VERSION ""

NS_ :

BS_:

BU_: Turbocharger OnBoardDataLogger OffBoardDiagnosticTool2 OffBoardDiagnosticTool1 FileServer ParkingBrakeController SeatControl2 FanDriveController SteeringColumnUnit CommunicationUnitRadio CommunicationUnitSatellite CommunicationUnitCellular PropulsionBatteryCharger ChassisController2 ChassisController1 EngineValveControl AuxiliaryHeater2 AuxiliaryHeater1 ClutchUnit RampControl InformationSystem1 SuspensionSystemController2 OilSensor VehicleDynamicStability ExhaustEmissionController TransmissionDisplay2 TransmissionDisplay1 ClimateControl2 WaterPumpController RearAxleSteeringController LightingOperatorControl SeatController1 IgnitionController2 IgnitionController1 TirePressureController CabController2 CabController1 PneumaticSystemController SuspensionSystemController1 HydraulicPumpController EnduranceBrakingSystem RetarderExhaustEngine2 OnBoardDiagnosticUnit HeadwayController RetarderExhaustEngine1 CabDisplay1 ManagementComputer VirtualTerminal OffVehicleGateway PowerTakeOffFront HitchControl AuxiliaryValveControl BodyController TractorTrailerBridge1 StarterSystem ElectricalSystem VehicleSecurity VehicleNavigation AerodynamicControl ElectricalChargingSystem ClimateControl1 TripRecorder InstrumentCluster SuspensionDriveAxle2 SuspensionDriveAxle1 SuspensionSteerAxle SteeringController FuelSystem CruiseControl RetarderDriveline RetarderEngine BrakesDriveAxle2 BrakesDriveAxle1 BrakesSystemController BrakesSteerAxle AxleDrive2 AxleDrive1 AxleSteering PowerTakeOff ShiftConsoleSecondary ShiftConsolePrimary Transmission2 Transmission1 Engine2 Engine1

BO_ 2566845694 TIRE: 8 Vector__XXX
 SG_ TirePressThresholdDetection_13 m19 : 61|3@1+ (1,0) [0|7] "" Vector__XXX
 SG_ TirePressThresholdDetection_12 m18 : 61|3@1+ (1,0) [0|7] "" Vector__XXX
 SG_ TirePressThresholdDetection_11 m17 : 61|3@1+ (1,0) [0|7] "" Vector__XXX
 SG_ TirePressThresholdDetection_10 m16 : 61|3@1+ (1,0) [0|7] "" Vector__XXX
 SG_ TirePressThresholdDetection_01 m1 : 61|3@1+ (1,0) [0|7] "" Vector__XXX
 SG_ TirePress_33 m51 : 8|8@1+ (4,0) [0|1000] "kPa" Vector__XXX
 SG_ TirePress_32 m50 : 8|8@1+ (4,0) [0|1000] "kPa" Vector__XXX
 SG_ TirePress_31 m49 : 8|8@1+ (4,0) [0|1000] "kPa" Vector__XXX
 SG_ TirePress_30 m48 : 8|8@1+ (4,0) [0|1000] "kPa" Vector__XXX
 SG_ TirePress_23 m35 : 8|8@1+ (4,0) [0|1000] "kPa" Vector__XXX
 SG_ TirePress_22 m34 : 8|8@1+ (4,0) [0|1000] "kPa" Vector__XXX
 SG_ TirePress_21 m33 : 8|8@1+ (4,0) [0|1000] "kPa" Vector__XXX
 SG_ TirePress_20 m32 : 8|8@1+ (4,0) [0|1000] "kPa" Vector__XXX
 SG_ TirePress_13 m19 : 8|8@1+ (4,0) [0|1000] "kPa" Vector__XXX
 SG_ TirePress_12 m18 : 8|8@1+ (4,0) [0|1000] "kPa" Vector__XXX
 SG_ TirePress_11 m17 : 8|8@1+ (4,0) [0|1000] "kPa" Vector__XXX
 SG_ TirePress_10 m16 : 8|8@1+ (4,0) [0|1000] "kPa" Vector__XXX
 SG_ TireAirLeakageRate_33 m51 : 40|16@1+ (0.1,0) [0|6425.5] "Pa/s" Vector__XXX
 SG_ TireAirLeakageRate_32 m50 : 40|16@1+ (0.1,0) [0|6425.5] "Pa/s" Vector__XXX
 SG_ TireAirLeakageRate_31 m49 : 40|16@1+ (0.1,0) [0|6425.5] "Pa/s" Vector__XXX
 SG_ TireAirLeakageRate_30 m48 : 40|16@1+ (0.1,0) [0|6425.5] "Pa/s" Vector__XXX
 SG_ TireAirLeakageRate_23 m35 : 40|16@1+ (0.1,0) [0|6425.5] "Pa/s" Vector__XXX
 SG_ TireAirLeakageRate_22 m34 : 40|16@1+ (0.1,0) [0|6425.5] "Pa/s" Vector__XXX
 SG_ TireAirLeakageRate_21 m33 : 40|16@1+ (0.1,0) [0|6425.5] "Pa/s" Vector__XXX
 SG_ TireAirLeakageRate_20 m32 : 40|16@1+ (0.1,0) [0|6425.5] "Pa/s" Vector__XXX
 SG_ TireAirLeakageRate_13 m19 : 40|16@1+ (0.1,0) [0|6425.5] "Pa/s" Vector__XXX
 SG_ TireAirLeakageRate_12 m18 : 40|16@1+ (0.1,0) [0|6425.5] "Pa/s" Vector__XXX
 SG_ TireAirLeakageRate_11 m17 : 40|16@1+ (0.1,0) [0|6425.5] "Pa/s" Vector__XXX
 SG_ TireAirLeakageRate_10 m16 : 40|16@1+ (0.1,0) [0|6425.5] "Pa/s" Vector__XXX
 SG_ TireAirLeakageRate_01 m1 : 40|16@1+ (0.1,0) [0|6425.5] "Pa/s" Vector__XXX
 SG_ TireAirLeakageRate_00 m0 : 40|16@1+ (0.1,0) [0|6425.5] "Pa/s" Vector__XXX
 SG_ CTIWheelSensorStatus_33 m51 : 32|2@1+ (1,0) [0|3] "" Vector__XXX
 SG_ CTIWheelSensorStatus_32 m50 : 32|2@1+ (1,0) [0|3] "" Vector__XXX
 SG_ CTIWheelSensorStatus_31 m49 : 32|2@1+ (1,0) [0|3] "" Vector__XXX
 SG_ CTIWheelSensorStatus_30 m48 : 32|2@1+ (1,0) [0|3] "" Vector__XXX
 SG_ CTIWheelSensorStatus_23 m35 : 32|2@1+ (1,0) [0|3] "" Vector__XXX
 SG_ CTIWheelSensorStatus_22 m34 : 32|2@1+ (1,0) [0|3] "" Vector__XXX
 SG_ CTIWheelSensorStatus_21 m33 : 32|2@1+ (1,0) [0|3] "" Vector__XXX
 SG_ CTIWheelSensorStatus_20 m32 : 32|2@1+ (1,0) [0|3] "" Vector__XXX
 SG_ CTIWheelSensorStatus_13 m19 : 32|2@1+ (1,0) [0|3] "" Vector__XXX
 SG_ CTIWheelSensorStatus_12 m18 : 32|2@1+ (1,0) [0|3] "" Vector__XXX
 SG_ CTIWheelSensorStatus_11 m17 : 32|2@1+ (1,0) [0|3] "" Vector__XXX
 SG_ CTIWheelSensorStatus_10 m16 : 32|2@1+ (1,0) [0|3] "" Vector__XXX
 SG_ CTIWheelSensorStatus_01 m1 : 32|2@1+ (1,0) [0|3] "" Vector__XXX
 SG_ CTIWheelEndElectricalFault_33 m51 : 36|2@1+ (1,0) [0|3] "" Vector__XXX
 SG_ CTIWheelEndElectricalFault_32 m50 : 36|2@1+ (1,0) [0|3] "" Vector__XXX
 SG_ CTIWheelEndElectricalFault_31 m49 : 36|2@1+ (1,0) [0|3] "" Vector__XXX
 SG_ CTIWheelEndElectricalFault_30 m48 : 36|2@1+ (1,0) [0|3] "" Vector__XXX
 SG_ CTIWheelEndElectricalFault_23 m35 : 36|2@1+ (1,0) [0|3] "" Vector__XXX
 SG_ CTIWheelEndElectricalFault_22 m34 : 36|2@1+ (1,0) [0|3] "" Vector__XXX
 SG_ CTIWheelEndElectricalFault_21 m33 : 36|2@1+ (1,0) [0|3] "" Vector__XXX
 SG_ CTIWheelEndElectricalFault_20 m32 : 36|2@1+ (1,0) [0|3] "" Vector__XXX
 SG_ CTIWheelEndElectricalFault_13 m19 : 36|2@1+ (1,0) [0|3] "" Vector__XXX
 SG_ CTIWheelEndElectricalFault_12 m18 : 36|2@1+ (1,0) [0|3] "" Vector__XXX
 SG_ CTIWheelEndElectricalFault_11 m17 : 36|2@1+ (1,0) [0|3] "" Vector__XXX
 SG_ CTIWheelEndElectricalFault_10 m16 : 36|2@1+ (1,0) [0|3] "" Vector__XXX
 SG_ CTIWheelEndElectricalFault_01 m1 : 36|2@1+ (1,0) [0|3] "" Vector__XXX
 SG_ CTITireStatus_33 m51 : 34|2@1+ (1,0) [0|3] "" Vector__XXX
 SG_ CTITireStatus_32 m50 : 34|2@1+ (1,0) [0|3] "" Vector__XXX
 SG_ CTITireStatus_31 m49 : 34|2@1+ (1,0) [0|3] "" Vector__XXX
 SG_ CTITireStatus_30 m48 : 34|2@1+ (1,0) [0|3] "" Vector__XXX
 SG_ CTITireStatus_23 m35 : 34|2@1+ (1,0) [0|3] "" Vector__XXX
 SG_ CTITireStatus_22 m34 : 34|2@1+ (1,0) [0|3] "" Vector__XXX
 SG_ CTITireStatus_21 m33 : 34|2@1+ (1,0) [0|3] "" Vector__XXX
 SG_ CTITireStatus_20 m32 : 34|2@1+ (1,0) [0|3] "" Vector__XXX
 SG_ CTITireStatus_13 m19 : 34|2@1+ (1,0) [0|3] "" Vector__XXX
 SG_ CTITireStatus_12 m18 : 34|2@1+ (1,0) [0|3] "" Vector__XXX
 SG_ CTITireStatus_11 m17 : 34|2@1+ (1,0) [0|3] "" Vector__XXX
 SG_ CTITireStatus_10 m16 : 34|2@1+ (1,0) [0|3] "" Vector__XXX
 SG_ CTITireStatus_01 m1 : 34|2@1+ (1,0) [0|3] "" Vector__XXX
 SG_ TireTemp_11 m17 : 16|16@1+ (0.03125,-273) [-273|1735] "°C" Vector__XXX
 SG_ TireTemp_33 m51 : 16|16@1+ (0.03125,-273) [-273|1735] "°C" Vector__XXX
 SG_ TireTemp_32 m50 : 16|16@1+ (0.03125,-273) [-273|1735] "°C" Vector__XXX
 SG_ TireTemp_31 m49 : 16|16@1+ (0.03125,-273) [-273|1735] "°C" Vector__XXX
 SG_ TireTemp_30 m48 : 16|16@1+ (0.03125,-273) [-273|1735] "°C" Vector__XXX
 SG_ TireTemp_23 m35 : 16|16@1+ (0.03125,-273) [-273|1735] "°C" Vector__XXX
 SG_ TireTemp_22 m34 : 16|16@1+ (0.03125,-273) [-273|1735] "°C" Vector__XXX
 SG_ TireTemp_21 m33 : 16|16@1+ (0.03125,-273) [-273|1735] "°C" Vector__XXX
 SG_ TireTemp_20 m32 : 16|16@1+ (0.03125,-273) [-273|1735] "°C" Vector__XXX
 SG_ TireTemp_13 m19 : 16|16@1+ (0.03125,-273) [-273|1735] "°C" Vector__XXX
 SG_ TireTemp_12 m18 : 16|16@1+ (0.03125,-273) [-273|1735] "°C" Vector__XXX
 SG_ TireTemp_10 m16 : 16|16@1+ (0.03125,-273) [-273|1735] "°C" Vector__XXX
 SG_ TireTemp_01 m1 : 16|16@1+ (0.03125,-273) [-273|1735] "°C" Vector__XXX
 SG_ TireTemp_00 m0 : 16|16@1+ (0.03125,-273) [-273|1735] "°C" Vector__XXX
 SG_ TirePressThresholdDetection_33 m51 : 61|3@1+ (1,0) [0|7] "" Vector__XXX
 SG_ TirePressThresholdDetection_32 m50 : 61|3@1+ (1,0) [0|7] "" Vector__XXX
 SG_ TirePressThresholdDetection_31 m49 : 61|3@1+ (1,0) [0|7] "" Vector__XXX
 SG_ TirePressThresholdDetection_30 m48 : 61|3@1+ (1,0) [0|7] "" Vector__XXX
 SG_ TirePressThresholdDetection_23 m35 : 61|3@1+ (1,0) [0|7] "" Vector__XXX
 SG_ TirePressThresholdDetection_22 m34 : 61|3@1+ (1,0) [0|7] "" Vector__XXX
 SG_ TirePressThresholdDetection_21 m33 : 61|3@1+ (1,0) [0|7] "" Vector__XXX
 SG_ TirePressThresholdDetection_20 m32 : 61|3@1+ (1,0) [0|7] "" Vector__XXX
 SG_ TirePressThresholdDetection_00 m0 : 61|3@1+ (1,0) [0|7] "" Vector__XXX
 SG_ TirePress_01 m1 : 8|8@1+ (4,0) [0|1000] "kPa" Vector__XXX
 SG_ TirePress_00 m0 : 8|8@1+ (4,0) [0|1000] "kPa" Vector__XXX
 SG_ CTIWheelSensorStatus_00 m0 : 32|2@1+ (1,0) [0|3] "" Vector__XXX
 SG_ CTIWheelEndElectricalFault_00 m0 : 36|2@1+ (1,0) [0|3] "" Vector__XXX
 SG_ CTITireStatus_00 m0 : 34|2@1+ (1,0) [0|3] "" Vector__XXX
 SG_ TireLocation M : 0|8@1+ (1,0) [0|255] "" Vector__XXX

BO_ 2633939966 TFI: 16 Vector__XXX
 SG_ TripFanOnTimeDueToAManualSwitch : 64|32@1+ (0.05,0) [0|210554060.75] "hr" Vector__XXX
 SG_ TripFanOnTime : 0|32@1+ (0.05,0) [0|210554060.75] "hr" Vector__XXX
 SG_ TripFanOnTimeDueToA_CSystem : 96|32@1+ (0.05,0) [0|210554060.75] "hr" Vector__XXX
 SG_ TripFanOnTimeDueToEngSystem : 32|32@1+ (0.05,0) [0|210554060.75] "hr" Vector__XXX

BO_ 2633939710 TDI: 12 Vector__XXX
 SG_ TripDistanceInTopGear : 64|32@1+ (0.125,0) [0|526385151.9] "km" Vector__XXX
 SG_ TripGearDownDistance : 32|32@1+ (0.125,0) [0|526385151.9] "km" Vector__XXX
 SG_ TripDistanceOnVSL : 0|32@1+ (0.125,0) [0|526385151.9] "km" Vector__XXX

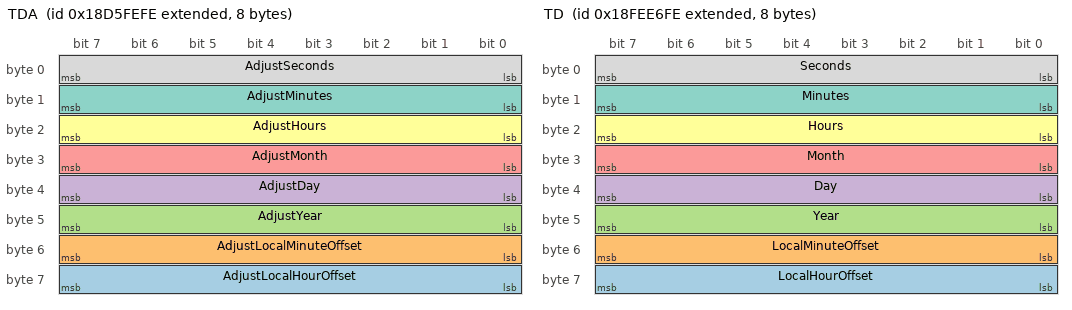
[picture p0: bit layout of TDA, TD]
BO_ 2564161278 TDA: 8 Vector__XXX
 SG_ AdjustLocalHourOffset : 56|8@1+ (1,-125) [-125|125] "hr" Vector__XXX
 SG_ AdjustLocalMinuteOffset : 48|8@1+ (1,-125) [-125|125] "mins" Vector__XXX
 SG_ AdjustYear : 40|8@1+ (1,1985) [1985|2235] "years" Vector__XXX
 SG_ AdjustDay : 32|8@1+ (0.25,0) [0|62.5] "days" Vector__XXX
 SG_ AdjustMonth : 24|8@1+ (1,0) [0|250] "months" Vector__XXX
 SG_ AdjustHours : 16|8@1+ (1,0) [0|250] "hr" Vector__XXX
 SG_ AdjustMinutes : 8|8@1+ (1,0) [0|250] "mins" Vector__XXX
 SG_ AdjustSeconds : 0|8@1+ (0.25,0) [0|62.5] "s" Vector__XXX

BO_ 2566842110 TD: 8 Vector__XXX
 SG_ LocalHourOffset : 56|8@1+ (1,-125) [-125|125] "hr" Vector__XXX
 SG_ LocalMinuteOffset : 48|8@1+ (1,-125) [-125|125] "mins" Vector__XXX
 SG_ Year : 40|8@1+ (1,1985) [1985|2235] "years" Vector__XXX
 SG_ Day : 32|8@1+ (0.25,0) [0|62.5] "days" Vector__XXX
 SG_ Month : 24|8@1+ (1,0) [0|250] "months" Vector__XXX
 SG_ Hours : 16|8@1+ (1,0) [0|250] "hr" Vector__XXX
 SG_ Minutes : 8|8@1+ (1,0) [0|250] "mins" Vector__XXX
 SG_ Seconds : 0|8@1+ (0.25,0) [0|62.5] "s" Vector__XXX

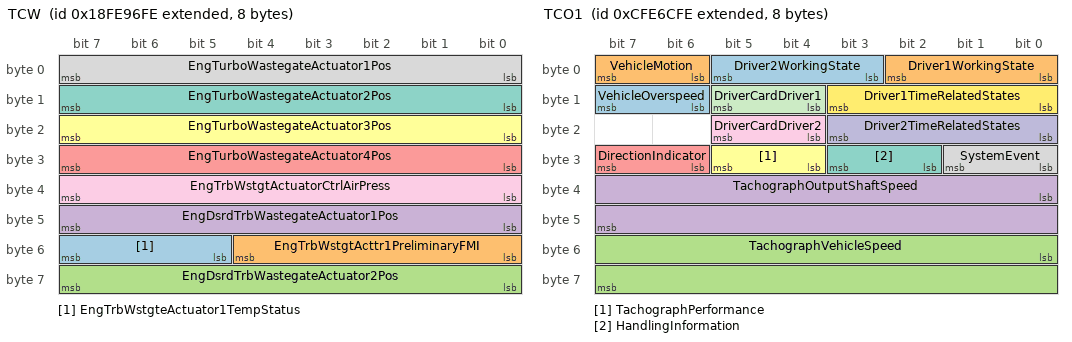
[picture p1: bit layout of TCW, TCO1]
BO_ 2566821630 TCW: 8 Vector__XXX
 SG_ EngTrbWstgteActuator1TempStatus : 53|3@1+ (1,0) [0|7] "" Vector__XXX
 SG_ EngTrbWstgtActtr1PreliminaryFMI : 48|5@1+ (1,0) [0|31] "" Vector__XXX
 SG_ EngDsrdTrbWastegateActuator2Pos : 56|8@1+ (0.4,0) [0|100] "%" Vector__XXX
 SG_ EngDsrdTrbWastegateActuator1Pos : 40|8@1+ (0.4,0) [0|100] "%" Vector__XXX
 SG_ EngTurboWastegateActuator4Pos : 24|8@1+ (0.4,0) [0|100] "%" Vector__XXX
 SG_ EngTurboWastegateActuator3Pos : 16|8@1+ (0.4,0) [0|100] "%" Vector__XXX
 SG_ EngTurboWastegateActuator2Pos : 8|8@1+ (0.4,0) [0|100] "%" Vector__XXX
 SG_ EngTurboWastegateActuator1Pos : 0|8@1+ (0.4,0) [0|100] "%" Vector__XXX
 SG_ EngTrbWstgtActuatorCtrlAirPress : 32|8@1+ (4,0) [0|1000] "kPa" Vector__XXX

BO_ 2365484286 TCO1: 8 Vector__XXX
 SG_ VehicleOverspeed : 14|2@1+ (1,0) [0|3] "" Vector__XXX
 SG_ VehicleMotion : 6|2@1+ (1,0) [0|3] "" Vector__XXX
 SG_ TachographVehicleSpeed : 48|16@1+ (0.00390625,0) [0|250.996] "km/h" Vector__XXX
 SG_ TachographOutputShaftSpeed : 32|16@1+ (0.125,0) [0|8031.875] "rpm" Vector__XXX
 SG_ DirectionIndicator : 30|2@1+ (1,0) [0|3] "" Vector__XXX
 SG_ TachographPerformance : 28|2@1+ (1,0) [0|3] "" Vector__XXX
 SG_ HandlingInformation : 26|2@1+ (1,0) [0|3] "" Vector__XXX
 SG_ SystemEvent : 24|2@1+ (1,0) [0|3] "" Vector__XXX
 SG_ DriverCardDriver2 : 20|2@1+ (1,0) [0|3] "" Vector__XXX
 SG_ Driver2TimeRelatedStates : 16|4@1+ (1,0) [0|15] "" Vector__XXX
 SG_ DriverCardDriver1 : 12|2@1+ (1,0) [0|3] "" Vector__XXX
 SG_ Driver1TimeRelatedStates : 8|4@1+ (1,0) [0|15] "" Vector__XXX
 SG_ Driver2WorkingState : 3|3@1+ (1,0) [0|7] "" Vector__XXX
 SG_ Driver1WorkingState : 0|3@1+ (1,0) [0|7] "" Vector__XXX

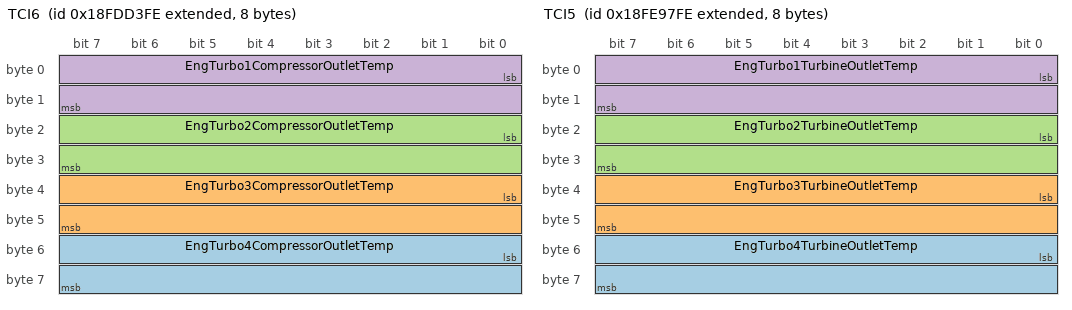
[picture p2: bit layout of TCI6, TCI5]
BO_ 2566771710 TCI6: 8 Vector__XXX
 SG_ EngTurbo4CompressorOutletTemp : 48|16@1+ (0.03125,-273) [-273|1734.96875] "deg C" Vector__XXX
 SG_ EngTurbo3CompressorOutletTemp : 32|16@1+ (0.03125,-273) [-273|1734.96875] "deg C" Vector__XXX
 SG_ EngTurbo2CompressorOutletTemp : 16|16@1+ (0.03125,-273) [-273|1734.96875] "deg C" Vector__XXX
 SG_ EngTurbo1CompressorOutletTemp : 0|16@1+ (0.03125,-273) [-273|1734.96875] "deg C" Vector__XXX

BO_ 2566821886 TCI5: 8 Vector__XXX
 SG_ EngTurbo4TurbineOutletTemp : 48|16@1+ (0.03125,-273) [-273|1734.96875] "deg C" Vector__XXX
 SG_ EngTurbo3TurbineOutletTemp : 32|16@1+ (0.03125,-273) [-273|1734.96875] "deg C" Vector__XXX
 SG_ EngTurbo2TurbineOutletTemp : 16|16@1+ (0.03125,-273) [-273|1734.96875] "deg C" Vector__XXX
 SG_ EngTurbo1TurbineOutletTemp : 0|16@1+ (0.03125,-273) [-273|1734.96875] "deg C" Vector__XXX

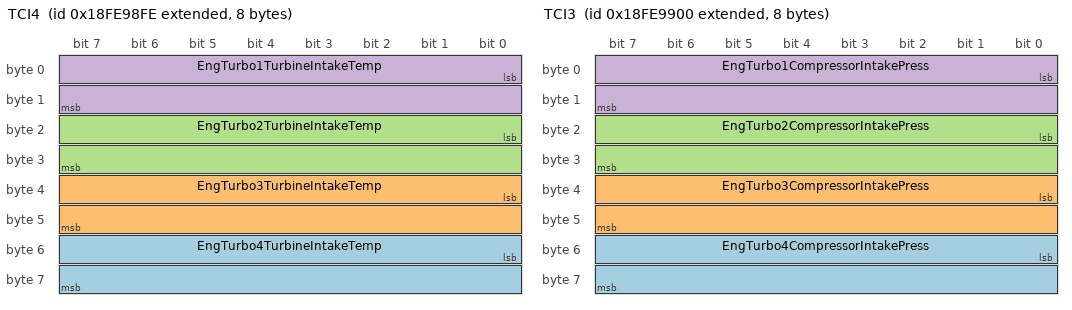
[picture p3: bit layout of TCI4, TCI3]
BO_ 2566822142 TCI4: 8 Vector__XXX
 SG_ EngTurbo4TurbineIntakeTemp : 48|16@1+ (0.03125,-273) [-273|1734.96875] "deg C" Vector__XXX
 SG_ EngTurbo3TurbineIntakeTemp : 32|16@1+ (0.03125,-273) [-273|1734.96875] "deg C" Vector__XXX
 SG_ EngTurbo2TurbineIntakeTemp : 16|16@1+ (0.03125,-273) [-273|1734.96875] "deg C" Vector__XXX
 SG_ EngTurbo1TurbineIntakeTemp : 0|16@1+ (0.03125,-273) [-273|1734.96875] "deg C" Vector__XXX

BO_ 2566822144 TCI3: 8 Vector__XXX
 SG_ EngTurbo4CompressorIntakePress : 48|16@1+ (0.0078125,-250) [-250|251.99] "kPa" Vector__XXX
 SG_ EngTurbo3CompressorIntakePress : 32|16@1+ (0.0078125,-250) [-250|251.99] "kPa" Vector__XXX
 SG_ EngTurbo2CompressorIntakePress : 16|16@1+ (0.0078125,-250) [-250|251.99] "kPa" Vector__XXX
 SG_ EngTurbo1CompressorIntakePress : 0|16@1+ (0.0078125,-250) [-250|251.99] "kPa" Vector__XXX

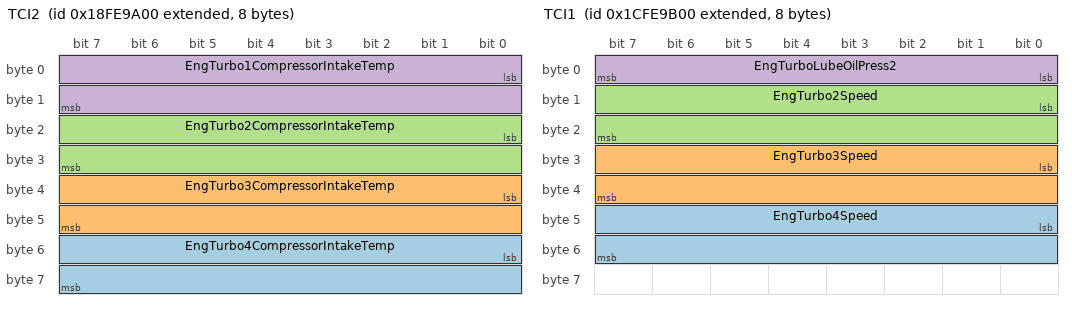
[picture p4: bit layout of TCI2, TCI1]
BO_ 2566822400 TCI2: 8 Vector__XXX
 SG_ EngTurbo4CompressorIntakeTemp : 48|16@1+ (0.03125,-273) [-273|1734.96875] "deg C" Vector__XXX
 SG_ EngTurbo3CompressorIntakeTemp : 32|16@1+ (0.03125,-273) [-273|1734.96875] "deg C" Vector__XXX
 SG_ EngTurbo2CompressorIntakeTemp : 16|16@1+ (0.03125,-273) [-273|1734.96875] "deg C" Vector__XXX
 SG_ EngTurbo1CompressorIntakeTemp : 0|16@1+ (0.03125,-273) [-273|1734.96875] "deg C" Vector__XXX

BO_ 2633931520 TCI1: 8 Vector__XXX
 SG_ EngTurbo4Speed : 40|16@1+ (4,0) [0|257020] "rpm" Vector__XXX
 SG_ EngTurbo3Speed : 24|16@1+ (4,0) [0|257020] "rpm" Vector__XXX
 SG_ EngTurbo2Speed : 8|16@1+ (4,0) [0|257020] "rpm" Vector__XXX
 SG_ EngTurboLubeOilPress2 : 0|8@1+ (4,0) [0|1000] "kPa" Vector__XXX

BO_ 2566802430 TCFG2: 8 Vector__XXX
 SG_ TransTorqueLimit : 0|16@1+ (1,0) [0|64255] "Nm" Vector__XXX

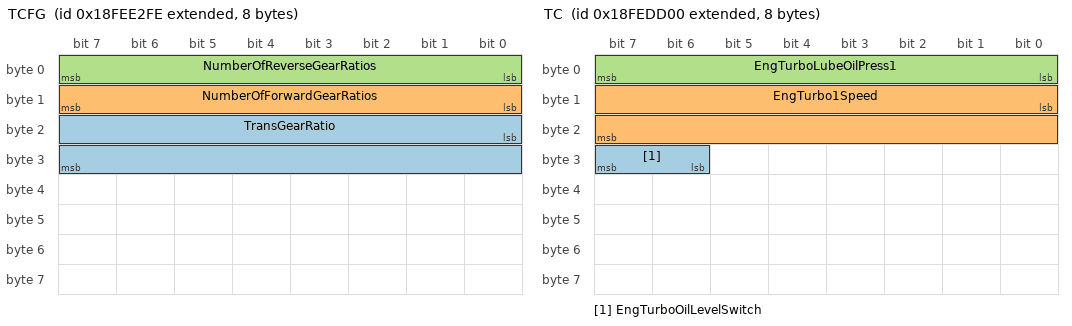
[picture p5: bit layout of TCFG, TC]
BO_ 2566841086 TCFG: 8 Vector__XXX
 SG_ TransGearRatio : 16|16@1+ (0.001,0) [0|64.255] "" Vector__XXX
 SG_ NumberOfForwardGearRatios : 8|8@1+ (1,0) [0|250] "" Vector__XXX
 SG_ NumberOfReverseGearRatios : 0|8@1+ (1,0) [0|250] "" Vector__XXX

BO_ 2348876549 TC1_PRNDL: 8 Vector__XXX
 SG_ TrnsShftSlctorDisplayModeSwitch : 54|2@1+ (1,0) [0|3] "" Vector__XXX
 SG_ TransMode4 : 46|2@1+ (1,0) [0|3] "" Vector__XXX
 SG_ TransMode3 : 44|2@1+ (1,0) [0|3] "" Vector__XXX
 SG_ TransMode2 : 42|2@1+ (1,0) [0|3] "" Vector__XXX
 SG_ TransMode1 : 40|2@1+ (1,0) [0|3] "" Vector__XXX
 SG_ DisengageDiffLockRqCentralRear : 36|2@1+ (1,0) [0|3] "" Vector__XXX
 SG_ DisengageDiffLockRqCentralFront : 34|2@1+ (1,0) [0|3] "" Vector__XXX
 SG_ DisengageDiffLockRqCentral : 32|2@1+ (1,0) [0|3] "" Vector__XXX
 SG_ DisengageDiffLockRqRearAxle2 : 30|2@1+ (1,0) [0|3] "" Vector__XXX
 SG_ DisengageDiffLockRqRearAxle1 : 28|2@1+ (1,0) [0|3] "" Vector__XXX
 SG_ DisengageDiffLockRqFrontAxle2 : 26|2@1+ (1,0) [0|3] "" Vector__XXX
 SG_ DisengageDiffLockRqFrontAxle1 : 24|2@1+ (1,0) [0|3] "" Vector__XXX
 SG_ TransRqedGear : 16|8@1+ (1,-125) [-125|125] "" Vector__XXX
 SG_ RqedPercentClutchSlip : 8|8@1+ (0.4,0) [0|100] "%" Vector__XXX
 SG_ DisengageDrivelineRq : 4|2@1+ (1,0) [0|3] "" Vector__XXX
 SG_ TransGearShiftInhibitRq : 0|2@1+ (1,0) [0|3] "" Vector__XXX
 SG_ TrnsTrqConverterLockupDisableRq : 2|2@1+ (1,0) [0|3] "" Vector__XXX
 SG_ TransRqedLaunchGear : 50|4@1+ (1,0) [0|15] "" Vector__XXX
 SG_ TransReverseGearShiftInhibitRq : 6|2@1+ (1,0) [0|3] "" Vector__XXX
 SG_ TransMode8 : 62|2@1+ (1,0) [0|3] "" Vector__XXX
 SG_ TransMode7 : 60|2@1+ (1,0) [0|3] "" Vector__XXX
 SG_ TransMode6 : 58|2@1+ (1,0) [0|3] "" Vector__XXX
 SG_ TransMode5 : 56|2@1+ (1,0) [0|3] "" Vector__XXX

BO_ 2566839552 TC: 8 Vector__XXX
 SG_ EngTurboOilLevelSwitch : 30|2@1+ (1,0) [0|3] "" Vector__XXX
 SG_ EngTurbo1Speed : 8|16@1+ (4,0) [0|257020] "rpm" Vector__XXX
 SG_ EngTurboLubeOilPress1 : 0|8@1+ (4,0) [0|1000] "kPa" Vector__XXX

BO_ 2633911806 TAVG: 8 Vector__XXX
 SG_ EngTotalAverageFuelEconomy : 16|16@1+ (0.001953125,0) [0|125.5] "km/L" Vector__XXX
 SG_ EngTotalAverageFuelRate : 0|16@1+ (0.05,0) [0|3212.75] "L/h" Vector__XXX

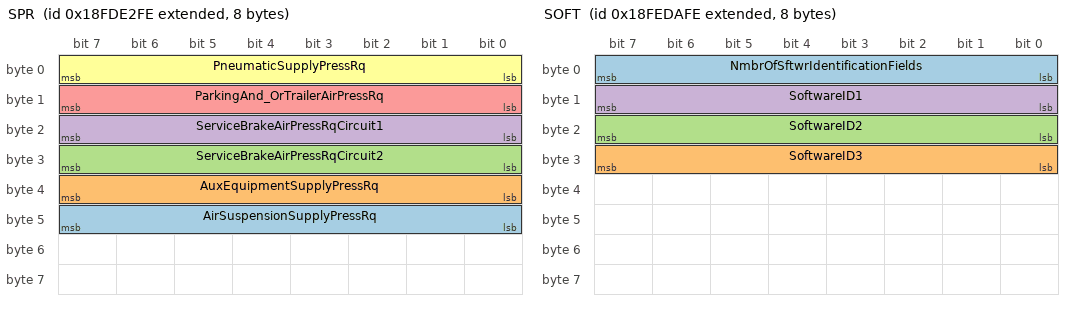
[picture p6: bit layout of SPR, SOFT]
BO_ 2566775550 SPR: 8 Vector__XXX
 SG_ AirSuspensionSupplyPressRq : 40|8@1+ (8,0) [0|2000] "kPa" Vector__XXX
 SG_ AuxEquipmentSupplyPressRq : 32|8@1+ (8,0) [0|2000] "kPa" Vector__XXX
 SG_ ServiceBrakeAirPressRqCircuit2 : 24|8@1+ (8,0) [0|2000] "kPa" Vector__XXX
 SG_ ServiceBrakeAirPressRqCircuit1 : 16|8@1+ (8,0) [0|2000] "kPa" Vector__XXX
 SG_ ParkingAnd_OrTrailerAirPressRq : 8|8@1+ (8,0) [0|2000] "kPa" Vector__XXX
 SG_ PneumaticSupplyPressRq : 0|8@1+ (8,0) [0|2000] "kPa" Vector__XXX

BO_ 2566819838 SP2: 8 Vector__XXX
 SG_ EngExtlShutdownAirSupplyPress : 0|16@1+ (0.5,0) [0|32127.5] "kPa" Vector__XXX

BO_ 2566839038 SOFT: 8 Vector__XXX
 SG_ NmbrOfSftwrIdentificationFields : 0|8@1+ (1,0) [0|250] "steps" Vector__XXX
 SG_ SoftwareID3 : 24|8@1+ (1,0) [0|255] "" Vector__XXX
 SG_ SoftwareID2 : 16|8@1+ (1,0) [0|255] "" Vector__XXX
 SG_ SoftwareID1 : 8|8@1+ (1,0) [0|255] "" Vector__XXX

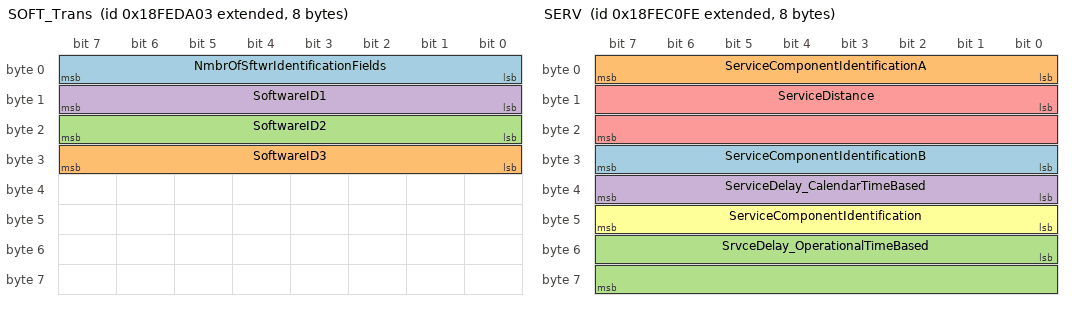
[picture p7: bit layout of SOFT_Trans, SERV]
BO_ 2566838787 SOFT_Trans: 8 Vector__XXX
 SG_ NmbrOfSftwrIdentificationFields : 0|8@1+ (1,0) [0|250] "steps" Vector__XXX
 SG_ SoftwareID3 : 24|8@1+ (1,0) [0|255] "" Vector__XXX
 SG_ SoftwareID2 : 16|8@1+ (1,0) [0|255] "" Vector__XXX
 SG_ SoftwareID1 : 8|8@1+ (1,0) [0|255] "" Vector__XXX

BO_ 2566841344 SHUTDN: 8 Vector__XXX
 SG_ EngOverspeedTest : 54|2@1+ (1,0) [0|3] "" Vector__XXX
 SG_ EngAirShutoffCmdStatus : 52|2@1+ (1,0) [0|3] "" Vector__XXX
 SG_ EngAlarmOutputCmdStatus : 50|2@1+ (1,0) [0|3] "" Vector__XXX
 SG_ EngAlarmAcknowledge : 48|2@1+ (1,0) [0|3] "" Vector__XXX
 SG_ EngProtectionSystemConfig : 46|2@1+ (1,0) [0|3] "" Vector__XXX
 SG_ EngProtectionSystemTimerState : 38|2@1+ (1,0) [0|3] "" Vector__XXX
 SG_ EngPrtectionSystemTimerOverride : 36|2@1+ (1,0) [0|3] "" Vector__XXX
 SG_ EngPrtctnSystmApprchingShutdown : 34|2@1+ (1,0) [0|3] "" Vector__XXX
 SG_ EngWaitToStartLamp : 24|2@1+ (1,0) [0|3] "" Vector__XXX
 SG_ RefrigerantHighPressSwitch : 20|2@1+ (1,0) [0|3] "" Vector__XXX
 SG_ RefrigerantLowPressSwitch : 18|2@1+ (1,0) [0|3] "" Vector__XXX
 SG_ A_CHighPressFanSwitch : 16|2@1+ (1,0) [0|3] "" Vector__XXX
 SG_ EngIdleShutdownTimerFunction : 14|2@1+ (1,0) [0|3] "" Vector__XXX
 SG_ EngIdleShutdownTimerState : 6|2@1+ (1,0) [0|3] "" Vector__XXX
 SG_ EngIdleShutdownTimerOverride : 4|2@1+ (1,0) [0|3] "" Vector__XXX
 SG_ EngIdleShutdownDriverAlertMode : 2|2@1+ (1,0) [0|3] "" Vector__XXX
 SG_ PTOShutdownHasShutdownEng : 58|2@1+ (1,0) [0|3] "" Vector__XXX
 SG_ EngPrtctnSystmHasShutdownEngine : 32|2@1+ (1,0) [0|3] "" Vector__XXX
 SG_ EngIdlShutdownHasShutdownEngine : 0|2@1+ (1,0) [0|3] "" Vector__XXX
 SG_ EngAirShutoffStatus : 56|2@1+ (1,0) [0|3] "" Vector__XXX

BO_ 2566832382 SERV: 8 Vector__XXX
 SG_ ServiceComponentIdentificationB : 24|8@1+ (1,0) [0|250] "ID" Vector__XXX
 SG_ ServiceComponentIdentificationA : 0|8@1+ (1,0) [0|250] "ID" Vector__XXX
 SG_ SrvceDelay_OperationalTimeBased : 48|16@1+ (1,-32127) [-32127|32128] "hr" Vector__XXX
 SG_ ServiceDelay_CalendarTimeBased : 32|8@1+ (1,-125) [-125|125] "weeks" Vector__XXX
 SG_ ServiceDistance : 8|16@1+ (5,-160635) [-160635|160640] "km" Vector__XXX
 SG_ ServiceComponentIdentification : 40|8@1+ (1,0) [0|250] "ID" Vector__XXX

BO_ 2633928446 S2: 8 Vector__XXX
 SG_ TimeSinceLastService : 8|16@1+ (1,-32127) [-32127|32128] "hr" Vector__XXX
 SG_ ServiceComponentIdentification : 0|8@1+ (1,0) [0|250] "ID" Vector__XXX

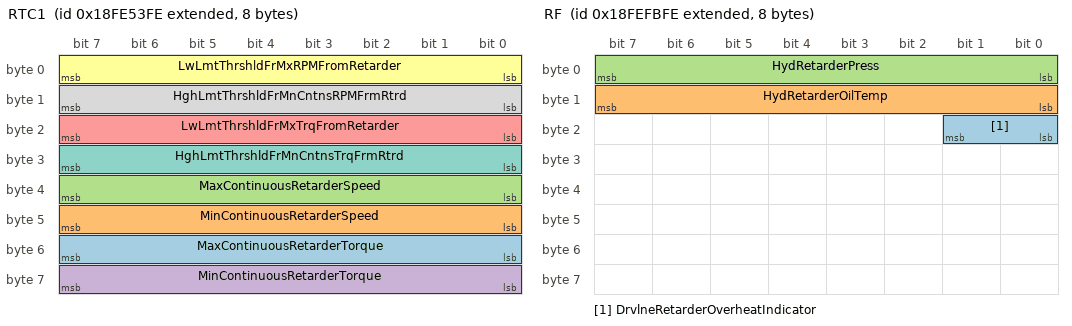
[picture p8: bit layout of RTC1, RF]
BO_ 2566804478 RTC1: 8 Vector__XXX
 SG_ MaxContinuousRetarderTorque : 48|8@1+ (1,-125) [-125|125] "%" Vector__XXX
 SG_ MinContinuousRetarderSpeed : 40|8@1+ (32,0) [0|8000] "rpm" Vector__XXX
 SG_ MaxContinuousRetarderSpeed : 32|8@1+ (32,0) [0|8000] "rpm" Vector__XXX
 SG_ MinContinuousRetarderTorque : 56|8@1+ (1,-125) [-125|125] "%" Vector__XXX
 SG_ LwLmtThrshldFrMxTrqFromRetarder : 16|8@1+ (1,-125) [-125|125] "%" Vector__XXX
 SG_ LwLmtThrshldFrMxRPMFromRetarder : 0|8@1+ (32,0) [0|8000] "rpm" Vector__XXX
 SG_ HghLmtThrshldFrMnCntnsTrqFrmRtrd : 24|8@1+ (1,-125) [-125|125] "%" Vector__XXX
 SG_ HghLmtThrshldFrMnCntnsRPMFrmRtrd : 8|8@1+ (32,0) [0|8000] "rpm" Vector__XXX

BO_ 2566847486 RF: 8 Vector__XXX
 SG_ DrvlneRetarderOverheatIndicator : 16|2@1+ (1,0) [0|3] "" Vector__XXX
 SG_ HydRetarderOilTemp : 8|8@1+ (1,-40) [-40|210] "deg C" Vector__XXX
 SG_ HydRetarderPress : 0|8@1+ (16,0) [0|4000] "kPa" Vector__XXX

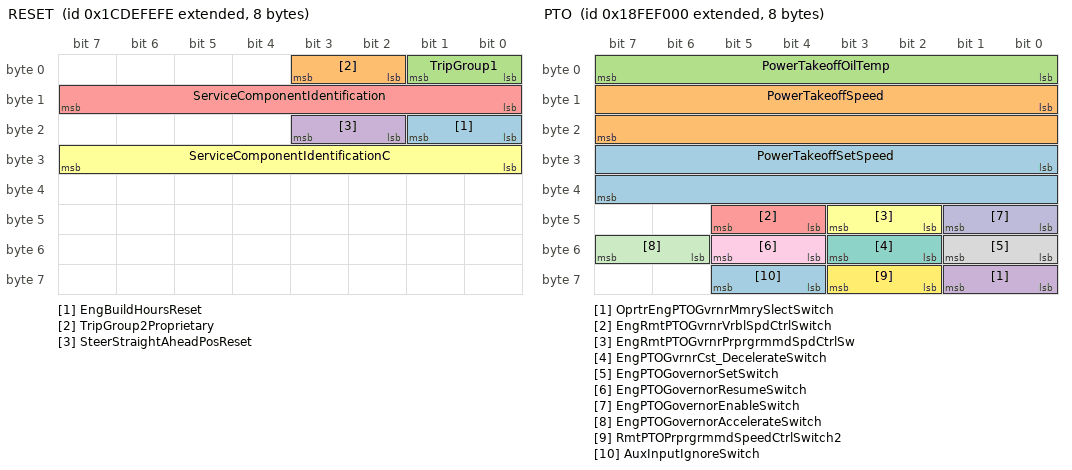
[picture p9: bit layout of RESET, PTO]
BO_ 2631859966 RESET: 8 Vector__XXX
 SG_ EngBuildHoursReset : 16|2@1+ (1,0) [0|3] "" Vector__XXX
 SG_ TripGroup2Proprietary : 2|2@1+ (1,0) [0|3] "" Vector__XXX
 SG_ TripGroup1 : 0|2@1+ (1,0) [0|3] "" Vector__XXX
 SG_ SteerStraightAheadPosReset : 18|2@1+ (1,0) [0|3] "" Vector__XXX
 SG_ ServiceComponentIdentification : 8|8@1+ (1,0) [0|250] "ID" Vector__XXX
 SG_ ServiceComponentIdentificationC : 24|8@1+ (1,0) [0|250] "ID" Vector__XXX

BO_ 2566840591 RC: 19 Vector__XXX
 SG_ PercentTorqueAtPeakTorquePoint5 : 144|8@1+ (1,-125) [-125|125] "%" Vector__XXX
 SG_ ReferenceRetarderTorque : 128|16@1+ (1,0) [0|64255] "Nm" Vector__XXX
 SG_ RetarderSpeedAtPeakTorquePoint5 : 112|16@1+ (0.125,0) [0|8031.875] "rpm" Vector__XXX
 SG_ PercentTorqueAtPoint4 : 104|8@1+ (1,-125) [-125|125] "%" Vector__XXX
 SG_ RetarderSpeedAtPoint4 : 88|16@1+ (0.125,0) [0|8031.875] "rpm" Vector__XXX
 SG_ PercentTorqueAtPoint3 : 80|8@1+ (1,-125) [-125|125] "%" Vector__XXX
 SG_ RetarderSpeedAtPoint3 : 64|16@1+ (0.125,0) [0|8031.875] "rpm" Vector__XXX
 SG_ PercentTorqueAtMaxSpeedPoint2 : 56|8@1+ (1,-125) [-125|125] "%" Vector__XXX
 SG_ MaxRetarderSpeedPoint2 : 40|16@1+ (0.125,0) [0|8031.875] "rpm" Vector__XXX
 SG_ PercentTorqueAtIdlePoint1 : 32|8@1+ (1,-125) [-125|125] "%" Vector__XXX
 SG_ RetarderSpeedAtIdlePoint1 : 16|16@1+ (0.125,0) [0|8031.875] "rpm" Vector__XXX
 SG_ RetarderCtrlMethod : 8|8@1+ (1,0) [0|250] "steps" Vector__XXX
 SG_ RetarderLocation : 4|4@1+ (1,0) [0|15] "" Vector__XXX
 SG_ RetarderType : 0|4@1+ (1,0) [0|15] "" Vector__XXX

BO_ 2633930238 RBI: 8 Vector__XXX
 SG_ EngOperationTimeSinceRebuild : 0|32@1+ (1,0) [0|4211081215] "s" Vector__XXX

BO_ 2566844416 PTO: 8 Vector__XXX
 SG_ PowerTakeoffSetSpeed : 24|16@1+ (0.125,0) [0|8031.875] "rpm" Vector__XXX
 SG_ PowerTakeoffSpeed : 8|16@1+ (0.125,0) [0|8031.875] "rpm" Vector__XXX
 SG_ PowerTakeoffOilTemp : 0|8@1+ (1,-40) [-40|210] "deg C" Vector__XXX
 SG_ OprtrEngPTOGvrnrMmrySlectSwitch : 56|2@1+ (1,0) [0|3] "" Vector__XXX
 SG_ EngRmtPTOGvrnrVrblSpdCtrlSwitch : 44|2@1+ (1,0) [0|3] "" Vector__XXX
 SG_ EngRmtPTOGvrnrPrprgrmmdSpdCtrlSw : 42|2@1+ (1,0) [0|3] "" Vector__XXX
 SG_ EngPTOGvrnrCst_DecelerateSwitch : 50|2@1+ (1,0) [0|3] "" Vector__XXX
 SG_ EngPTOGovernorSetSwitch : 48|2@1+ (1,0) [0|3] "" Vector__XXX
 SG_ EngPTOGovernorResumeSwitch : 52|2@1+ (1,0) [0|3] "" Vector__XXX
 SG_ EngPTOGovernorEnableSwitch : 40|2@1+ (1,0) [0|3] "" Vector__XXX
 SG_ EngPTOGovernorAccelerateSwitch : 54|2@1+ (1,0) [0|3] "" Vector__XXX
 SG_ RmtPTOPrprgrmmdSpeedCtrlSwitch2 : 58|2@1+ (1,0) [0|3] "" Vector__XXX
 SG_ AuxInputIgnoreSwitch : 60|2@1+ (1,0) [0|3] "" Vector__XXX

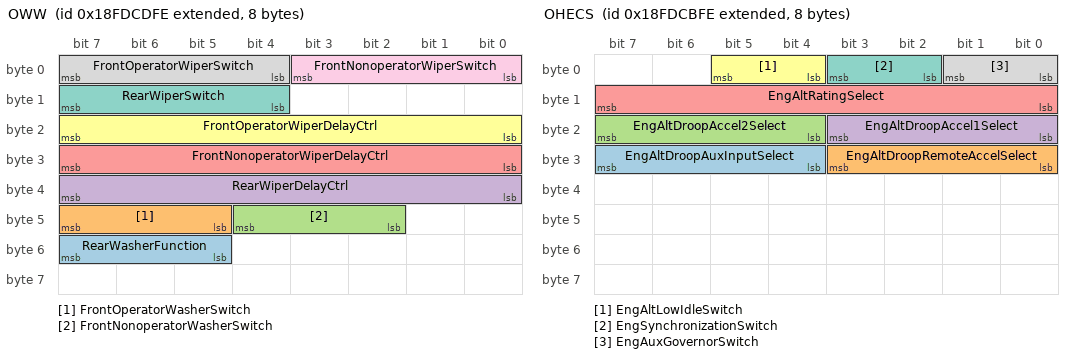
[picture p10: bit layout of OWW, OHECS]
BO_ 2566770174 OWW: 8 Vector__XXX
 SG_ RearWasherFunction : 53|3@1+ (1,0) [0|7] "" Vector__XXX
 SG_ FrontOperatorWasherSwitch : 45|3@1+ (1,0) [0|7] "" Vector__XXX
 SG_ FrontNonoperatorWasherSwitch : 42|3@1+ (1,0) [0|7] "" Vector__XXX
 SG_ RearWiperDelayCtrl : 32|8@1+ (0.4,0) [0|100] "%" Vector__XXX
 SG_ FrontNonoperatorWiperDelayCtrl : 24|8@1+ (0.4,0) [0|100] "%" Vector__XXX
 SG_ FrontOperatorWiperDelayCtrl : 16|8@1+ (0.4,0) [0|100] "%" Vector__XXX
 SG_ RearWiperSwitch : 12|4@1+ (1,0) [0|15] "" Vector__XXX
 SG_ FrontOperatorWiperSwitch : 4|4@1+ (1,0) [0|15] "" Vector__XXX
 SG_ FrontNonoperatorWiperSwitch : 0|4@1+ (1,0) [0|15] "" Vector__XXX

BO_ 2566769662 OHECS: 8 Vector__XXX
 SG_ EngAltDroopAuxInputSelect : 28|4@1+ (1,0) [0|15] "" Vector__XXX
 SG_ EngAltDroopRemoteAccelSelect : 24|4@1+ (1,0) [0|15] "" Vector__XXX
 SG_ EngAltDroopAccel2Select : 20|4@1+ (1,0) [0|15] "" Vector__XXX
 SG_ EngAltDroopAccel1Select : 16|4@1+ (1,0) [0|15] "" Vector__XXX
 SG_ EngAltRatingSelect : 8|8@1+ (1,0) [0|255] "" Vector__XXX
 SG_ EngAltLowIdleSwitch : 4|2@1+ (1,0) [0|3] "" Vector__XXX
 SG_ EngSynchronizationSwitch : 2|2@1+ (1,0) [0|3] "" Vector__XXX
 SG_ EngAuxGovernorSwitch : 0|2@1+ (1,0) [0|3] "" Vector__XXX

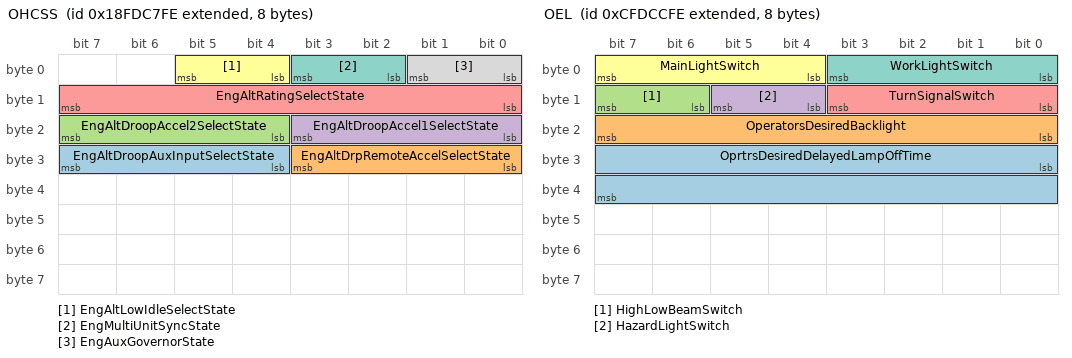
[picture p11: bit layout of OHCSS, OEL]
BO_ 2566768638 OHCSS: 8 Vector__XXX
 SG_ EngAltDroopAuxInputSelectState : 28|4@1+ (1,0) [0|15] "" Vector__XXX
 SG_ EngAltDrpRemoteAccelSelectState : 24|4@1+ (1,0) [0|15] "" Vector__XXX
 SG_ EngAltDroopAccel2SelectState : 20|4@1+ (1,0) [0|15] "" Vector__XXX
 SG_ EngAltDroopAccel1SelectState : 16|4@1+ (1,0) [0|15] "" Vector__XXX
 SG_ EngAltRatingSelectState : 8|8@1+ (1,0) [0|255] "" Vector__XXX
 SG_ EngAltLowIdleSelectState : 4|2@1+ (1,0) [0|3] "" Vector__XXX
 SG_ EngMultiUnitSyncState : 2|2@1+ (1,0) [0|3] "" Vector__XXX
 SG_ EngAuxGovernorState : 0|2@1+ (1,0) [0|3] "" Vector__XXX

BO_ 2365443326 OEL: 8 Vector__XXX
 SG_ OprtrsDesiredDelayedLampOffTime : 24|16@1+ (1,0) [0|64255] "s" Vector__XXX
 SG_ OperatorsDesiredBacklight : 16|8@1+ (0.4,0) [0|100] "%" Vector__XXX
 SG_ HighLowBeamSwitch : 14|2@1+ (1,0) [0|3] "" Vector__XXX
 SG_ HazardLightSwitch : 12|2@1+ (1,0) [0|3] "" Vector__XXX
 SG_ TurnSignalSwitch : 8|4@1+ (1,0) [0|15] "" Vector__XXX
 SG_ MainLightSwitch : 4|4@1+ (1,0) [0|15] "" Vector__XXX
 SG_ WorkLightSwitch : 0|4@1+ (1,0) [0|15] "" Vector__XXX

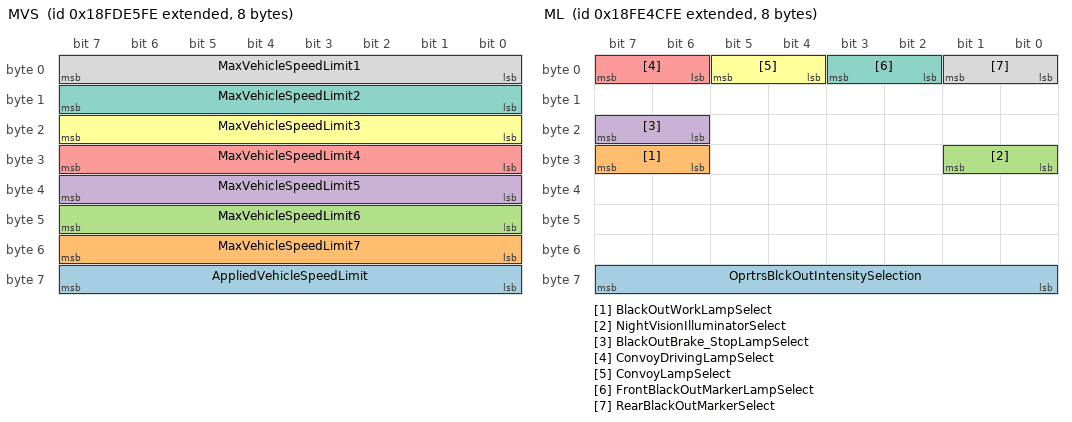
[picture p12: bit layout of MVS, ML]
BO_ 2566776318 MVS: 8 Vector__XXX
 SG_ AppliedVehicleSpeedLimit : 56|8@1+ (1,0) [0|250] "km/h" Vector__XXX
 SG_ MaxVehicleSpeedLimit7 : 48|8@1+ (1,0) [0|250] "km/h" Vector__XXX
 SG_ MaxVehicleSpeedLimit6 : 40|8@1+ (1,0) [0|250] "km/h" Vector__XXX
 SG_ MaxVehicleSpeedLimit5 : 32|8@1+ (1,0) [0|250] "km/h" Vector__XXX
 SG_ MaxVehicleSpeedLimit4 : 24|8@1+ (1,0) [0|250] "km/h" Vector__XXX
 SG_ MaxVehicleSpeedLimit3 : 16|8@1+ (1,0) [0|250] "km/h" Vector__XXX
 SG_ MaxVehicleSpeedLimit2 : 8|8@1+ (1,0) [0|250] "km/h" Vector__XXX
 SG_ MaxVehicleSpeedLimit1 : 0|8@1+ (1,0) [0|250] "km/h" Vector__XXX

BO_ 2566802686 ML: 8 Vector__XXX
 SG_ OprtrsBlckOutIntensitySelection : 56|8@1+ (0.4,0) [0|100] "%" Vector__XXX
 SG_ BlackOutWorkLampSelect : 30|2@1+ (1,0) [0|3] "" Vector__XXX
 SG_ NightVisionIlluminatorSelect : 24|2@1+ (1,0) [0|3] "" Vector__XXX
 SG_ BlackOutBrake_StopLampSelect : 22|2@1+ (1,0) [0|3] "" Vector__XXX
 SG_ ConvoyDrivingLampSelect : 6|2@1+ (1,0) [0|3] "" Vector__XXX
 SG_ ConvoyLampSelect : 4|2@1+ (1,0) [0|3] "" Vector__XXX
 SG_ FrontBlackOutMarkerLampSelect : 2|2@1+ (1,0) [0|3] "" Vector__XXX
 SG_ RearBlackOutMarkerSelect : 0|2@1+ (1,0) [0|3] "" Vector__XXX

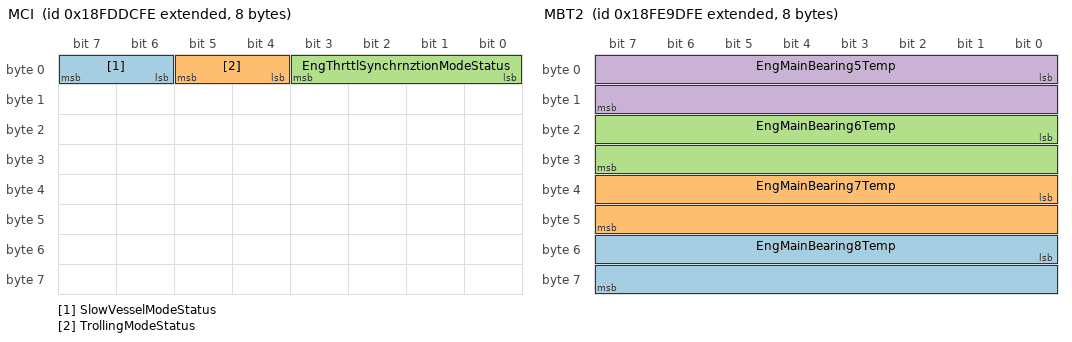
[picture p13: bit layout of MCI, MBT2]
BO_ 2566774014 MCI: 8 Vector__XXX
 SG_ SlowVesselModeStatus : 6|2@1+ (1,0) [0|3] "" Vector__XXX
 SG_ TrollingModeStatus : 4|2@1+ (1,0) [0|3] "" Vector__XXX
 SG_ EngThrttlSynchrnztionModeStatus : 0|4@1+ (1,0) [0|15] "" Vector__XXX

BO_ 2566823166 MBT3: 8 Vector__XXX
 SG_ EngMainBearing11Temp : 32|16@1+ (0.03125,-273) [-273|1734.96875] "deg C" Vector__XXX
 SG_ EngMainBearing10Temp : 16|16@1+ (0.03125,-273) [-273|1734.96875] "deg C" Vector__XXX
 SG_ EngMainBearing9Temp : 0|16@1+ (0.03125,-273) [-273|1734.96875] "deg C" Vector__XXX

BO_ 2566823422 MBT2: 8 Vector__XXX
 SG_ EngMainBearing8Temp : 48|16@1+ (0.03125,-273) [-273|1734.96875] "deg C" Vector__XXX
 SG_ EngMainBearing7Temp : 32|16@1+ (0.03125,-273) [-273|1734.96875] "deg C" Vector__XXX
 SG_ EngMainBearing6Temp : 16|16@1+ (0.03125,-273) [-273|1734.96875] "deg C" Vector__XXX
 SG_ EngMainBearing5Temp : 0|16@1+ (0.03125,-273) [-273|1734.96875] "deg C" Vector__XXX

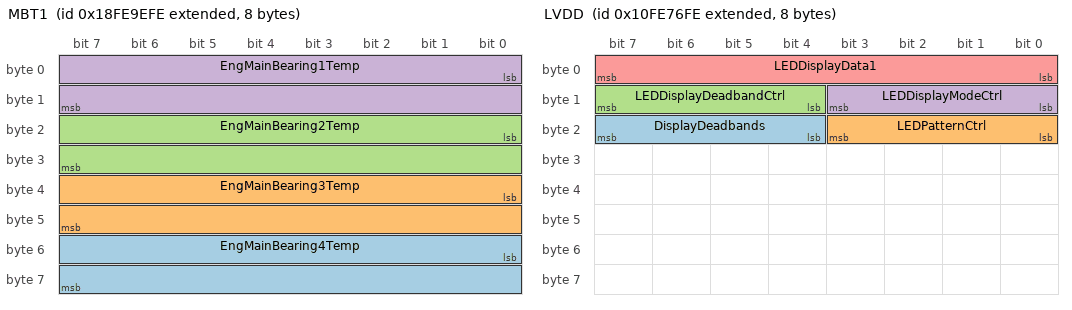
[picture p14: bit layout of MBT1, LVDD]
BO_ 2566823678 MBT1: 8 Vector__XXX
 SG_ EngMainBearing4Temp : 48|16@1+ (0.03125,-273) [-273|1734.96875] "deg C" Vector__XXX
 SG_ EngMainBearing3Temp : 32|16@1+ (0.03125,-273) [-273|1734.96875] "deg C" Vector__XXX
 SG_ EngMainBearing2Temp : 16|16@1+ (0.03125,-273) [-273|1734.96875] "deg C" Vector__XXX
 SG_ EngMainBearing1Temp : 0|16@1+ (0.03125,-273) [-273|1734.96875] "deg C" Vector__XXX

BO_ 2432595710 LVDD: 8 Vector__XXX
 SG_ DisplayDeadbands : 20|4@1+ (1,0) [0|15] "" Vector__XXX
 SG_ LEDPatternCtrl : 16|4@1+ (1,0) [0|15] "" Vector__XXX
 SG_ LEDDisplayDeadbandCtrl : 12|4@1+ (1,0) [0|15] "" Vector__XXX
 SG_ LEDDisplayModeCtrl : 8|4@1+ (1,0) [0|15] "" Vector__XXX
 SG_ LEDDisplayData1 : 0|8@1+ (1,0) [0|255] "" Vector__XXX

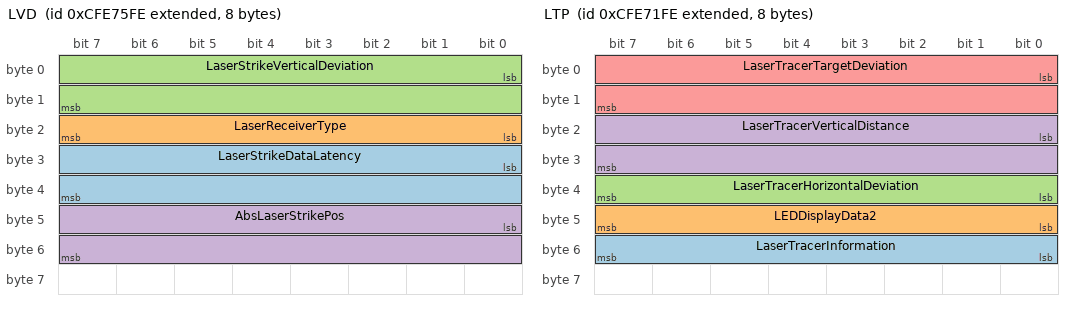
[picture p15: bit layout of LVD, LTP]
BO_ 2365486590 LVD: 8 Vector__XXX
 SG_ LaserStrikeDataLatency : 24|16@1+ (51.2,0) [0|3.289856] "s" Vector__XXX
 SG_ LaserReceiverType : 16|8@1+ (1,0) [0|250] "" Vector__XXX
 SG_ LaserStrikeVerticalDeviation : 0|16@1+ (0.1,-3200) [-3200|3225.5] "mm" Vector__XXX
 SG_ AbsLaserStrikePos : 40|16@1+ (0.1,0) [0|6425.5] "mm" Vector__XXX

BO_ 2365485566 LTP: 8 Vector__XXX
 SG_ LaserTracerInformation : 48|8@1+ (1,0) [0|255] "" Vector__XXX
 SG_ LEDDisplayData2 : 40|8@1+ (1,0) [0|255] "" Vector__XXX
 SG_ LaserTracerHorizontalDeviation : 32|8@1+ (1,0) [0|250] "%" Vector__XXX
 SG_ LaserTracerVerticalDistance : 16|16@1+ (0.1,0) [0|6425.5] "mm" Vector__XXX
 SG_ LaserTracerTargetDeviation : 0|16@1+ (0.1,-3200) [-3200|3225.5] "mm" Vector__XXX

BO_ 2633939454 LTFI: 22 Vector__XXX
 SG_ TripCruiseFuelUsed : 128|32@1+ (0.5,0) [0|2105540607.5] "L" Vector__XXX
 SG_ TripVehicleIdleFuelUsed : 96|32@1+ (0.5,0) [0|2105540607.5] "L" Vector__XXX
 SG_ TripDriveFuelUsed : 0|32@1+ (0.5,0) [0|2105540607.5] "L" Vector__XXX
 SG_ TrpPTOGovernorNonmovingFuelUsed : 64|32@1+ (0.5,0) [0|2105540607.5] "L" Vector__XXX
 SG_ TripPTOGovernorMovingFuelUsed : 32|32@1+ (0.5,0) [0|2105540607.5] "L" Vector__XXX
 SG_ TripDriveFuelEconomy : 160|16@1+ (0.001953125,0) [0|125.5] "km/L" Vector__XXX

BO_ 2365486334 LSP: 8 Vector__XXX
 SG_ BldHeightSetPointHighResolution : 16|32@1+ (100,-209.7152) [-209.7152|211.3929215] "m" Vector__XXX
 SG_ ModifyLevelingSystemSetPoint : 0|16@1+ (0.1,-3200) [-3200|3225.5] "mm" Vector__XXX

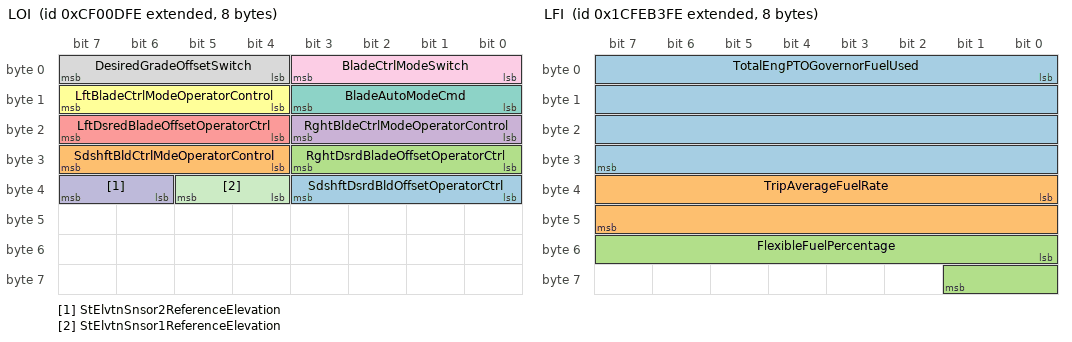
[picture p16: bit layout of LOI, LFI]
BO_ 2364542462 LOI: 8 Vector__XXX
 SG_ SdshftDsrdBldOffsetOperatorCtrl : 32|4@1+ (1,0) [0|15] "" Vector__XXX
 SG_ SdshftBldCtrlMdeOperatorControl : 28|4@1+ (1,0) [0|15] "" Vector__XXX
 SG_ RghtDsrdBladeOffsetOperatorCtrl : 24|4@1+ (1,0) [0|15] "" Vector__XXX
 SG_ RghtBldeCtrlModeOperatorControl : 16|4@1+ (1,0) [0|15] "" Vector__XXX
 SG_ LftDsredBladeOffsetOperatorCtrl : 20|4@1+ (1,0) [0|15] "" Vector__XXX
 SG_ LftBladeCtrlModeOperatorControl : 12|4@1+ (1,0) [0|15] "" Vector__XXX
 SG_ BladeAutoModeCmd : 8|4@1+ (1,0) [0|15] "" Vector__XXX
 SG_ DesiredGradeOffsetSwitch : 4|4@1+ (1,0) [0|15] "" Vector__XXX
 SG_ BladeCtrlModeSwitch : 0|4@1+ (1,0) [0|15] "" Vector__XXX
 SG_ StElvtnSnsor2ReferenceElevation : 38|2@1+ (1,0) [0|3] "" Vector__XXX
 SG_ StElvtnSnsor1ReferenceElevation : 36|2@1+ (1,0) [0|3] "" Vector__XXX

BO_ 2365486078 LMP: 8 Vector__XXX
 SG_ MastPos : 0|16@1+ (0.1,-3200) [-3200|3225.5] "mm" Vector__XXX

BO_ 2633937918 LFI: 8 Vector__XXX
 SG_ TotalEngPTOGovernorFuelUsed : 0|32@1+ (0.5,0) [0|2105540607.5] "L" Vector__XXX
 SG_ TripAverageFuelRate : 32|16@1+ (0.05,0) [0|3212.75] "L/h" Vector__XXX
 SG_ FlexibleFuelPercentage : 48|10@1+ (0.1,0) [0|102] "%" Vector__XXX

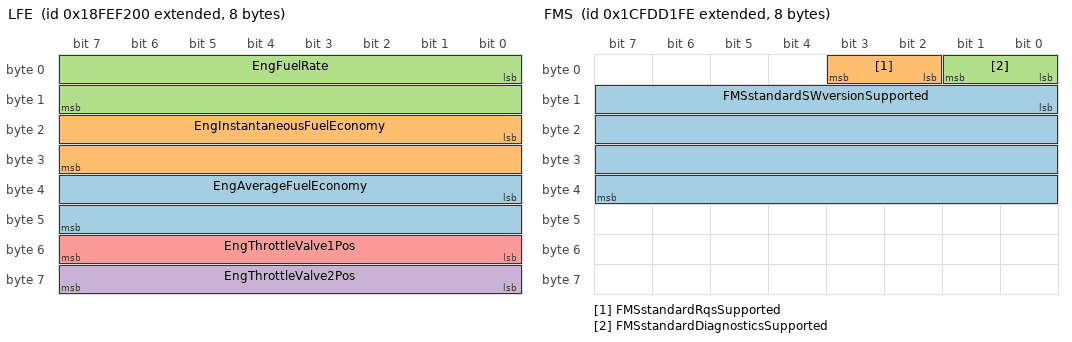
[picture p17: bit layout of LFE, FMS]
BO_ 2566844928 LFE: 8 Vector__XXX
 SG_ EngAverageFuelEconomy : 32|16@1+ (0.001953125,0) [0|125.5] "km/L" Vector__XXX
 SG_ EngInstantaneousFuelEconomy : 16|16@1+ (0.001953125,0) [0|125.5] "km/L" Vector__XXX
 SG_ EngFuelRate : 0|16@1+ (0.05,0) [0|3212.75] "L/h" Vector__XXX
 SG_ EngThrottleValve2Pos : 56|8@1+ (0.4,0) [0|100] "%" Vector__XXX
 SG_ EngThrottleValve1Pos : 48|8@1+ (0.4,0) [0|100] "%" Vector__XXX

BO_ 2566842878 LFC: 8 Vector__XXX
 SG_ EngTotalFuelUsed : 32|32@1+ (0.5,0) [0|2105540607.5] "L" Vector__XXX
 SG_ EngTripFuel : 0|32@1+ (0.5,0) [0|2105540607.5] "L" Vector__XXX

BO_ 2633883646 FWD: 8 Vector__XXX
 SG_ FrontWheelDriveActuatorStatus : 0|2@1+ (1,0) [0|3] "" Vector__XXX

BO_ 2633880062 FMS: 8 Vector__XXX
 SG_ FMSstandardSWversionSupported : 8|32@1+ (1,0) [0|255] "per" Vector__XXX
 SG_ FMSstandardRqsSupported : 2|2@1+ (1,0) [0|3] "" Vector__XXX
 SG_ FMSstandardDiagnosticsSupported : 0|2@1+ (1,0) [0|3] "" Vector__XXX

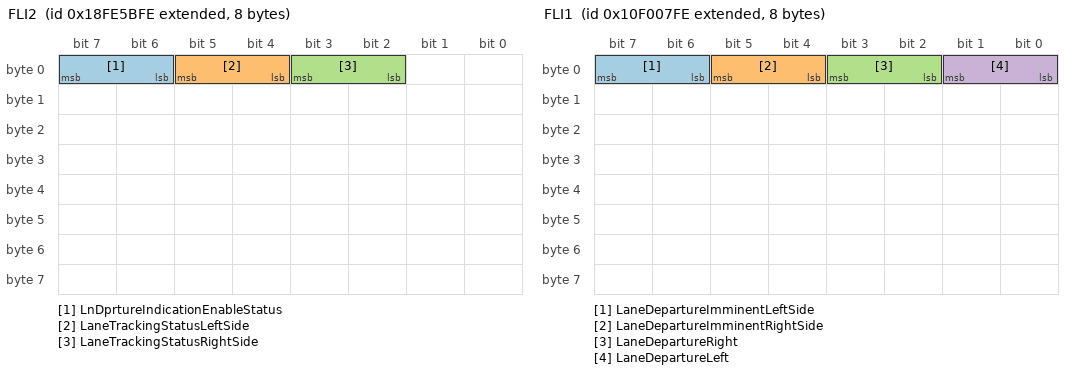
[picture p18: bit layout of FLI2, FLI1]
BO_ 2566806526 FLI2: 8 Vector__XXX
 SG_ LnDprtureIndicationEnableStatus : 6|2@1+ (1,0) [0|3] "" Vector__XXX
 SG_ LaneTrackingStatusLeftSide : 4|2@1+ (1,0) [0|3] "" Vector__XXX
 SG_ LaneTrackingStatusRightSide : 2|2@1+ (1,0) [0|3] "" Vector__XXX

BO_ 2431649790 FLI1: 8 Vector__XXX
 SG_ LaneDepartureImminentLeftSide : 6|2@1+ (1,0) [0|3] "" Vector__XXX
 SG_ LaneDepartureImminentRightSide : 4|2@1+ (1,0) [0|3] "" Vector__XXX
 SG_ LaneDepartureRight : 2|2@1+ (1,0) [0|3] "" Vector__XXX
 SG_ LaneDepartureLeft : 0|2@1+ (1,0) [0|3] "" Vector__XXX

BO_ 2633929214 FL: 8 Vector__XXX
 SG_ EngFuelLeakage2 : 2|2@1+ (1,0) [0|3] "" Vector__XXX
 SG_ EngFuelLeakage1 : 0|2@1+ (1,0) [0|3] "" Vector__XXX

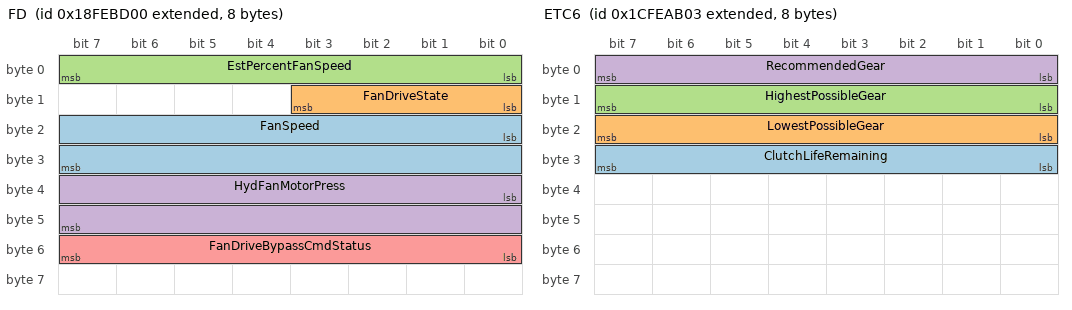
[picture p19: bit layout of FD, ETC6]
BO_ 2566831360 FD: 8 Vector__XXX
 SG_ FanSpeed : 16|16@1+ (0.125,0) [0|8031.875] "rpm" Vector__XXX
 SG_ FanDriveState : 8|4@1+ (1,0) [0|15] "" Vector__XXX
 SG_ EstPercentFanSpeed : 0|8@1+ (0.4,0) [0|100] "%" Vector__XXX
 SG_ HydFanMotorPress : 32|16@1+ (0.5,0) [0|32127.5] "kPa" Vector__XXX
 SG_ FanDriveBypassCmdStatus : 48|8@1+ (0.4,0) [0|100] "%" Vector__XXX

BO_ 2566820094 ETH: 33 Vector__XXX
 SG_ EngTorqueLimit6AxleInput : 248|16@1+ (2,0) [0|128510] "Nm" Vector__XXX
 SG_ EngTorqueLimit5Switch : 232|16@1+ (1,0) [0|64255] "Nm" Vector__XXX
 SG_ EngTorqueLimit4Trans : 216|16@1+ (1,0) [0|64255] "Nm" Vector__XXX
 SG_ EngTorqueLimit3Trans : 200|16@1+ (1,0) [0|64255] "Nm" Vector__XXX
 SG_ TransGearRatio3 : 184|16@1+ (0.01,0) [0|642.55] "" Vector__XXX
 SG_ EngTorqueLimit2Trans : 168|16@1+ (1,0) [0|64255] "Nm" Vector__XXX
 SG_ TransGearRatio2 : 152|16@1+ (0.01,0) [0|642.55] "" Vector__XXX
 SG_ EngTorqueLimit1Trans : 136|16@1+ (1,0) [0|64255] "Nm" Vector__XXX
 SG_ TransGearRatio1 : 120|16@1+ (0.01,0) [0|642.55] "" Vector__XXX
 SG_ EngTorqueLimitFeature : 114|3@1+ (1,0) [0|7] "" Vector__XXX
 SG_ TorqueLimitingFeatureStatus : 112|2@1+ (1,0) [0|3] "" Vector__XXX
 SG_ CalibRecordDurationTime : 80|32@1+ (0.05,0) [0|210554060.75] "hr" Vector__XXX
 SG_ CalibRecordStartYear : 72|8@1+ (1,1985) [1985|2235] "years" Vector__XXX
 SG_ CalibRecordStartDay : 64|8@1+ (0.25,0) [0|62.5] "days" Vector__XXX
 SG_ CalibRecordStartMonth : 56|8@1+ (1,0) [0|250] "months" Vector__XXX
 SG_ EngPeakTorque2 : 40|16@1+ (1,0) [0|64255] "Nm" Vector__XXX
 SG_ EngPeakTorque1 : 24|16@1+ (1,0) [0|64255] "Nm" Vector__XXX
 SG_ EngPower : 8|16@1+ (0.5,0) [0|32127.5] "kW" Vector__XXX
 SG_ NumberOfEngTorqueHistoryRecords : 0|8@1+ (1,0) [0|250] "records" Vector__XXX

BO_ 2364541955 ETC8: 8 Vector__XXX
 SG_ TransClutch_ConverterInputSpeed : 16|16@1+ (0.125,0) [0|8031.875] "rpm" Vector__XXX
 SG_ TransTorqueConverterRatio : 0|16@1+ (0.001,0) [0|64.255] "" Vector__XXX

BO_ 2566801923 ETC7: 8 Vector__XXX
 SG_ TrnsRvrseGearShiftInhibitStatus : 40|2@1+ (1,0) [0|3] "" Vector__XXX
 SG_ TrnsCrrntRangeDisplayBlankState : 0|2@1+ (1,0) [0|3] "" Vector__XXX
 SG_ TransWarningIndicator : 42|2@1+ (1,0) [0|3] "" Vector__XXX
 SG_ TransMode8Indicator : 38|2@1+ (1,0) [0|3] "" Vector__XXX
 SG_ TransMode7Indicator : 36|2@1+ (1,0) [0|3] "" Vector__XXX
 SG_ TransMode6Indicator : 34|2@1+ (1,0) [0|3] "" Vector__XXX
 SG_ TransMode5Indicator : 32|2@1+ (1,0) [0|3] "" Vector__XXX
 SG_ TransRqedGearFeedback : 24|8@1+ (1,-125) [-125|125] "" Vector__XXX
 SG_ TransMode1Indicator : 22|2@1+ (1,0) [0|3] "" Vector__XXX
 SG_ TransMode2Indicator : 20|2@1+ (1,0) [0|3] "" Vector__XXX
 SG_ TransMode3Indicator : 18|2@1+ (1,0) [0|3] "" Vector__XXX
 SG_ TransMode4Indicator : 16|2@1+ (1,0) [0|3] "" Vector__XXX
 SG_ TransShiftInhibitIndicator : 14|2@1+ (1,0) [0|3] "" Vector__XXX
 SG_ TransEngCrankEnable : 12|2@1+ (1,0) [0|3] "" Vector__XXX
 SG_ ActiveShiftConsoleIndicator : 10|2@1+ (1,0) [0|3] "" Vector__XXX
 SG_ TransReadyForBrakeRelease : 8|2@1+ (1,0) [0|3] "" Vector__XXX
 SG_ TransRqedRangeDisplayFlashState : 6|2@1+ (1,0) [0|3] "" Vector__XXX
 SG_ TransRqedRangeDisplayBlankState : 4|2@1+ (1,0) [0|3] "" Vector__XXX
 SG_ TransServiceIndicator : 2|2@1+ (1,0) [0|3] "" Vector__XXX

BO_ 2633935619 ETC6: 8 Vector__XXX
 SG_ ClutchLifeRemaining : 24|8@1+ (0.4,0) [0|100] "%" Vector__XXX
 SG_ LowestPossibleGear : 16|8@1+ (1,-125) [-125|125] "" Vector__XXX
 SG_ HighestPossibleGear : 8|8@1+ (1,-125) [-125|125] "" Vector__XXX
 SG_ RecommendedGear : 0|8@1+ (1,-125) [-125|125] "" Vector__XXX

CM_ BO_ 2566845694 "Tire Condition";
CM_ SG_ 2566845694 TirePressThresholdDetection_13 "Signal indicating the pressure level of the tire.";
CM_ SG_ 2566845694 TirePressThresholdDetection_12 "Signal indicating the pressure level of the tire.";
CM_ SG_ 2566845694 TirePressThresholdDetection_11 "Signal indicating the pressure level of the tire.";
CM_ SG_ 2566845694 TirePressThresholdDetection_10 "Signal indicating the pressure level of the tire.";
CM_ SG_ 2566845694 TirePressThresholdDetection_01 "Signal indicating the pressure level of the tire.";
CM_ SG_ 2566845694 TirePress_33 "Pressure at which air is contained in cavity formed by tire and rim.";
CM_ SG_ 2566845694 TirePress_32 "Pressure at which air is contained in cavity formed by tire and rim.";
CM_ SG_ 2566845694 TirePress_31 "Pressure at which air is contained in cavity formed by tire and rim.";
CM_ SG_ 2566845694 TirePress_30 "Pressure at which air is contained in cavity formed by tire and rim.";
CM_ SG_ 2566845694 TirePress_23 "Pressure at which air is contained in cavity formed by tire and rim.";
CM_ SG_ 2566845694 TirePress_22 "Pressure at which air is contained in cavity formed by tire and rim.";
CM_ SG_ 2566845694 TirePress_21 "Pressure at which air is contained in cavity formed by tire and rim.";
CM_ SG_ 2566845694 TirePress_20 "Pressure at which air is contained in cavity formed by tire and rim.";
CM_ SG_ 2566845694 TirePress_13 "Pressure at which air is contained in cavity formed by tire and rim.";
CM_ SG_ 2566845694 TirePress_12 "Pressure at which air is contained in cavity formed by tire and rim.";
CM_ SG_ 2566845694 TirePress_11 "Pressure at which air is contained in cavity formed by tire and rim.";
CM_ SG_ 2566845694 TirePress_10 "Pressure at which air is contained in cavity formed by tire and rim.";
CM_ SG_ 2566845694 TireAirLeakageRate_33 "The pressure loss rate of a tire.";
CM_ SG_ 2566845694 TireAirLeakageRate_32 "The pressure loss rate of a tire.";
CM_ SG_ 2566845694 TireAirLeakageRate_31 "The pressure loss rate of a tire.";
CM_ SG_ 2566845694 TireAirLeakageRate_30 "The pressure loss rate of a tire.";
CM_ SG_ 2566845694 TireAirLeakageRate_23 "The pressure loss rate of a tire.";
CM_ SG_ 2566845694 TireAirLeakageRate_22 "The pressure loss rate of a tire.";
CM_ SG_ 2566845694 TireAirLeakageRate_21 "The pressure loss rate of a tire.";
CM_ SG_ 2566845694 TireAirLeakageRate_20 "The pressure loss rate of a tire.";
CM_ SG_ 2566845694 TireAirLeakageRate_13 "The pressure loss rate of a tire.";
CM_ SG_ 2566845694 TireAirLeakageRate_12 "The pressure loss rate of a tire.";
CM_ SG_ 2566845694 TireAirLeakageRate_11 "The pressure loss rate of a tire.";
CM_ SG_ 2566845694 TireAirLeakageRate_10 "The pressure loss rate of a tire.";
CM_ SG_ 2566845694 TireAirLeakageRate_01 "The pressure loss rate of a tire.";
CM_ SG_ 2566845694 TireAirLeakageRate_00 "The pressure loss rate of a tire.";
CM_ SG_ 2566845694 CTIWheelSensorStatus_33 "Indicates whether the wheel is being monitored by the CTI controller.";
CM_ SG_ 2566845694 CTIWheelSensorStatus_32 "Indicates whether the wheel is being monitored by the CTI controller.";
CM_ SG_ 2566845694 CTIWheelSensorStatus_31 "Indicates whether the wheel is being monitored by the CTI controller.";
CM_ SG_ 2566845694 CTIWheelSensorStatus_30 "Indicates whether the wheel is being monitored by the CTI controller.";
CM_ SG_ 2566845694 CTIWheelSensorStatus_23 "Indicates whether the wheel is being monitored by the CTI controller.";
CM_ SG_ 2566845694 CTIWheelSensorStatus_22 "Indicates whether the wheel is being monitored by the CTI controller.";
CM_ SG_ 2566845694 CTIWheelSensorStatus_21 "Indicates whether the wheel is being monitored by the CTI controller.";
CM_ SG_ 2566845694 CTIWheelSensorStatus_20 "Indicates whether the wheel is being monitored by the CTI controller.";
CM_ SG_ 2566845694 CTIWheelSensorStatus_13 "Indicates whether the wheel is being monitored by the CTI controller.";
CM_ SG_ 2566845694 CTIWheelSensorStatus_12 "Indicates whether the wheel is being monitored by the CTI controller.";
CM_ SG_ 2566845694 CTIWheelSensorStatus_11 "Indicates whether the wheel is being monitored by the CTI controller.";
CM_ SG_ 2566845694 CTIWheelSensorStatus_10 "Indicates whether the wheel is being monitored by the CTI controller.";
CM_ SG_ 2566845694 CTIWheelSensorStatus_01 "Indicates whether the wheel is being monitored by the CTI controller.";
CM_ SG_ 2566845694 CTIWheelEndElectricalFault_33 "Indicates the status of electrical fault on CTI wheel interface.";
CM_ SG_ 2566845694 CTIWheelEndElectricalFault_32 "Indicates the status of electrical fault on CTI wheel interface.";
CM_ SG_ 2566845694 CTIWheelEndElectricalFault_31 "Indicates the status of electrical fault on CTI wheel interface.";
CM_ SG_ 2566845694 CTIWheelEndElectricalFault_30 "Indicates the status of electrical fault on CTI wheel interface.";
CM_ SG_ 2566845694 CTIWheelEndElectricalFault_23 "Indicates the status of electrical fault on CTI wheel interface.";
CM_ SG_ 2566845694 CTIWheelEndElectricalFault_22 "Indicates the status of electrical fault on CTI wheel interface.";
CM_ SG_ 2566845694 CTIWheelEndElectricalFault_21 "Indicates the status of electrical fault on CTI wheel interface.";
CM_ SG_ 2566845694 CTIWheelEndElectricalFault_20 "Indicates the status of electrical fault on CTI wheel interface.";
CM_ SG_ 2566845694 CTIWheelEndElectricalFault_13 "Indicates the status of electrical fault on CTI wheel interface.";
CM_ SG_ 2566845694 CTIWheelEndElectricalFault_12 "Indicates the status of electrical fault on CTI wheel interface.";
CM_ SG_ 2566845694 CTIWheelEndElectricalFault_11 "Indicates the status of electrical fault on CTI wheel interface.";
CM_ SG_ 2566845694 CTIWheelEndElectricalFault_10 "Indicates the status of electrical fault on CTI wheel interface.";
CM_ SG_ 2566845694 CTIWheelEndElectricalFault_01 "Indicates the status of electrical fault on CTI wheel interface.";
CM_ SG_ 2566845694 CTITireStatus_33 "Indicates the status of the tire.";
CM_ SG_ 2566845694 CTITireStatus_32 "Indicates the status of the tire.";
CM_ SG_ 2566845694 CTITireStatus_31 "Indicates the status of the tire.";
CM_ SG_ 2566845694 CTITireStatus_30 "Indicates the status of the tire.";
CM_ SG_ 2566845694 CTITireStatus_23 "Indicates the status of the tire.";
CM_ SG_ 2566845694 CTITireStatus_22 "Indicates the status of the tire.";
CM_ SG_ 2566845694 CTITireStatus_21 "Indicates the status of the tire.";
CM_ SG_ 2566845694 CTITireStatus_20 "Indicates the status of the tire.";
CM_ SG_ 2566845694 CTITireStatus_13 "Indicates the status of the tire.";
CM_ SG_ 2566845694 CTITireStatus_12 "Indicates the status of the tire.";
CM_ SG_ 2566845694 CTITireStatus_11 "Indicates the status of the tire.";
CM_ SG_ 2566845694 CTITireStatus_10 "Indicates the status of the tire.";
CM_ SG_ 2566845694 CTITireStatus_01 "Indicates the status of the tire.";
CM_ SG_ 2566845694 TireTemp_11 "Temperature at the surface of the tire sidewall.";
CM_ SG_ 2566845694 TireTemp_33 "Temperature at the surface of the tire sidewall.";
CM_ SG_ 2566845694 TireTemp_32 "Temperature at the surface of the tire sidewall.";
CM_ SG_ 2566845694 TireTemp_31 "Temperature at the surface of the tire sidewall.";
CM_ SG_ 2566845694 TireTemp_30 "Temperature at the surface of the tire sidewall.";
CM_ SG_ 2566845694 TireTemp_23 "Temperature at the surface of the tire sidewall.";
CM_ SG_ 2566845694 TireTemp_22 "Temperature at the surface of the tire sidewall.";
CM_ SG_ 2566845694 TireTemp_21 "Temperature at the surface of the tire sidewall.";
CM_ SG_ 2566845694 TireTemp_20 "Temperature at the surface of the tire sidewall.";
CM_ SG_ 2566845694 TireTemp_13 "Temperature at the surface of the tire sidewall.";
CM_ SG_ 2566845694 TireTemp_12 "Temperature at the surface of the tire sidewall.";
CM_ SG_ 2566845694 TireTemp_10 "Temperature at the surface of the tire sidewall.";
CM_ SG_ 2566845694 TireTemp_01 "Temperature at the surface of the tire sidewall.";
CM_ SG_ 2566845694 TireTemp_00 "Temperature at the surface of the tire sidewall.";
CM_ SG_ 2566845694 TirePressThresholdDetection_33 "Signal indicating the pressure level of the tire.";
CM_ SG_ 2566845694 TirePressThresholdDetection_32 "Signal indicating the pressure level of the tire.";
CM_ SG_ 2566845694 TirePressThresholdDetection_31 "Signal indicating the pressure level of the tire.";
CM_ SG_ 2566845694 TirePressThresholdDetection_30 "Signal indicating the pressure level of the tire.";
CM_ SG_ 2566845694 TirePressThresholdDetection_23 "Signal indicating the pressure level of the tire.";
CM_ SG_ 2566845694 TirePressThresholdDetection_22 "Signal indicating the pressure level of the tire.";
CM_ SG_ 2566845694 TirePressThresholdDetection_21 "Signal indicating the pressure level of the tire.";
CM_ SG_ 2566845694 TirePressThresholdDetection_20 "Signal indicating the pressure level of the tire.";
CM_ SG_ 2566845694 TirePressThresholdDetection_00 "Signal indicating the pressure level of the tire.";
CM_ SG_ 2566845694 TirePress_01 "Pressure at which air is contained in cavity formed by tire and rim.";
CM_ SG_ 2566845694 TirePress_00 "Pressure at which air is contained in cavity formed by tire and rim.";
CM_ SG_ 2566845694 CTIWheelSensorStatus_00 "Indicates whether the wheel is being monitored by the CTI controller.";
CM_ SG_ 2566845694 CTIWheelEndElectricalFault_00 "Indicates the status of electrical fault on CTI wheel interface.";
CM_ SG_ 2566845694 CTITireStatus_00 "Indicates the status of the tire.";
CM_ SG_ 2566845694 TireLocation "Identifies which tire is associated with the parametric data in this PGN.";
CM_ BO_ 2633939966 "Trip Fan Information";
CM_ SG_ 2633939966 TripFanOnTimeDueToAManualSwitch "Total time the fan has been on due to manual activation by the operator (i.";
CM_ SG_ 2633939966 TripFanOnTime "Total time the fan has been on (due to an automatic trigger or manual trigger) since the last trip reset.";
CM_ SG_ 2633939966 TripFanOnTimeDueToA_CSystem "Total time the fan has been on due to the A/C system since the last trip reset.";
CM_ SG_ 2633939966 TripFanOnTimeDueToEngSystem "Total time the fan has been on due to engine triggers (i.";
CM_ BO_ 2633939710 "Trip Distance Information";
CM_ SG_ 2633939710 TripDistanceInTopGear "Total distance accumulated while the vehicle has operated in top gear for a calibrated minimum time since the last trip reset.";
CM_ SG_ 2633939710 TripGearDownDistance "Total distance accumulated while the vehicle has operated in the gear which is one gear down from top gear and exceeds";
CM_ SG_ 2633939710 TripDistanceOnVSL "Total distance accumulated while the engine torque mode is road speed governing since the last trip reset.";
CM_ BO_ 2564161278 "Time/Date Adjust";
CM_ SG_ 2564161278 AdjustLocalHourOffset "The hour component for setting the offset between the UTC (Universal Time Coordinate) time and date and a the local";
CM_ SG_ 2564161278 AdjustLocalMinuteOffset "The minute component for setting the offset between the UTC (Universal Time Coordinate) time and date and a the local";
CM_ SG_ 2564161278 AdjustYear "The year component for setting the current calendar date.";
CM_ SG_ 2564161278 AdjustDay "The day component for setting the current calendar date.";
CM_ SG_ 2564161278 AdjustMonth "The month component for setting the current calendar date.";
CM_ SG_ 2564161278 AdjustHours "The hours component for setting the current time of day.";
CM_ SG_ 2564161278 AdjustMinutes "The minutes component for setting the current time of day.";
CM_ SG_ 2564161278 AdjustSeconds "The seconds component for setting the current time of day.";
CM_ BO_ 2566842110 "Time/Date";
CM_ SG_ 2566842110 LocalHourOffset "The hour component of the offset between the UTC (Universal Time Coordinate) time and date and a local time zone time";
CM_ SG_ 2566842110 LocalMinuteOffset "The minute component of the offset between the UTC time and date and a local time zone time and date.";
CM_ SG_ 2566842110 Year "The year component of the current calendar date.";
CM_ SG_ 2566842110 Day "The day component of the current calendar date.";
CM_ SG_ 2566842110 Month "The month component of the current calendar date.";
CM_ SG_ 2566842110 Hours "The hour component of the current time of day.";
CM_ SG_ 2566842110 Minutes "The minutes component of the current time of day.";
CM_ SG_ 2566842110 Seconds "The seconds component of the current time of day.";
CM_ BO_ 2566821630 "Turbocharger Wastegate";
CM_ SG_ 2566821630 EngTrbWstgteActuator1TempStatus "Used to identify the status of the Engine Turbocharger Wastegate Actuator 1 drive circuitry temperature.";
CM_ SG_ 2566821630 EngTrbWstgtActtr1PreliminaryFMI "Used to identify the applicable J1939-73 FMI detected in the Engine Turbocharger Wastegate Actuator 1 by the";
CM_ SG_ 2566821630 EngDsrdTrbWastegateActuator2Pos "The Requested Valve position of the Turbocharger Wastegate Valve 2, commanded by the engine ECM.";
CM_ SG_ 2566821630 EngDsrdTrbWastegateActuator1Pos "The Requested Valve position of the Turbocharger Wastegate Valve 1, commanded by the engine ECM.";
CM_ SG_ 2566821630 EngTurboWastegateActuator4Pos "Position of the wastegate drive.";
CM_ SG_ 2566821630 EngTurboWastegateActuator3Pos "Position of the wastegate drive.";
CM_ SG_ 2566821630 EngTurboWastegateActuator2Pos "Position of the wastegate drive.";
CM_ SG_ 2566821630 EngTurboWastegateActuator1Pos "Position of the wastegate drive.";
CM_ SG_ 2566821630 EngTrbWstgtActuatorCtrlAirPress "Gage pressure of the air used to control the actuator which opens and closes the wastegate valve.";
CM_ BO_ 2365484286 "Tachograph";
CM_ SG_ 2365484286 VehicleOverspeed "Indicates whether the vehicle is exceeding the legal speed limit set in the tachograph.";
CM_ SG_ 2365484286 VehicleMotion "Indicates whether motion of the vehicle is detected or not.";
CM_ SG_ 2365484286 TachographVehicleSpeed "Speed of the vehicle registered by the tachograph.";
CM_ SG_ 2365484286 TachographOutputShaftSpeed "Calculated speed of the transmission output shaft.";
CM_ SG_ 2365484286 DirectionIndicator "Indicates the direction of the vehicle.";
CM_ SG_ 2365484286 TachographPerformance "Indicates the tachograph performance; including electronic or mechanical analysis, instrument analysis, speed sensor";
CM_ SG_ 2365484286 HandlingInformation "Indicates that handling information is present.";
CM_ SG_ 2365484286 SystemEvent "Indicates that a tachograph event has occurred.";
CM_ SG_ 2365484286 DriverCardDriver2 "Indicates the presence of a driver card";
CM_ SG_ 2365484286 Driver2TimeRelatedStates "Indicates if the driver approaches or exceeds working time limits (or other limits).";
CM_ SG_ 2365484286 DriverCardDriver1 "Indicates the presence of a driver card";
CM_ SG_ 2365484286 Driver1TimeRelatedStates "Indicates if the driver approaches or exceeds working time limits (or other limits).";
CM_ SG_ 2365484286 Driver2WorkingState "State of work of the driver.";
CM_ SG_ 2365484286 Driver1WorkingState "State of work of the driver.";
CM_ BO_ 2566771710 "Turbocharger Information 6";
CM_ SG_ 2566771710 EngTurbo4CompressorOutletTemp "Temperature of the air exiting the turbocharger 4 compressor outlet";
CM_ SG_ 2566771710 EngTurbo3CompressorOutletTemp "Temperature of the air exiting the turbocharger 3 compressor outlet";
CM_ SG_ 2566771710 EngTurbo2CompressorOutletTemp "Temperature of the air exiting the turbocharger 2 compressor outlet";
CM_ SG_ 2566771710 EngTurbo1CompressorOutletTemp "Temperature of the air exiting the turbocharger 1 compressor outlet";
CM_ BO_ 2566821886 "Turbocharger Information 5";
CM_ SG_ 2566821886 EngTurbo4TurbineOutletTemp "Temperature of the combustion by-products exiting the turbine side of the turbocharger.";
CM_ SG_ 2566821886 EngTurbo3TurbineOutletTemp "Temperature of the combustion by-products exiting the turbine side of the turbocharger.";
CM_ SG_ 2566821886 EngTurbo2TurbineOutletTemp "Temperature of the combustion by-products exiting the turbine side of the turbocharger.";
CM_ SG_ 2566821886 EngTurbo1TurbineOutletTemp "Temperature of the combustion by-products exiting the turbine side of the turbocharger.";
CM_ BO_ 2566822142 "Turbocharger Information 4";
CM_ SG_ 2566822142 EngTurbo4TurbineIntakeTemp "Temperature of the combustion by-products entering the turbine side of the turbocharger.";
CM_ SG_ 2566822142 EngTurbo3TurbineIntakeTemp "Temperature of the combustion by-products entering the turbine side of the turbocharger.";
CM_ SG_ 2566822142 EngTurbo2TurbineIntakeTemp "Temperature of the combustion by-products entering the turbine side of the turbocharger.";
CM_ SG_ 2566822142 EngTurbo1TurbineIntakeTemp "Temperature of the combustion by-products entering the turbine side of the turbocharger.";
CM_ BO_ 2566822144 "Turbocharger Information 3";
CM_ SG_ 2566822144 EngTurbo4CompressorIntakePress "Gage pressure of the air entering the compressor side of the turbocharger.";
CM_ SG_ 2566822144 EngTurbo3CompressorIntakePress "Gage pressure of the air entering the compressor side of the turbocharger.";
CM_ SG_ 2566822144 EngTurbo2CompressorIntakePress "Gage pressure of the air entering the compressor side of the turbocharger.";
CM_ SG_ 2566822144 EngTurbo1CompressorIntakePress "Gage pressure of the air entering the compressor side of the turbocharger.";
CM_ BO_ 2566822400 "Turbocharger Information 2";
CM_ SG_ 2566822400 EngTurbo4CompressorIntakeTemp "Temperature of the air entering the compressor side of the turbocharger.";
CM_ SG_ 2566822400 EngTurbo3CompressorIntakeTemp "Temperature of the air entering the compressor side of the turbocharger.";
CM_ SG_ 2566822400 EngTurbo2CompressorIntakeTemp "Temperature of the air entering the compressor side of the turbocharger.";
CM_ SG_ 2566822400 EngTurbo1CompressorIntakeTemp "Temperature of the air entering the compressor side of the turbocharger.";
CM_ BO_ 2633931520 "Turbocharger Information 1";
CM_ SG_ 2633931520 EngTurbo4Speed "Rotational velocity of rotor in the turbocharger.";
CM_ SG_ 2633931520 EngTurbo3Speed "Rotational velocity of rotor in the turbocharger.";
CM_ SG_ 2633931520 EngTurbo2Speed "Rotational velocity of rotor in the turbocharger.";
CM_ SG_ 2633931520 EngTurboLubeOilPress2 "Gage pressure of oil in turbocharger lubrication system.";
CM_ BO_ 2566802430 "Transmission Configuration 2";
CM_ SG_ 2566802430 TransTorqueLimit "Parameter provided to the engine from the transmission as a torque limit to be invoked by the engine in the event that";
CM_ BO_ 2566841086 "Transmission Configuration";
CM_ SG_ 2566841086 TransGearRatio "The transmission configuration describes the number of forward gears, the number of reverse gears, and the ratio of each";
CM_ SG_ 2566841086 NumberOfForwardGearRatios "Number of forward gear ratios in the transmission, provided as part of the configuration.";
CM_ SG_ 2566841086 NumberOfReverseGearRatios "Number of reverse gear ratios in the transmission, provided as part of the transmission configuration.";
CM_ BO_ 2348876549 "Transmission Control 1";
CM_ SG_ 2348876549 TrnsShftSlctorDisplayModeSwitch "Status of the operator’s switch used to ‘toggle’ through multiple display modes of a shift selector display.";
CM_ SG_ 2348876549 TransMode4 "Indicates whether transmission mode 4 is enabled.";
CM_ SG_ 2348876549 TransMode3 "Indicates whether transmission mode 3 is enabled.";
CM_ SG_ 2348876549 TransMode2 "Indicates whether transmission mode 2 is enabled.";
CM_ SG_ 2348876549 TransMode1 "Indicates whether transmission mode 1 is enabled.";
CM_ SG_ 2348876549 DisengageDiffLockRqCentralRear "Command signal used to disengage the various differential locks, e.";
CM_ SG_ 2348876549 DisengageDiffLockRqCentralFront "Command signal used to disengage the various differential locks, e.";
CM_ SG_ 2348876549 DisengageDiffLockRqCentral "Command signal used to disengage the various differential locks, e.";
CM_ SG_ 2348876549 DisengageDiffLockRqRearAxle2 "Command signal used to disengage the various differential locks, e.";
CM_ SG_ 2348876549 DisengageDiffLockRqRearAxle1 "Command signal used to disengage the various differential locks, e.";
CM_ SG_ 2348876549 DisengageDiffLockRqFrontAxle2 "Command signal used to disengage the various differential locks, e.";
CM_ SG_ 2348876549 DisengageDiffLockRqFrontAxle1 "Command signal used to disengage the various differential locks, e.";
CM_ SG_ 2348876549 TransRqedGear "Gear requested by the operator, ABS, or engine.";
CM_ SG_ 2348876549 RqedPercentClutchSlip "Parameter which represents the percent clutch slip requested by a device.";
CM_ SG_ 2348876549 DisengageDrivelineRq "Command signal used to simply disengage the driveline, e.";
CM_ SG_ 2348876549 TransGearShiftInhibitRq "Command signal to inhibit gear shifts.";
CM_ SG_ 2348876549 TrnsTrqConverterLockupDisableRq "Command signal to prevent torque converter lockup, which may cause problems in certain circumstances for ASR.";
CM_ SG_ 2348876549 TransRqedLaunchGear "Initial gear for the transmission to start out in when the vehicle is launched from a standing stop, as specified by the";
CM_ SG_ 2348876549 TransReverseGearShiftInhibitRq "Allows devices external to the normal transmission shift selector system to request the transmission to inhibit shifts into";
CM_ SG_ 2348876549 TransMode8 "Indicates whether transmission mode 8 is enabled.";
CM_ SG_ 2348876549 TransMode7 "Indicates whether transmission mode 7 is enabled.";
CM_ SG_ 2348876549 TransMode6 "Indicates whether transmission mode 6 is enabled.";
CM_ SG_ 2348876549 TransMode5 "Indicates whether transmission mode 5 is enabled.";
CM_ BO_ 2566839552 "Turbocharger";
CM_ SG_ 2566839552 EngTurboOilLevelSwitch "Switch signal which indicates the presence of oil at the turbocharger";
CM_ SG_ 2566839552 EngTurbo1Speed "Rotational velocity of rotor in the turbocharger.";
CM_ SG_ 2566839552 EngTurboLubeOilPress1 "Gage pressure of oil in turbocharger lubrication system.";
CM_ BO_ 2633911806 "Total Averaged Information";
CM_ SG_ 2633911806 EngTotalAverageFuelEconomy "Average fuel economy, equal to total vehicle distance divided by total fuel used, over the life of the engine";
CM_ SG_ 2633911806 EngTotalAverageFuelRate "Average fuel rate, equal to total fuel used divided by total engine hours, over the life of the engine";
CM_ BO_ 2566775550 "Supply Pressure Demand";
CM_ SG_ 2566775550 AirSuspensionSupplyPressRq "Command signal to influence the pneumatic pressure in the circuit for the electronically controlled air suspension system.";
CM_ SG_ 2566775550 AuxEquipmentSupplyPressRq "Command signal to influence the pneumatic pressure in the auxiliary circuit.";
CM_ SG_ 2566775550 ServiceBrakeAirPressRqCircuit2 "Command signal to influence the pneumatic pressure in the service brake circuit or reservoir #2.";
CM_ SG_ 2566775550 ServiceBrakeAirPressRqCircuit1 "Command signal to influence the pneumatic pressure in the service brake circuit or reservoir #1.";
CM_ SG_ 2566775550 ParkingAnd_OrTrailerAirPressRq "Command signal to influence the pneumatic pressure in the circuit or reservoir for the parking brake and/or the trailer supply.";
CM_ SG_ 2566775550 PneumaticSupplyPressRq "Command signal to influence the pneumatic pressure in the main reservoir.";
CM_ BO_ 2566819838 "Supply Pressure 2";
CM_ SG_ 2566819838 EngExtlShutdownAirSupplyPress "Pressure of the air used to shut off the fuel supply to the engine.";
CM_ BO_ 2566839038 "Software Identification";
CM_ SG_ 2566839038 NmbrOfSftwrIdentificationFields "Number of software identification designators represented in the software identification parameter group.";
CM_ SG_ 2566839038 SoftwareID3 "Software ID";
CM_ SG_ 2566839038 SoftwareID2 "Software ID";
CM_ SG_ 2566839038 SoftwareID1 "Software ID";
CM_ BO_ 2566838787 "Software Identification";
CM_ BO_ 2566841344 "Shutdown";
CM_ SG_ 2566841344 EngOverspeedTest "The engine overspeed test signal as measured by the reporting ECM.";
CM_ SG_ 2566841344 EngAirShutoffCmdStatus "State signal which indicates when the Air Shutoff driver output is being driven.";
CM_ SG_ 2566841344 EngAlarmOutputCmdStatus "State signal which indicates when the Alarm driver output is being driven.";
CM_ SG_ 2566841344 EngAlarmAcknowledge "The Engine Alarm Acknowledge Input signal as measured by the reporting ECM.";
CM_ SG_ 2566841344 EngProtectionSystemConfig "Parameter which indicates the configuration of the engine shutdown system.";
CM_ SG_ 2566841344 EngProtectionSystemTimerState "Status signal which indicates the current mode of the engine protection system timer system.";
CM_ SG_ 2566841344 EngPrtectionSystemTimerOverride "Status signal which indicates the status of the override feature of the engine protection system timer.";
CM_ SG_ 2566841344 EngPrtctnSystmApprchingShutdown "Status signal which indicates that engine shutdown is imminent.";
CM_ SG_ 2566841344 EngWaitToStartLamp "Lamp signal which indicates that the engine is too cold to start and the operator should wait until the signal becomes";
CM_ SG_ 2566841344 RefrigerantHighPressSwitch "Switch signal which indicates the position of the high pressure switch in the coolant circuit of an air conditioning system.";
CM_ SG_ 2566841344 RefrigerantLowPressSwitch "Switch signal which indicates the position of the low pressure switch in the coolant circuit of an air conditioning system.";
CM_ SG_ 2566841344 A_CHighPressFanSwitch "Switch signal which indicates that the pressure in the coolant circuit of an air conditioning system is high and the fan may";
CM_ SG_ 2566841344 EngIdleShutdownTimerFunction "Parameter which indicates the configuration of the idle shutdown timer system.";
CM_ SG_ 2566841344 EngIdleShutdownTimerState "Status signal which indicates the current mode of operation of the idle shutdown timer system.";
CM_ SG_ 2566841344 EngIdleShutdownTimerOverride "Status signal which indicates the status of the override feature of the idle shutdown timer system.";
CM_ SG_ 2566841344 EngIdleShutdownDriverAlertMode "Status signal which indicates the status of the driver alert mode of the idle shutdown timer system.";
CM_ SG_ 2566841344 PTOShutdownHasShutdownEng "Status signal which identifies whether or not the engine has been shutdown by the PTO shutdown system.";
CM_ SG_ 2566841344 EngPrtctnSystmHasShutdownEngine "Status signal which indicates whether or not the engine protection system has shutdown the engine.";
CM_ SG_ 2566841344 EngIdlShutdownHasShutdownEngine "Status signal which identifies whether or not the engine has been shutdown by the idle shutdown timer system.";
CM_ SG_ 2566841344 EngAirShutoffStatus "State signal which indicates the actual measured position of the Air Shutoff.";
CM_ BO_ 2566832382 "Service Information";
CM_ SG_ 2566832382 ServiceComponentIdentificationB "Identification of component needing service.";
CM_ SG_ 2566832382 ServiceComponentIdentificationA "Identification of component needing service.";
CM_ SG_ 2566832382 SrvceDelay_OperationalTimeBased "The time in vehicle operational time until the next vehicle service inspection is required.";
CM_ SG_ 2566832382 ServiceDelay_CalendarTimeBased "The time in weeks until the next vehicle service inspection is required.";
CM_ SG_ 2566832382 ServiceDistance "The distance which can be traveled by the vehicle before the next service inspection is required.";
CM_ SG_ 2566832382 ServiceComponentIdentification "Identification of component needing service.";
CM_ BO_ 2633928446 "Service 2";
CM_ SG_ 2633928446 TimeSinceLastService "The vehicle operation time since the last service was performed.";
CM_ SG_ 2633928446 ServiceComponentIdentification "Identification of component needing service.";
CM_ BO_ 2566804478 "Retarder Continuous Torque & Speed Limit";
CM_ SG_ 2566804478 MaxContinuousRetarderTorque "Applied limit for maximum continuous retarder torque.";
CM_ SG_ 2566804478 MinContinuousRetarderSpeed "Applied limit for minimum continuous retarder RPM";
CM_ SG_ 2566804478 MaxContinuousRetarderSpeed "Applied limit for maximum continuous retarder RPM";
CM_ SG_ 2566804478 MinContinuousRetarderTorque "Applied limit for minimum continuous retarder torque";
CM_ SG_ 2566804478 LwLmtThrshldFrMxTrqFromRetarder "Minimum allowable value for maximum continuous retarder torque.";
CM_ SG_ 2566804478 LwLmtThrshldFrMxRPMFromRetarder "Minimum allowable value for maximum continuous retarder speed";
CM_ SG_ 2566804478 HghLmtThrshldFrMnCntnsTrqFrmRtrd "Maximum allowable value for minimum continuous retarder torque.";
CM_ SG_ 2566804478 HghLmtThrshldFrMnCntnsRPMFrmRtrd "Maximum allowable value for minimum continuous retarder speed";
CM_ BO_ 2566847486 "Retarder fluids";
CM_ SG_ 2566847486 DrvlneRetarderOverheatIndicator "Signal from the driveline retarder indicating that its fluid temperature is above normal acceptable limits, and as a result,";
CM_ SG_ 2566847486 HydRetarderOilTemp "Temperature of oil found in a hydraulic retarder.";
CM_ SG_ 2566847486 HydRetarderPress "Gage pressure of oil in hydraulic retarder system.";
CM_ BO_ 2631859966 "Reset";
CM_ SG_ 2631859966 EngBuildHoursReset "Command signal used to reset the engine rebuild hours.";
CM_ SG_ 2631859966 TripGroup2Proprietary "Command signal used to reset proprietary parameters associated with a trip but not defined within this document.";
CM_ SG_ 2631859966 TripGroup1 "Command signal used to reset the PGNs and parameters as defined in Table SPN988_A.";
CM_ SG_ 2631859966 SteerStraightAheadPosReset "Used to reset the straight ahead position for a steering sensor in the steering column or a steering controller's straight";
CM_ SG_ 2631859966 ServiceComponentIdentification "Identification of component needing service.";
CM_ SG_ 2631859966 ServiceComponentIdentificationC "Identification of component needing service.";
CM_ BO_ 2566840591 "Retarder Configuration";
CM_ SG_ 2566840591 PercentTorqueAtPeakTorquePoint5 "The torque limit that indicates the available retarder torque which can be provided by the retarder at point 5 of the retarder";
CM_ SG_ 2566840591 ReferenceRetarderTorque "This parameter is the 100% reference value for all defined indicated retarder torque parameters.";
CM_ SG_ 2566840591 RetarderSpeedAtPeakTorquePoint5 "Please reference PGN 65249";
CM_ SG_ 2566840591 PercentTorqueAtPoint4 "The torque limit that indicates the available retarder torque which can be provided by the retarder at points 3 and 4 of the";
CM_ SG_ 2566840591 RetarderSpeedAtPoint4 "Retarder speed of point 4 of the engine retarder torque map.";
CM_ SG_ 2566840591 PercentTorqueAtPoint3 "The torque limit that indicates the available retarder torque which can be provided by the retarder at points 3 and 4 of the";
CM_ SG_ 2566840591 RetarderSpeedAtPoint3 "Retarder speed of point 3 of the engine retarder torque map.";
CM_ SG_ 2566840591 PercentTorqueAtMaxSpeedPoint2 "The torque limit that indicates the available retarder torque which can be provided by the retarder at its maximum speed.";
CM_ SG_ 2566840591 MaxRetarderSpeedPoint2 "Maximum speed of retarder (Please reference PGN 65249).";
CM_ SG_ 2566840591 PercentTorqueAtIdlePoint1 "The torque limit that indicates the available retarder torque which can be provided by the retarder at idle speed.";
CM_ SG_ 2566840591 RetarderSpeedAtIdlePoint1 "Please reference PGN 65249";
CM_ SG_ 2566840591 RetarderCtrlMethod "This parameter identifies the number of steps used by the retarder.";
CM_ SG_ 2566840591 RetarderLocation "This parameter defines whether the “torque/speed curve” defined by the retarder configuration message (PGN 65249) is";
CM_ SG_ 2566840591 RetarderType "A vehicle retarder is a supplementary device to the wheel brakes for the driver to better control the vehicle.";
CM_ BO_ 2633930238 "Rebuild Information";
CM_ SG_ 2633930238 EngOperationTimeSinceRebuild "The time in engine operation since the last engine rebuild.";
CM_ BO_ 2566844416 "Power Takeoff Information";
CM_ SG_ 2566844416 PowerTakeoffSetSpeed "Rotational velocity selected by operator for device used to transmit engine power to auxiliary equipment.";
CM_ SG_ 2566844416 PowerTakeoffSpeed "Rotational velocity of device used to transmit engine power to auxiliary equipment.";
CM_ SG_ 2566844416 PowerTakeoffOilTemp "Temperature of lubricant in device used to transmit engine power to auxiliary equipment.";
CM_ SG_ 2566844416 OprtrEngPTOGvrnrMmrySlectSwitch "Measured state of the operator’s engine PTO governor memory select switch.";
CM_ SG_ 2566844416 EngRmtPTOGvrnrVrblSpdCtrlSwitch "Switch signal which indicates that the remote PTO governor toggle switch is in the enabled (ON) position.";
CM_ SG_ 2566844416 EngRmtPTOGvrnrPrprgrmmdSpdCtrlSw "Switch signal which indicates that the remote PTO governor toggle switch is in the enabled (ON) position.";
CM_ SG_ 2566844416 EngPTOGvrnrCst_DecelerateSwitch "Switch signal of the PTO control activator which indicates that the activator is in the position to \"coast/decelerate\" the PTO";
CM_ SG_ 2566844416 EngPTOGovernorSetSwitch "Switch signal of the PTO control activator which indicates that the activator is in the position to \"set\" the engine PTO";
CM_ SG_ 2566844416 EngPTOGovernorResumeSwitch "Switch signal of the PTO control activator which indicates that the activator is in the position to \"resume\" a previously";
CM_ SG_ 2566844416 EngPTOGovernorEnableSwitch "Switch signal which indicates that the PTO governor toggle switch is in the enabled (ON) position and therefore it is";
CM_ SG_ 2566844416 EngPTOGovernorAccelerateSwitch "Switch signal of the PTO control activator which indicates that the activator is in the position to \"accelerate\" the PTO";
CM_ SG_ 2566844416 RmtPTOPrprgrmmdSpeedCtrlSwitch2 "Switch signal which indicates that the remote PTO toggle switch #2 is in the enabled (ON) position.";
CM_ SG_ 2566844416 AuxInputIgnoreSwitch "Switch signal which overrides other switch input's ability to kick out of an engine's operating condition.";
CM_ BO_ 2566770174 "Operator Wiper and Washer Controls Message";
CM_ SG_ 2566770174 RearWasherFunction "State of operation selected by operator switch for the rear washer.";
CM_ SG_ 2566770174 FrontOperatorWasherSwitch "State of operation selected by operator switch for the washer in front of the operator position.";
CM_ SG_ 2566770174 FrontNonoperatorWasherSwitch "State of operation selected by operator switch for the front washer not in front of the operator position.";
CM_ SG_ 2566770174 RearWiperDelayCtrl "Time between cycles of the rear wiper (i.";
CM_ SG_ 2566770174 FrontNonoperatorWiperDelayCtrl "Time between cycles of the front non-operator side wiper (i.";
CM_ SG_ 2566770174 FrontOperatorWiperDelayCtrl "Time between cycles of the front operator side wiper (i.";
CM_ SG_ 2566770174 RearWiperSwitch "State of operation selected by operator switch for the rear wiper.";
CM_ SG_ 2566770174 FrontOperatorWiperSwitch "State of operation selected by operator switch for the Wiper in front of the operator position.";
CM_ SG_ 2566770174 FrontNonoperatorWiperSwitch "State of operation selected by operator switch for the front wiper not in front of the operator position.";
CM_ BO_ 2566769662 "Off-Highway Engine Control Selection";
CM_ SG_ 2566769662 EngAltDroopAuxInputSelect "In some off-highway applications it may be desirable to have multiple droop settings available across the range of engine";
CM_ SG_ 2566769662 EngAltDroopRemoteAccelSelect "In some off-highway applications it may be desirable to have multiple droop settings available across the range of engine";
CM_ SG_ 2566769662 EngAltDroopAccel2Select "Same description as Engine Alternate Droop Accelerator 1 Select (SPN 2881) except that the selections may apply to";
CM_ SG_ 2566769662 EngAltDroopAccel1Select "In some off-highway applications it may be desirable to have multiple droop settings available across the range of engine";
CM_ SG_ 2566769662 EngAltRatingSelect "In some off-highway applications it may be desirable to have multiple engine ratings available for selection by the operator.";
CM_ SG_ 2566769662 EngAltLowIdleSwitch "Operator switch which selects between two low idle speeds, default and alternate.";
CM_ SG_ 2566769662 EngSynchronizationSwitch "This is the On/Off operation of the Multiple Unit Synchronization functionality.";
CM_ SG_ 2566769662 EngAuxGovernorSwitch "This is the On/Off operation of the Auxiliary Governor feature switch.";
CM_ BO_ 2566768638 "Off-Highway Engine Control Selection States";
CM_ SG_ 2566768638 EngAltDroopAuxInputSelectState "In some off-highway applications it may be desirable to have multiple droop settings available across the range of engine";
CM_ SG_ 2566768638 EngAltDrpRemoteAccelSelectState "In some off-highway applications it may be desirable to have multiple droop settings available across the range of engine";
CM_ SG_ 2566768638 EngAltDroopAccel2SelectState "In some off-highway applications it may be desirable to have multiple droop settings available across the range of engine";
CM_ SG_ 2566768638 EngAltDroopAccel1SelectState "In some off-highway applications it may be desirable to have multiple droop settings available across the range of engine";
CM_ SG_ 2566768638 EngAltRatingSelectState "In some off-highway applications it may be desirable to have multiple engine ratings available for selection by the operator.";
CM_ SG_ 2566768638 EngAltLowIdleSelectState "In many applications, it is desirable that an alternate low idle speed setting be made available via switch input.";
CM_ SG_ 2566768638 EngMultiUnitSyncState "This feature is widely used in Industry to operate multiple engines from a single command source.";
CM_ SG_ 2566768638 EngAuxGovernorState "This is the Engine Auxiliary Governor feature.";
CM_ BO_ 2365443326 "Operators External Light Controls Message";
CM_ SG_ 2365443326 OprtrsDesiredDelayedLampOffTime "A 16 bit parameter to be associated with Delayed Off position (1000 binary) of the Main Light Switch.";
CM_ SG_ 2365443326 OperatorsDesiredBacklight "A 8 bit parameter to indicate the level of back lighting the operator has selected for displays.";
CM_ SG_ 2365443326 HighLowBeamSwitch "A 2 bit parameter to indicate the selected position of the operator's high/low beam select switch.";
CM_ SG_ 2365443326 HazardLightSwitch "A 2 bit parameter to indicate the selected position of the operator's hazard light switch.";
CM_ SG_ 2365443326 TurnSignalSwitch "A 4 bit parameter to indicate the selected position of the operator's turn signal switch.";
CM_ SG_ 2365443326 MainLightSwitch "A 4 bit parameter to indicate the selected position of the operator's main light switch.";
CM_ SG_ 2365443326 WorkLightSwitch "A 4 bit parameter to indicate the selected position of the operator's work light switch.";
CM_ BO_ 2566776318 "Maximum Vehicle Speed Limit Status";
CM_ SG_ 2566776318 AppliedVehicleSpeedLimit "The vehicle speed limit in effect.";
CM_ SG_ 2566776318 MaxVehicleSpeedLimit7 "The highest of the seven lowest vehicle speed limits";
CM_ SG_ 2566776318 MaxVehicleSpeedLimit6 "The highest of the six lowest vehicle speed limits";
CM_ SG_ 2566776318 MaxVehicleSpeedLimit5 "The highest of the five lowest vehicle speed limits";
CM_ SG_ 2566776318 MaxVehicleSpeedLimit4 "The highest of the four lowest vehicle speed limits";
CM_ SG_ 2566776318 MaxVehicleSpeedLimit3 "The highest of the three lowest vehicle speed limits";
CM_ SG_ 2566776318 MaxVehicleSpeedLimit2 "The highest of the two lowest vehicle speed limits";
CM_ SG_ 2566776318 MaxVehicleSpeedLimit1 "The lowest Maximum Vehicle Speed Limit.";
CM_ BO_ 2566802686 "Military Lighting Command";
CM_ SG_ 2566802686 OprtrsBlckOutIntensitySelection "Operators Selection of lamp intensity in black out mode.";
CM_ SG_ 2566802686 BlackOutWorkLampSelect "Black Out Work Lamp Selection";
CM_ SG_ 2566802686 NightVisionIlluminatorSelect "Night Vision Illuminator Selection";
CM_ SG_ 2566802686 BlackOutBrake_StopLampSelect "Black Out Brake/Stop Lamp Selection";
CM_ SG_ 2566802686 ConvoyDrivingLampSelect "Black Out Convoy Driving Lamp Selection";
CM_ SG_ 2566802686 ConvoyLampSelect "Black Out Convoy Lamp Selection";
CM_ SG_ 2566802686 FrontBlackOutMarkerLampSelect "Front Black Out Marker Lamp Selection";
CM_ SG_ 2566802686 RearBlackOutMarkerSelect "Rear Black Out Marker Selection";
CM_ BO_ 2566774014 "Marine Control Information";
CM_ SG_ 2566774014 SlowVesselModeStatus "The status of the Slow Vessel Mode.";
CM_ SG_ 2566774014 TrollingModeStatus "The status of the Trolling Mode.";
CM_ SG_ 2566774014 EngThrttlSynchrnztionModeStatus "The status of the Throttle Synchronization Mode.";
CM_ BO_ 2566823166 "Main Bearing Temperature 3";
CM_ SG_ 2566823166 EngMainBearing11Temp "Temperature of the main bearing which supports the crankshaft of the engine.";
CM_ SG_ 2566823166 EngMainBearing10Temp "Temperature of the main bearing which supports the crankshaft of the engine.";
CM_ SG_ 2566823166 EngMainBearing9Temp "Temperature of the main bearing which supports the crankshaft of the engine.";
CM_ BO_ 2566823422 "Main Bearing Temperature 2";
CM_ SG_ 2566823422 EngMainBearing8Temp "Temperature of the main bearing which supports the crankshaft of the engine.";
CM_ SG_ 2566823422 EngMainBearing7Temp "Temperature of the main bearing which supports the crankshaft of the engine.";
CM_ SG_ 2566823422 EngMainBearing6Temp "Temperature of the main bearing which supports the crankshaft of the engine.";
CM_ SG_ 2566823422 EngMainBearing5Temp "Temperature of the main bearing which supports the crankshaft of the engine.";
CM_ BO_ 2566823678 "Main Bearing Temperature 1";
CM_ SG_ 2566823678 EngMainBearing4Temp "Temperature of the main bearing which supports the crankshaft of the engine.";
CM_ SG_ 2566823678 EngMainBearing3Temp "Temperature of the main bearing which supports the crankshaft of the engine.";
CM_ SG_ 2566823678 EngMainBearing2Temp "Temperature of the main bearing which supports the crankshaft of the engine.";
CM_ SG_ 2566823678 EngMainBearing1Temp "Temperature of the main bearing which supports the crankshaft of the engine.";
CM_ BO_ 2432595710 "Laser Leveling System Vertical Position Display Data";
CM_ SG_ 2432595710 DisplayDeadbands "Sets Display Deadbands mode.";
CM_ SG_ 2432595710 LEDPatternCtrl "Sets LED Pattern control mode on laser leveling systems.";
CM_ SG_ 2432595710 LEDDisplayDeadbandCtrl "This parameter informs the system what the selected Display deadband will be.";
CM_ SG_ 2432595710 LEDDisplayModeCtrl "This parameter informs the system what the selected Display mode will be.";
CM_ SG_ 2432595710 LEDDisplayData1 "Informs display devices how to display the current vertical position.";
CM_ BO_ 2365486590 "Laser Leveling System Vertical Deviation";
CM_ SG_ 2365486590 LaserStrikeDataLatency "Time from laser strike to CAN message transmission.";
CM_ SG_ 2365486590 LaserReceiverType "Identifies which type of Laser Receiver transmitted the message.";
CM_ SG_ 2365486590 LaserStrikeVerticalDeviation "The calculated distance from the laser strike position to the current land leveling system reference point.";
CM_ SG_ 2365486590 AbsLaserStrikePos "Laser Strike location on the survey type laser receiver.";
CM_ BO_ 2365485566 "Laser Tracer Position";
CM_ SG_ 2365485566 LaserTracerInformation "Provides the status of the laser tracer to the operator.";
CM_ SG_ 2365485566 LEDDisplayData2 "Informs display devices how to display the current position of the laser tracer.";
CM_ SG_ 2365485566 LaserTracerHorizontalDeviation "The calculated percent deviation between the target distance and the center of the laser tracer.";
CM_ SG_ 2365485566 LaserTracerVerticalDistance "The elevation of the laser tracer sensor in a laser leveling system.";
CM_ SG_ 2365485566 LaserTracerTargetDeviation "The calculated distance for the laser target to the current laser tracer reference point.";
CM_ BO_ 2633939454 "Trip Fuel Information (Liquid)";
CM_ SG_ 2633939454 TripCruiseFuelUsed "Total fuel consumed while the engine is in the cruise hold state since the last trip reset.";
CM_ SG_ 2633939454 TripVehicleIdleFuelUsed "Total fuel consumed while neither the PTO or remote PTO governor is in the hold state, the engine speed is greater than";
CM_ SG_ 2633939454 TripDriveFuelUsed "Total fuel consumed while the engine speed is greater than zero, vehicle speed is greater than or equal to 2 km/h, and";
CM_ SG_ 2633939454 TrpPTOGovernorNonmovingFuelUsed "Total fuel consumed while either the PTO or remote PTO governors are in the hold state, the engine speed is greater";
CM_ SG_ 2633939454 TripPTOGovernorMovingFuelUsed "Total fuel consumed while either the PTO or remote PTO governors are in the hold state, the engine speed is greater";
CM_ SG_ 2633939454 TripDriveFuelEconomy "Trip drive fuel economy is equal to the distance traveled by vehicle in the drive state (engine speed greater than zero,";
CM_ BO_ 2365486334 "Modify Leveling System Control Set Point";
CM_ SG_ 2365486334 BldHeightSetPointHighResolution "High resolution for the laser guided blade set point.";
CM_ SG_ 2365486334 ModifyLevelingSystemSetPoint "Used to control and coordinate the set point for the leveling system.";
CM_ BO_ 2364542462 "Land Leveling System Operational Information";
CM_ SG_ 2364542462 SdshftDsrdBldOffsetOperatorCtrl "This parameter indicates the side-shift blade control mode operator control state the user has set for the land leveling system.";
CM_ SG_ 2364542462 SdshftBldCtrlMdeOperatorControl "This parameter indicates the side-shift offset operator control state the user has set for the land leveling system.";
CM_ SG_ 2364542462 RghtDsrdBladeOffsetOperatorCtrl "This parameter indicates the right blade offset operator control state the user has set for the land leveling system.";
CM_ SG_ 2364542462 RghtBldeCtrlModeOperatorControl "This parameter indicates the right blade control mode operator control state the user has set for the land leveling system.";
CM_ SG_ 2364542462 LftDsredBladeOffsetOperatorCtrl "This parameter indicates the left blade offset operator control state the user has set for the land leveling system.";
CM_ SG_ 2364542462 LftBladeCtrlModeOperatorControl "This parameter indicates the left blade control mode operator control state the user has set for the land leveling system.";
CM_ SG_ 2364542462 BladeAutoModeCmd "Allows other controllers to command to the primary control system what they think is the appropriate auto control mode to";
CM_ SG_ 2364542462 DesiredGradeOffsetSwitch "This parameter indicates the grade offset switch state the user has set for the land leveling system.";
CM_ SG_ 2364542462 BladeCtrlModeSwitch "This parameter indicates the blade control mode switch state the user has set for the land leveling system.";
CM_ SG_ 2364542462 StElvtnSnsor2ReferenceElevation "Command from a display or other external device (i.";
CM_ SG_ 2364542462 StElvtnSnsor1ReferenceElevation "Command from a display or other external device (i.";
CM_ BO_ 2365486078 "Laser Receiver Mast Position";
CM_ SG_ 2365486078 MastPos "Used to monitor the position of the sensor attached to the land leveling mast.";
CM_ BO_ 2633937918 "Fuel Information (Liquid)";
CM_ SG_ 2633937918 TotalEngPTOGovernorFuelUsed "Total fuel used while the PTO or remote PTO governors are in the hold state and engine speed is above zero, over the";
CM_ SG_ 2633937918 TripAverageFuelRate "Average fuel rate, equal to trip fuel divided by trip time while the engine speed is above zero, since the last trip reset.";
CM_ SG_ 2633937918 FlexibleFuelPercentage "Measured signal that indicates the percentage of alcohol in the fuel currently being used.";
CM_ BO_ 2566844928 "Fuel Economy (Liquid)";
CM_ SG_ 2566844928 EngAverageFuelEconomy "Average of instantaneous fuel economy for that segment of vehicle operation of interest.";
CM_ SG_ 2566844928 EngInstantaneousFuelEconomy "Current fuel economy at current vehicle velocity.";
CM_ SG_ 2566844928 EngFuelRate "Amount of fuel consumed by engine per unit of time.";
CM_ SG_ 2566844928 EngThrottleValve2Pos "The sensed position feedback of the valve, coming from a second electrical actuator for a second throttle plate, used to";
CM_ SG_ 2566844928 EngThrottleValve1Pos "The position of the valve used to regulate the supply of a fluid, usually air or fuel/air mixture, to an engine.";
CM_ BO_ 2566842878 "Fuel Consumption (Liquid)";
CM_ SG_ 2566842878 EngTotalFuelUsed "Accumulated amount of fuel used during vehicle operation.";
CM_ SG_ 2566842878 EngTripFuel "Fuel consumed during all or part of a journey.";
CM_ BO_ 2633883646 "Front Wheel Drive Status";
CM_ SG_ 2633883646 FrontWheelDriveActuatorStatus "Feedback on the front wheel drive actuator.";
CM_ BO_ 2633880062 "FMS-standard Interface Identity/Capabilities";
CM_ SG_ 2633880062 FMSstandardSWversionSupported "Information that identifies which issue level of the FMS-standard document the software included in the FMS gateway supports.";
CM_ SG_ 2633880062 FMSstandardRqsSupported "Status signal which indicates if the FMS Vehicle Interface (FMS Gateway) will respond to requests from the FMS device";
CM_ SG_ 2633880062 FMSstandardDiagnosticsSupported "Status signal which indicates if the FMS Vehicle Interface (FMS Gateway) supports the handling of diagnostic messages";
CM_ BO_ 2566806526 "Forward Lane Image";
CM_ SG_ 2566806526 LnDprtureIndicationEnableStatus "Indicates whether lane departure indication is active.";
CM_ SG_ 2566806526 LaneTrackingStatusLeftSide "Indicates whether the left side is tracking lane.";
CM_ SG_ 2566806526 LaneTrackingStatusRightSide "Indicates whether right side is tracking lane.";
CM_ BO_ 2431649790 "Forward Lane Image urgent msg";
CM_ SG_ 2431649790 LaneDepartureImminentLeftSide "Indicates departure imminent on left side of lane.";
CM_ SG_ 2431649790 LaneDepartureImminentRightSide "Indicates departure imminent on right side of lane.";
CM_ SG_ 2431649790 LaneDepartureRight "Indicates that the middle of vehicle departs the lane on the right side.";
CM_ SG_ 2431649790 LaneDepartureLeft "Indicates that the middle of vehicle departs the lane on the left side.";
CM_ BO_ 2633929214 "Fuel Leakage";
CM_ SG_ 2633929214 EngFuelLeakage2 "Status signal which indicates fuel leakage in the fuel rail of the engine.";
CM_ SG_ 2633929214 EngFuelLeakage1 "Status signal which indicates fuel leakage in the fuel rail of the engine.";
CM_ BO_ 2566831360 "Fan Drive";
CM_ SG_ 2566831360 FanSpeed "The speed of the fan associated with engine coolant system.";
CM_ SG_ 2566831360 FanDriveState "This parameter is used to indicate the current state or mode of operation by the fan drive.";
CM_ SG_ 2566831360 EstPercentFanSpeed "Estimated fan speed as a ratio of the fan drive (current speed) to the fully engaged fan drive (maximum fan speed).";
CM_ SG_ 2566831360 HydFanMotorPress "The hydraulic pressure used to drive the fan system, sensed before the hydraulic fan motor.";
CM_ SG_ 2566831360 FanDriveBypassCmdStatus "Status of the Fan Drive Bypass Command as being commanded by the ECU.";
CM_ BO_ 2566820094 "Engine Torque History";
CM_ SG_ 2566820094 EngTorqueLimit6AxleInput "Limit applied to the engine output torque based on the maximum allowable axle input torque.";
CM_ SG_ 2566820094 EngTorqueLimit5Switch "Limit applied to the engine output torque based on activation of an ECU switch input.";
CM_ SG_ 2566820094 EngTorqueLimit4Trans "Limit applied to the engine output torque during vehicle operation in transmission gear ratios numerically less than or";
CM_ SG_ 2566820094 EngTorqueLimit3Trans "Limit applied to the engine output torque during vehicle operation in transmission gear ratios numerically less than or";
CM_ SG_ 2566820094 TransGearRatio3 "Gear ratio value stored in the ECU that is used to define a range of transmission gears for which a limit is applied to the";
CM_ SG_ 2566820094 EngTorqueLimit2Trans "Limit applied to the engine output torque during vehicle operation in transmission gear ratios numerically less than or";
CM_ SG_ 2566820094 TransGearRatio2 "Gear ratio value stored in the ECU that is used to define a range of transmission gears for which a limit is applied to the";
CM_ SG_ 2566820094 EngTorqueLimit1Trans "Limit applied to the engine output torque during vehicle operation in transmission gear ratios numerically greater than";
CM_ SG_ 2566820094 TransGearRatio1 "Gear ratio value stored in the ECU that is used to define a range of transmission gears for which a limit is applied to the";
CM_ SG_ 2566820094 EngTorqueLimitFeature "Torque limit rating described in the current record.";
CM_ SG_ 2566820094 TorqueLimitingFeatureStatus "Status of an ECU feature which limits the torque output of the engine.";
CM_ SG_ 2566820094 CalibRecordDurationTime "Duration in hours for which the engine operated in the conditions captured in the current record.";
CM_ SG_ 2566820094 CalibRecordStartYear "Calendar year timestamp when an ECU record was established.";
CM_ SG_ 2566820094 CalibRecordStartDay "Calendar day timestamp when an ECU record was established.";
CM_ SG_ 2566820094 CalibRecordStartMonth "Calendar month timestamp when an ECU record was established.";
CM_ SG_ 2566820094 EngPeakTorque2 "Maximum torque output of the current ECU calibration when the engine operates on torque curve 2.";
CM_ SG_ 2566820094 EngPeakTorque1 "Maximum torque output of the current ECU calibration when the engine operates on torque curve 1.";
CM_ SG_ 2566820094 EngPower "Advertised engine power capability.";
CM_ SG_ 2566820094 NumberOfEngTorqueHistoryRecords "Number of torque history records contained in the engine torque history PGN.";
CM_ BO_ 2364541955 "Electronic Transmission Controller #8";
CM_ SG_ 2364541955 TransClutch_ConverterInputSpeed "Rotational velocity of the input to a transmission's master clutch or torque converter.";
CM_ SG_ 2364541955 TransTorqueConverterRatio "Ratio of the transmissions torque converter output torque to torque converter input torque at current speed.";
CM_ BO_ 2566801923 "Electronic Transmission Controller 7";
CM_ SG_ 2566801923 TrnsRvrseGearShiftInhibitStatus "Reflects the status of transmission reverse inhibit activity in response to requests via SPN 4242 - Transmission Reverse";
CM_ SG_ 2566801923 TrnsCrrntRangeDisplayBlankState "State signal indicating a transmission request for the display of the Transmission Current Range parameter (SPN 163) to";
CM_ SG_ 2566801923 TransWarningIndicator "Signal from transmission indicating that some aspect of its operation is not functioning correctly, and as a result,";
CM_ SG_ 2566801923 TransMode8Indicator "Indicates whether transmission mode 8 is enabled.";
CM_ SG_ 2566801923 TransMode7Indicator "Indicates whether transmission mode 7 is enabled.";
CM_ SG_ 2566801923 TransMode6Indicator "Indicates whether transmission mode 6 is enabled.";
CM_ SG_ 2566801923 TransMode5Indicator "Indicates whether transmission mode 5 is enabled.";
CM_ SG_ 2566801923 TransRqedGearFeedback "Feedback of the SPN 525 Transmission Requested Gear input as received from the shift selector, ABS or engine via";
CM_ SG_ 2566801923 TransMode1Indicator "This state signal is the transmission’s indication that it is operating under transmission mode 1 (SPN 1852) as";
CM_ SG_ 2566801923 TransMode2Indicator "This state signal is the transmission’s indication that it is operating under transmission mode 2 (SPN 1853) as";
CM_ SG_ 2566801923 TransMode3Indicator "This state signal is the transmission’s indication that it is operating under transmission mode 3 (SPN 1854) as";
CM_ SG_ 2566801923 TransMode4Indicator "This state signal is the transmission’s indication that it is operating under transmission mode 4 (SPN 1855) as";
CM_ SG_ 2566801923 TransShiftInhibitIndicator "State signal indicating a transmission request for the Shift Inhibit Indicator to be active or inactive.";
CM_ SG_ 2566801923 TransEngCrankEnable "State signal from the transmission indicating if the transmission’s status is such that engine cranking is allowed (i.";
CM_ SG_ 2566801923 ActiveShiftConsoleIndicator "Signal from transmission control unit indicating which shift console (primary or secondary) it currently considers as the";
CM_ SG_ 2566801923 TransReadyForBrakeRelease "This parameter indicates that enough torque / motive force is available at the transmission output shaft to release all the";
CM_ SG_ 2566801923 TransRqedRangeDisplayFlashState "State signal indicating a transmission request for the display of the Transmission Requested Range parameter (SPN 162)";
CM_ SG_ 2566801923 TransRqedRangeDisplayBlankState "State signal indicating a transmission request for the display of the Transmission Requested Range parameter (SPN162)";
CM_ SG_ 2566801923 TransServiceIndicator "Signal from transmission indicating that some aspect of the gearbox requires servicing, such as the oil, filter, clutch(es) or";
CM_ BO_ 2633935619 "Electronic Transmission Controller 6";
CM_ SG_ 2633935619 ClutchLifeRemaining "Signal which indicates the actual clutch life remaining in percent.";
CM_ SG_ 2633935619 LowestPossibleGear "The transmission calculates this gear continuously.";
CM_ SG_ 2633935619 HighestPossibleGear "The transmission calculates this gear continuously.";
CM_ SG_ 2633935619 RecommendedGear "The transmission calculates this gear continuously.";
BA_DEF_ SG_  "SigType" ENUM  "Default","Range","RangeSigned","ASCII","Discrete","Control","ReferencePGN","DTC","StringDelimiter","StringLength","StringLengthControl";
BA_DEF_ SG_  "GenSigStartValue" INT 0 10000;
BA_DEF_ SG_  "GenSigSendType" ENUM  "Cyclic","OnWrite","reserved","OnChange","reserved","reserved","reserved","NoSigSendType";
BA_DEF_ SG_  "GenSigILSupport" ENUM  "Yes","No";
BA_DEF_ SG_  "GenSigEVName" STRING ;
BA_DEF_ SG_  "SPN" INT 0 524287;
BA_DEF_ BO_  "GenMsgStartDelayTime" INT 0 100000;
BA_DEF_ BO_  "GenMsgILSupport" ENUM  "Yes","No";
BA_DEF_ BO_  "GenMsgRequestable" INT 0 1;
BA_DEF_ BO_  "GenMsgSendType" ENUM  "cyclic","reserved","cyclicIfActive","reserved","reserved","reserved","reserved","reserved","noMsgSendType";
BA_DEF_ BO_  "VFrameFormat" ENUM  "StandardCAN","ExtendedCAN","reserved";
BA_DEF_ BO_  "GenMsgCycleTime" INT 0 3600000;
BA_DEF_ SG_  "SystemSignalLongSymbol" STRING ;
BA_DEF_DEF_  "SigType" "Default";
BA_DEF_DEF_  "GenSigStartValue" 0;
BA_DEF_DEF_  "GenSigSendType" "NoSigSendType";
BA_DEF_DEF_  "GenSigILSupport" "Yes";
BA_DEF_DEF_  "GenSigEVName" "Env@Nodename_@Signame";
BA_DEF_DEF_  "SPN" 0;
BA_DEF_DEF_  "GenMsgStartDelayTime" 0;
BA_DEF_DEF_  "GenMsgILSupport" "Yes";
BA_DEF_DEF_  "GenMsgRequestable" 1;
BA_DEF_DEF_  "GenMsgSendType" "noMsgSendType";
BA_DEF_DEF_  "VFrameFormat" "";
BA_DEF_DEF_  "GenMsgCycleTime" 0;
BA_DEF_DEF_  "SystemSignalLongSymbol" "";
BA_ "GenMsgSendType" BO_ 2566845694 0;
BA_ "GenMsgCycleTime" BO_ 2566845694 10000;
BA_ "VFrameFormat" BO_ 2566845694 3;
BA_ "VFrameFormat" BO_ 2633939966 3;
BA_ "VFrameFormat" BO_ 2633939710 3;
BA_ "VFrameFormat" BO_ 2564161278 3;
BA_ "VFrameFormat" BO_ 2566842110 3;
BA_ "GenMsgSendType" BO_ 2566821630 0;
BA_ "GenMsgCycleTime" BO_ 2566821630 100;
BA_ "VFrameFormat" BO_ 2566821630 3;
BA_ "GenMsgSendType" BO_ 2365484286 0;
BA_ "GenMsgCycleTime" BO_ 2365484286 50;
BA_ "VFrameFormat" BO_ 2365484286 3;
BA_ "GenMsgSendType" BO_ 2566771710 0;
BA_ "GenMsgCycleTime" BO_ 2566771710 1000;
BA_ "VFrameFormat" BO_ 2566771710 3;
BA_ "GenMsgSendType" BO_ 2566821886 0;
BA_ "GenMsgCycleTime" BO_ 2566821886 1000;
BA_ "VFrameFormat" BO_ 2566821886 3;
BA_ "GenMsgSendType" BO_ 2566822142 0;
BA_ "GenMsgCycleTime" BO_ 2566822142 1000;
BA_ "VFrameFormat" BO_ 2566822142 3;
BA_ "GenMsgSendType" BO_ 2566822144 0;
BA_ "GenMsgCycleTime" BO_ 2566822144 1000;
BA_ "VFrameFormat" BO_ 2566822144 3;
BA_ "GenMsgSendType" BO_ 2566822400 0;
BA_ "GenMsgCycleTime" BO_ 2566822400 1000;
BA_ "VFrameFormat" BO_ 2566822400 3;
BA_ "GenMsgSendType" BO_ 2633931520 0;
BA_ "GenMsgCycleTime" BO_ 2633931520 1000;
BA_ "VFrameFormat" BO_ 2633931520 3;
BA_ "VFrameFormat" BO_ 2566802430 3;
BA_ "VFrameFormat" BO_ 2566841086 3;
BA_ "VFrameFormat" BO_ 2348876549 3;
BA_ "GenMsgSendType" BO_ 2566839552 0;
BA_ "GenMsgCycleTime" BO_ 2566839552 1000;
BA_ "VFrameFormat" BO_ 2566839552 3;
BA_ "VFrameFormat" BO_ 2633911806 3;
BA_ "GenMsgSendType" BO_ 2566775550 2;
BA_ "GenMsgCycleTime" BO_ 2566775550 1000;
BA_ "VFrameFormat" BO_ 2566775550 3;
BA_ "GenMsgSendType" BO_ 2566819838 0;
BA_ "GenMsgCycleTime" BO_ 2566819838 1000;
BA_ "VFrameFormat" BO_ 2566819838 3;
BA_ "VFrameFormat" BO_ 2566839038 3;
BA_ "VFrameFormat" BO_ 2566838787 3;
BA_ "GenMsgSendType" BO_ 2566841344 0;
BA_ "GenMsgCycleTime" BO_ 2566841344 1000;
BA_ "VFrameFormat" BO_ 2566841344 3;
BA_ "VFrameFormat" BO_ 2566832382 3;
BA_ "VFrameFormat" BO_ 2633928446 3;
BA_ "GenMsgSendType" BO_ 2566804478 0;
BA_ "GenMsgCycleTime" BO_ 2566804478 5000;
BA_ "VFrameFormat" BO_ 2566804478 3;
BA_ "GenMsgSendType" BO_ 2566847486 0;
BA_ "GenMsgCycleTime" BO_ 2566847486 1000;
BA_ "VFrameFormat" BO_ 2566847486 3;
BA_ "VFrameFormat" BO_ 2631859966 3;
BA_ "VFrameFormat" BO_ 2566840591 3;
BA_ "VFrameFormat" BO_ 2633930238 3;
BA_ "GenMsgSendType" BO_ 2566844416 0;
BA_ "GenMsgCycleTime" BO_ 2566844416 100;
BA_ "VFrameFormat" BO_ 2566844416 3;
BA_ "GenMsgSendType" BO_ 2566770174 0;
BA_ "GenMsgCycleTime" BO_ 2566770174 200;
BA_ "VFrameFormat" BO_ 2566770174 3;
BA_ "GenMsgSendType" BO_ 2566769662 0;
BA_ "GenMsgCycleTime" BO_ 2566769662 500;
BA_ "VFrameFormat" BO_ 2566769662 3;
BA_ "GenMsgSendType" BO_ 2566768638 0;
BA_ "GenMsgCycleTime" BO_ 2566768638 500;
BA_ "VFrameFormat" BO_ 2566768638 3;
BA_ "VFrameFormat" BO_ 2365443326 3;
BA_ "GenMsgSendType" BO_ 2566776318 0;
BA_ "GenMsgCycleTime" BO_ 2566776318 1000;
BA_ "VFrameFormat" BO_ 2566776318 3;
BA_ "GenMsgSendType" BO_ 2566802686 0;
BA_ "GenMsgCycleTime" BO_ 2566802686 500;
BA_ "VFrameFormat" BO_ 2566802686 3;
BA_ "GenMsgSendType" BO_ 2566774014 0;
BA_ "GenMsgCycleTime" BO_ 2566774014 1000;
BA_ "VFrameFormat" BO_ 2566774014 3;
BA_ "GenMsgSendType" BO_ 2566823166 0;
BA_ "GenMsgCycleTime" BO_ 2566823166 1000;
BA_ "VFrameFormat" BO_ 2566823166 3;
BA_ "GenMsgSendType" BO_ 2566823422 0;
BA_ "GenMsgCycleTime" BO_ 2566823422 1000;
BA_ "VFrameFormat" BO_ 2566823422 3;
BA_ "GenMsgSendType" BO_ 2566823678 0;
BA_ "GenMsgCycleTime" BO_ 2566823678 1000;
BA_ "VFrameFormat" BO_ 2566823678 3;
BA_ "GenMsgSendType" BO_ 2432595710 0;
BA_ "GenMsgCycleTime" BO_ 2432595710 100;
BA_ "VFrameFormat" BO_ 2432595710 3;
BA_ "GenMsgSendType" BO_ 2365486590 0;
BA_ "GenMsgCycleTime" BO_ 2365486590 50;
BA_ "VFrameFormat" BO_ 2365486590 3;
BA_ "GenMsgSendType" BO_ 2365485566 0;
BA_ "GenMsgCycleTime" BO_ 2365485566 50;
BA_ "VFrameFormat" BO_ 2365485566 3;
BA_ "VFrameFormat" BO_ 2633939454 3;
BA_ "GenMsgSendType" BO_ 2365486334 0;
BA_ "GenMsgCycleTime" BO_ 2365486334 50;
BA_ "VFrameFormat" BO_ 2365486334 3;
BA_ "GenMsgSendType" BO_ 2364542462 0;
BA_ "GenMsgCycleTime" BO_ 2364542462 100;
BA_ "VFrameFormat" BO_ 2364542462 3;
BA_ "GenMsgSendType" BO_ 2365486078 0;
BA_ "GenMsgCycleTime" BO_ 2365486078 50;
BA_ "VFrameFormat" BO_ 2365486078 3;
BA_ "VFrameFormat" BO_ 2633937918 3;
BA_ "GenMsgSendType" BO_ 2566844928 0;
BA_ "GenMsgCycleTime" BO_ 2566844928 100;
BA_ "VFrameFormat" BO_ 2566844928 3;
BA_ "VFrameFormat" BO_ 2566842878 3;
BA_ "GenMsgSendType" BO_ 2633883646 0;
BA_ "GenMsgCycleTime" BO_ 2633883646 500;
BA_ "VFrameFormat" BO_ 2633883646 3;
BA_ "GenMsgSendType" BO_ 2633880062 0;
BA_ "GenMsgCycleTime" BO_ 2633880062 10000;
BA_ "VFrameFormat" BO_ 2633880062 3;
BA_ "GenMsgSendType" BO_ 2566806526 0;
BA_ "GenMsgCycleTime" BO_ 2566806526 100;
BA_ "VFrameFormat" BO_ 2566806526 3;
BA_ "GenMsgSendType" BO_ 2431649790 2;
BA_ "GenMsgCycleTime" BO_ 2431649790 50;
BA_ "VFrameFormat" BO_ 2431649790 3;
BA_ "GenMsgSendType" BO_ 2633929214 0;
BA_ "GenMsgCycleTime" BO_ 2633929214 1000;
BA_ "VFrameFormat" BO_ 2633929214 3;
BA_ "GenMsgSendType" BO_ 2566831360 0;
BA_ "GenMsgCycleTime" BO_ 2566831360 1000;
BA_ "VFrameFormat" BO_ 2566831360 3;
BA_ "VFrameFormat" BO_ 2566820094 3;
BA_ "GenMsgSendType" BO_ 2364541955 0;
BA_ "GenMsgCycleTime" BO_ 2364541955 20;
BA_ "VFrameFormat" BO_ 2364541955 3;
BA_ "GenMsgSendType" BO_ 2566801923 0;
BA_ "GenMsgCycleTime" BO_ 2566801923 100;
BA_ "VFrameFormat" BO_ 2566801923 3;
BA_ "VFrameFormat" BO_ 2633935619 3;
BA_ "SPN" SG_ 2566845694 TirePressThresholdDetection_13 521613;
BA_ "SPN" SG_ 2566845694 TirePressThresholdDetection_12 521612;
BA_ "SPN" SG_ 2566845694 TirePressThresholdDetection_11 521611;
BA_ "SPN" SG_ 2566845694 TirePressThresholdDetection_10 521610;
BA_ "SPN" SG_ 2566845694 TirePressThresholdDetection_01 521601;
BA_ "SigType" SG_ 2566845694 TirePress_33 1;
BA_ "SPN" SG_ 2566845694 TirePress_33 521033;
BA_ "SigType" SG_ 2566845694 TirePress_32 1;
BA_ "SPN" SG_ 2566845694 TirePress_32 521032;
BA_ "SigType" SG_ 2566845694 TirePress_31 1;
BA_ "SPN" SG_ 2566845694 TirePress_31 521031;
BA_ "SigType" SG_ 2566845694 TirePress_30 1;
BA_ "SPN" SG_ 2566845694 TirePress_30 521030;
BA_ "SigType" SG_ 2566845694 TirePress_23 1;
BA_ "SPN" SG_ 2566845694 TirePress_23 521023;
BA_ "SigType" SG_ 2566845694 TirePress_22 1;
BA_ "SPN" SG_ 2566845694 TirePress_22 521022;
BA_ "SigType" SG_ 2566845694 TirePress_21 1;
BA_ "SPN" SG_ 2566845694 TirePress_21 521021;
BA_ "SigType" SG_ 2566845694 TirePress_20 1;
BA_ "SPN" SG_ 2566845694 TirePress_20 521020;
BA_ "SigType" SG_ 2566845694 TirePress_13 1;
BA_ "SPN" SG_ 2566845694 TirePress_13 521013;
BA_ "SigType" SG_ 2566845694 TirePress_12 1;
BA_ "SPN" SG_ 2566845694 TirePress_12 521012;
BA_ "SigType" SG_ 2566845694 TirePress_11 1;
BA_ "SPN" SG_ 2566845694 TirePress_11 521011;
BA_ "SigType" SG_ 2566845694 TirePress_10 1;
BA_ "SPN" SG_ 2566845694 TirePress_10 521010;
BA_ "SigType" SG_ 2566845694 TireAirLeakageRate_33 1;
BA_ "SPN" SG_ 2566845694 TireAirLeakageRate_33 521533;
BA_ "SigType" SG_ 2566845694 TireAirLeakageRate_32 1;
BA_ "SPN" SG_ 2566845694 TireAirLeakageRate_32 521532;
BA_ "SigType" SG_ 2566845694 TireAirLeakageRate_31 1;
BA_ "SPN" SG_ 2566845694 TireAirLeakageRate_31 521531;
BA_ "SigType" SG_ 2566845694 TireAirLeakageRate_30 1;
BA_ "SPN" SG_ 2566845694 TireAirLeakageRate_30 521530;
BA_ "SigType" SG_ 2566845694 TireAirLeakageRate_23 1;
BA_ "SPN" SG_ 2566845694 TireAirLeakageRate_23 521523;
BA_ "SigType" SG_ 2566845694 TireAirLeakageRate_22 1;
BA_ "SPN" SG_ 2566845694 TireAirLeakageRate_22 521522;
BA_ "SigType" SG_ 2566845694 TireAirLeakageRate_21 1;
BA_ "SPN" SG_ 2566845694 TireAirLeakageRate_21 521521;
BA_ "SigType" SG_ 2566845694 TireAirLeakageRate_20 1;
BA_ "SPN" SG_ 2566845694 TireAirLeakageRate_20 521520;
BA_ "SigType" SG_ 2566845694 TireAirLeakageRate_13 1;
BA_ "SPN" SG_ 2566845694 TireAirLeakageRate_13 521513;
BA_ "SigType" SG_ 2566845694 TireAirLeakageRate_12 1;
BA_ "SPN" SG_ 2566845694 TireAirLeakageRate_12 521512;
BA_ "SigType" SG_ 2566845694 TireAirLeakageRate_11 1;
BA_ "SPN" SG_ 2566845694 TireAirLeakageRate_11 521511;
BA_ "SigType" SG_ 2566845694 TireAirLeakageRate_10 1;
BA_ "SPN" SG_ 2566845694 TireAirLeakageRate_10 521510;
BA_ "SigType" SG_ 2566845694 TireAirLeakageRate_01 1;
BA_ "SPN" SG_ 2566845694 TireAirLeakageRate_01 521501;
BA_ "SigType" SG_ 2566845694 TireAirLeakageRate_00 1;
BA_ "SPN" SG_ 2566845694 TireAirLeakageRate_00 521500;
BA_ "SigType" SG_ 2566845694 CTIWheelSensorStatus_33 4;
BA_ "SPN" SG_ 2566845694 CTIWheelSensorStatus_33 521433;
BA_ "SigType" SG_ 2566845694 CTIWheelSensorStatus_32 4;
BA_ "SPN" SG_ 2566845694 CTIWheelSensorStatus_32 521432;
BA_ "SigType" SG_ 2566845694 CTIWheelSensorStatus_31 4;
BA_ "SPN" SG_ 2566845694 CTIWheelSensorStatus_31 521431;
BA_ "SigType" SG_ 2566845694 CTIWheelSensorStatus_30 4;
BA_ "SPN" SG_ 2566845694 CTIWheelSensorStatus_30 521430;
BA_ "SigType" SG_ 2566845694 CTIWheelSensorStatus_23 4;
BA_ "SPN" SG_ 2566845694 CTIWheelSensorStatus_23 521423;
BA_ "SigType" SG_ 2566845694 CTIWheelSensorStatus_22 4;
BA_ "SPN" SG_ 2566845694 CTIWheelSensorStatus_22 521422;
BA_ "SigType" SG_ 2566845694 CTIWheelSensorStatus_21 4;
BA_ "SPN" SG_ 2566845694 CTIWheelSensorStatus_21 521421;
BA_ "SigType" SG_ 2566845694 CTIWheelSensorStatus_20 4;
BA_ "SPN" SG_ 2566845694 CTIWheelSensorStatus_20 521420;
BA_ "SigType" SG_ 2566845694 CTIWheelSensorStatus_13 4;
BA_ "SPN" SG_ 2566845694 CTIWheelSensorStatus_13 521413;
BA_ "SigType" SG_ 2566845694 CTIWheelSensorStatus_12 4;
BA_ "SPN" SG_ 2566845694 CTIWheelSensorStatus_12 521412;
BA_ "SigType" SG_ 2566845694 CTIWheelSensorStatus_11 4;
BA_ "SPN" SG_ 2566845694 CTIWheelSensorStatus_11 521411;
BA_ "SigType" SG_ 2566845694 CTIWheelSensorStatus_10 4;
BA_ "SPN" SG_ 2566845694 CTIWheelSensorStatus_10 521410;
BA_ "SigType" SG_ 2566845694 CTIWheelSensorStatus_01 4;
BA_ "SPN" SG_ 2566845694 CTIWheelSensorStatus_01 521401;
BA_ "SigType" SG_ 2566845694 CTIWheelEndElectricalFault_33 4;
BA_ "SPN" SG_ 2566845694 CTIWheelEndElectricalFault_33 521233;
BA_ "SigType" SG_ 2566845694 CTIWheelEndElectricalFault_32 4;
BA_ "SPN" SG_ 2566845694 CTIWheelEndElectricalFault_32 521232;
BA_ "SigType" SG_ 2566845694 CTIWheelEndElectricalFault_31 4;
BA_ "SPN" SG_ 2566845694 CTIWheelEndElectricalFault_31 521231;
BA_ "SigType" SG_ 2566845694 CTIWheelEndElectricalFault_30 4;
BA_ "SPN" SG_ 2566845694 CTIWheelEndElectricalFault_30 521230;
BA_ "SigType" SG_ 2566845694 CTIWheelEndElectricalFault_23 4;
BA_ "SPN" SG_ 2566845694 CTIWheelEndElectricalFault_23 521223;
BA_ "SigType" SG_ 2566845694 CTIWheelEndElectricalFault_22 4;
BA_ "SPN" SG_ 2566845694 CTIWheelEndElectricalFault_22 521222;
BA_ "SigType" SG_ 2566845694 CTIWheelEndElectricalFault_21 4;
BA_ "SPN" SG_ 2566845694 CTIWheelEndElectricalFault_21 521221;
BA_ "SigType" SG_ 2566845694 CTIWheelEndElectricalFault_20 4;
BA_ "SPN" SG_ 2566845694 CTIWheelEndElectricalFault_20 521220;
BA_ "SigType" SG_ 2566845694 CTIWheelEndElectricalFault_13 4;
BA_ "SPN" SG_ 2566845694 CTIWheelEndElectricalFault_13 521213;
BA_ "SigType" SG_ 2566845694 CTIWheelEndElectricalFault_12 4;
BA_ "SPN" SG_ 2566845694 CTIWheelEndElectricalFault_12 521212;
BA_ "SigType" SG_ 2566845694 CTIWheelEndElectricalFault_11 4;
BA_ "SPN" SG_ 2566845694 CTIWheelEndElectricalFault_11 521211;
BA_ "SigType" SG_ 2566845694 CTIWheelEndElectricalFault_10 4;
BA_ "SPN" SG_ 2566845694 CTIWheelEndElectricalFault_10 521210;
BA_ "SigType" SG_ 2566845694 CTIWheelEndElectricalFault_01 4;
BA_ "SPN" SG_ 2566845694 CTIWheelEndElectricalFault_01 521201;
BA_ "SigType" SG_ 2566845694 CTITireStatus_33 4;
BA_ "SPN" SG_ 2566845694 CTITireStatus_33 521333;
BA_ "SigType" SG_ 2566845694 CTITireStatus_32 4;
BA_ "SPN" SG_ 2566845694 CTITireStatus_32 521332;
BA_ "SigType" SG_ 2566845694 CTITireStatus_31 4;
BA_ "SPN" SG_ 2566845694 CTITireStatus_31 521331;
BA_ "SigType" SG_ 2566845694 CTITireStatus_30 4;
BA_ "SPN" SG_ 2566845694 CTITireStatus_30 521330;
BA_ "SigType" SG_ 2566845694 CTITireStatus_23 4;
BA_ "SPN" SG_ 2566845694 CTITireStatus_23 521323;
BA_ "SigType" SG_ 2566845694 CTITireStatus_22 4;
BA_ "SPN" SG_ 2566845694 CTITireStatus_22 521322;
BA_ "SigType" SG_ 2566845694 CTITireStatus_21 4;
BA_ "SPN" SG_ 2566845694 CTITireStatus_21 521321;
BA_ "SigType" SG_ 2566845694 CTITireStatus_20 4;
BA_ "SPN" SG_ 2566845694 CTITireStatus_20 521320;
BA_ "SigType" SG_ 2566845694 CTITireStatus_13 4;
BA_ "SPN" SG_ 2566845694 CTITireStatus_13 521313;
BA_ "SigType" SG_ 2566845694 CTITireStatus_12 4;
BA_ "SPN" SG_ 2566845694 CTITireStatus_12 521312;
BA_ "SigType" SG_ 2566845694 CTITireStatus_11 4;
BA_ "SPN" SG_ 2566845694 CTITireStatus_11 521311;
BA_ "SigType" SG_ 2566845694 CTITireStatus_10 4;
BA_ "SPN" SG_ 2566845694 CTITireStatus_10 521310;
BA_ "SigType" SG_ 2566845694 CTITireStatus_01 4;
BA_ "SPN" SG_ 2566845694 CTITireStatus_01 521301;
BA_ "SigType" SG_ 2566845694 TireTemp_11 1;
BA_ "SPN" SG_ 2566845694 TireTemp_11 521111;
BA_ "SigType" SG_ 2566845694 TireTemp_33 1;
BA_ "SPN" SG_ 2566845694 TireTemp_33 521133;
BA_ "SigType" SG_ 2566845694 TireTemp_32 1;
BA_ "SPN" SG_ 2566845694 TireTemp_32 521132;
BA_ "SigType" SG_ 2566845694 TireTemp_31 1;
BA_ "SPN" SG_ 2566845694 TireTemp_31 521131;
BA_ "SigType" SG_ 2566845694 TireTemp_30 1;
BA_ "SPN" SG_ 2566845694 TireTemp_30 521130;
BA_ "SigType" SG_ 2566845694 TireTemp_23 1;
BA_ "SPN" SG_ 2566845694 TireTemp_23 521123;
BA_ "SigType" SG_ 2566845694 TireTemp_22 1;
BA_ "SPN" SG_ 2566845694 TireTemp_22 521122;
BA_ "SigType" SG_ 2566845694 TireTemp_21 1;
BA_ "SPN" SG_ 2566845694 TireTemp_21 521121;
BA_ "SigType" SG_ 2566845694 TireTemp_20 1;
BA_ "SPN" SG_ 2566845694 TireTemp_20 521120;
BA_ "SigType" SG_ 2566845694 TireTemp_13 1;
BA_ "SPN" SG_ 2566845694 TireTemp_13 521113;
BA_ "SigType" SG_ 2566845694 TireTemp_12 1;
BA_ "SPN" SG_ 2566845694 TireTemp_12 521112;
BA_ "SigType" SG_ 2566845694 TireTemp_10 1;
BA_ "SPN" SG_ 2566845694 TireTemp_10 521110;
BA_ "SigType" SG_ 2566845694 TireTemp_01 1;
BA_ "SPN" SG_ 2566845694 TireTemp_01 521101;
BA_ "SigType" SG_ 2566845694 TireTemp_00 1;
BA_ "SPN" SG_ 2566845694 TireTemp_00 521100;
BA_ "SPN" SG_ 2566845694 TirePressThresholdDetection_33 521633;
BA_ "SPN" SG_ 2566845694 TirePressThresholdDetection_32 521632;
BA_ "SPN" SG_ 2566845694 TirePressThresholdDetection_31 521631;
BA_ "SPN" SG_ 2566845694 TirePressThresholdDetection_30 521630;
BA_ "SPN" SG_ 2566845694 TirePressThresholdDetection_23 521623;
BA_ "SPN" SG_ 2566845694 TirePressThresholdDetection_22 521622;
BA_ "SPN" SG_ 2566845694 TirePressThresholdDetection_21 521621;
BA_ "SPN" SG_ 2566845694 TirePressThresholdDetection_20 521620;
BA_ "SPN" SG_ 2566845694 TirePressThresholdDetection_00 521600;
BA_ "SigType" SG_ 2566845694 TirePress_01 1;
BA_ "SPN" SG_ 2566845694 TirePress_01 521001;
BA_ "SigType" SG_ 2566845694 TirePress_00 1;
BA_ "SPN" SG_ 2566845694 TirePress_00 521000;
BA_ "SigType" SG_ 2566845694 CTIWheelSensorStatus_00 4;
BA_ "SPN" SG_ 2566845694 CTIWheelSensorStatus_00 521400;
BA_ "SigType" SG_ 2566845694 CTIWheelEndElectricalFault_00 4;
BA_ "SPN" SG_ 2566845694 CTIWheelEndElectricalFault_00 521200;
BA_ "SigType" SG_ 2566845694 CTITireStatus_00 4;
BA_ "SPN" SG_ 2566845694 CTITireStatus_00 521300;
BA_ "SigType" SG_ 2566845694 TireLocation 1;
BA_ "SPN" SG_ 2566845694 TireLocation 929;
BA_ "SigType" SG_ 2633939966 TripFanOnTimeDueToAManualSwitch 1;
BA_ "SPN" SG_ 2633939966 TripFanOnTimeDueToAManualSwitch 996;
BA_ "SigType" SG_ 2633939966 TripFanOnTime 1;
BA_ "SPN" SG_ 2633939966 TripFanOnTime 994;
BA_ "SigType" SG_ 2633939966 TripFanOnTimeDueToA_CSystem 1;
BA_ "SPN" SG_ 2633939966 TripFanOnTimeDueToA_CSystem 997;
BA_ "SigType" SG_ 2633939966 TripFanOnTimeDueToEngSystem 1;
BA_ "SPN" SG_ 2633939966 TripFanOnTimeDueToEngSystem 995;
BA_ "SigType" SG_ 2633939710 TripDistanceInTopGear 1;
BA_ "SPN" SG_ 2633939710 TripDistanceInTopGear 1000;
BA_ "SigType" SG_ 2633939710 TripGearDownDistance 1;
BA_ "SPN" SG_ 2633939710 TripGearDownDistance 999;
BA_ "SigType" SG_ 2633939710 TripDistanceOnVSL 1;
BA_ "SPN" SG_ 2633939710 TripDistanceOnVSL 998;
BA_ "SigType" SG_ 2564161278 AdjustLocalHourOffset 1;
BA_ "SPN" SG_ 2564161278 AdjustLocalHourOffset 1610;
BA_ "SigType" SG_ 2564161278 AdjustLocalMinuteOffset 1;
BA_ "SPN" SG_ 2564161278 AdjustLocalMinuteOffset 1609;
BA_ "SigType" SG_ 2564161278 AdjustYear 1;
BA_ "SPN" SG_ 2564161278 AdjustYear 1608;
BA_ "SigType" SG_ 2564161278 AdjustDay 1;
BA_ "SPN" SG_ 2564161278 AdjustDay 1607;
BA_ "SigType" SG_ 2564161278 AdjustMonth 1;
BA_ "SPN" SG_ 2564161278 AdjustMonth 1606;
BA_ "SigType" SG_ 2564161278 AdjustHours 1;
BA_ "SPN" SG_ 2564161278 AdjustHours 1605;
BA_ "SigType" SG_ 2564161278 AdjustMinutes 1;
BA_ "SPN" SG_ 2564161278 AdjustMinutes 1604;
BA_ "SigType" SG_ 2564161278 AdjustSeconds 1;
BA_ "SPN" SG_ 2564161278 AdjustSeconds 1603;
BA_ "SigType" SG_ 2566842110 LocalHourOffset 1;
BA_ "SPN" SG_ 2566842110 LocalHourOffset 1602;
BA_ "SigType" SG_ 2566842110 LocalMinuteOffset 1;
BA_ "SPN" SG_ 2566842110 LocalMinuteOffset 1601;
BA_ "SigType" SG_ 2566842110 Year 1;
BA_ "SPN" SG_ 2566842110 Year 964;
BA_ "SigType" SG_ 2566842110 Day 1;
BA_ "SPN" SG_ 2566842110 Day 962;
BA_ "SigType" SG_ 2566842110 Month 1;
BA_ "SPN" SG_ 2566842110 Month 963;
BA_ "SigType" SG_ 2566842110 Hours 1;
BA_ "SPN" SG_ 2566842110 Hours 961;
BA_ "SigType" SG_ 2566842110 Minutes 1;
BA_ "SPN" SG_ 2566842110 Minutes 960;
BA_ "SigType" SG_ 2566842110 Seconds 1;
BA_ "SPN" SG_ 2566842110 Seconds 959;
BA_ "SigType" SG_ 2566821630 EngTrbWstgteActuator1TempStatus 4;
BA_ "SPN" SG_ 2566821630 EngTrbWstgteActuator1TempStatus 5372;
BA_ "SigType" SG_ 2566821630 EngTrbWstgtActtr1PreliminaryFMI 1;
BA_ "SPN" SG_ 2566821630 EngTrbWstgtActtr1PreliminaryFMI 5371;
BA_ "SigType" SG_ 2566821630 EngDsrdTrbWastegateActuator2Pos 1;
BA_ "SPN" SG_ 2566821630 EngDsrdTrbWastegateActuator2Pos 5373;
BA_ "SigType" SG_ 2566821630 EngDsrdTrbWastegateActuator1Pos 1;
BA_ "SPN" SG_ 2566821630 EngDsrdTrbWastegateActuator1Pos 5370;
BA_ "SigType" SG_ 2566821630 EngTurboWastegateActuator4Pos 1;
BA_ "SPN" SG_ 2566821630 EngTurboWastegateActuator4Pos 1191;
BA_ "SigType" SG_ 2566821630 EngTurboWastegateActuator3Pos 1;
BA_ "SPN" SG_ 2566821630 EngTurboWastegateActuator3Pos 1190;
BA_ "SigType" SG_ 2566821630 EngTurboWastegateActuator2Pos 1;
BA_ "SPN" SG_ 2566821630 EngTurboWastegateActuator2Pos 1189;
BA_ "SigType" SG_ 2566821630 EngTurboWastegateActuator1Pos 1;
BA_ "SPN" SG_ 2566821630 EngTurboWastegateActuator1Pos 1188;
BA_ "SigType" SG_ 2566821630 EngTrbWstgtActuatorCtrlAirPress 1;
BA_ "SPN" SG_ 2566821630 EngTrbWstgtActuatorCtrlAirPress 1192;
BA_ "SigType" SG_ 2365484286 VehicleOverspeed 4;
BA_ "SPN" SG_ 2365484286 VehicleOverspeed 1614;
BA_ "SigType" SG_ 2365484286 VehicleMotion 4;
BA_ "SPN" SG_ 2365484286 VehicleMotion 1611;
BA_ "SigType" SG_ 2365484286 TachographVehicleSpeed 1;
BA_ "SPN" SG_ 2365484286 TachographVehicleSpeed 1624;
BA_ "SigType" SG_ 2365484286 TachographOutputShaftSpeed 1;
BA_ "SPN" SG_ 2365484286 TachographOutputShaftSpeed 1623;
BA_ "SigType" SG_ 2365484286 DirectionIndicator 4;
BA_ "SPN" SG_ 2365484286 DirectionIndicator 1619;
BA_ "SigType" SG_ 2365484286 TachographPerformance 4;
BA_ "SPN" SG_ 2365484286 TachographPerformance 1620;
BA_ "SigType" SG_ 2365484286 HandlingInformation 4;
BA_ "SPN" SG_ 2365484286 HandlingInformation 1621;
BA_ "SigType" SG_ 2365484286 SystemEvent 4;
BA_ "SPN" SG_ 2365484286 SystemEvent 1622;
BA_ "SigType" SG_ 2365484286 DriverCardDriver2 4;
BA_ "SPN" SG_ 2365484286 DriverCardDriver2 1616;
BA_ "SigType" SG_ 2365484286 Driver2TimeRelatedStates 4;
BA_ "SPN" SG_ 2365484286 Driver2TimeRelatedStates 1618;
BA_ "SigType" SG_ 2365484286 DriverCardDriver1 4;
BA_ "SPN" SG_ 2365484286 DriverCardDriver1 1615;
BA_ "SigType" SG_ 2365484286 Driver1TimeRelatedStates 4;
BA_ "SPN" SG_ 2365484286 Driver1TimeRelatedStates 1617;
BA_ "SPN" SG_ 2365484286 Driver2WorkingState 1613;
BA_ "SPN" SG_ 2365484286 Driver1WorkingState 1612;
BA_ "SigType" SG_ 2566771710 EngTurbo4CompressorOutletTemp 1;
BA_ "SPN" SG_ 2566771710 EngTurbo4CompressorOutletTemp 2801;
BA_ "SigType" SG_ 2566771710 EngTurbo3CompressorOutletTemp 1;
BA_ "SPN" SG_ 2566771710 EngTurbo3CompressorOutletTemp 2800;
BA_ "SigType" SG_ 2566771710 EngTurbo2CompressorOutletTemp 1;
BA_ "SPN" SG_ 2566771710 EngTurbo2CompressorOutletTemp 2799;
BA_ "SigType" SG_ 2566771710 EngTurbo1CompressorOutletTemp 1;
BA_ "SPN" SG_ 2566771710 EngTurbo1CompressorOutletTemp 2629;
BA_ "SigType" SG_ 2566821886 EngTurbo4TurbineOutletTemp 1;
BA_ "SPN" SG_ 2566821886 EngTurbo4TurbineOutletTemp 1187;
BA_ "SigType" SG_ 2566821886 EngTurbo3TurbineOutletTemp 1;
BA_ "SPN" SG_ 2566821886 EngTurbo3TurbineOutletTemp 1186;
BA_ "SigType" SG_ 2566821886 EngTurbo2TurbineOutletTemp 1;
BA_ "SPN" SG_ 2566821886 EngTurbo2TurbineOutletTemp 1185;
BA_ "SigType" SG_ 2566821886 EngTurbo1TurbineOutletTemp 1;
BA_ "SPN" SG_ 2566821886 EngTurbo1TurbineOutletTemp 1184;
BA_ "SigType" SG_ 2566822142 EngTurbo4TurbineIntakeTemp 1;
BA_ "SPN" SG_ 2566822142 EngTurbo4TurbineIntakeTemp 1183;
BA_ "SigType" SG_ 2566822142 EngTurbo3TurbineIntakeTemp 1;
BA_ "SPN" SG_ 2566822142 EngTurbo3TurbineIntakeTemp 1182;
BA_ "SigType" SG_ 2566822142 EngTurbo2TurbineIntakeTemp 1;
BA_ "SPN" SG_ 2566822142 EngTurbo2TurbineIntakeTemp 1181;
BA_ "SigType" SG_ 2566822142 EngTurbo1TurbineIntakeTemp 1;
BA_ "SPN" SG_ 2566822142 EngTurbo1TurbineIntakeTemp 1180;
BA_ "SigType" SG_ 2566822144 EngTurbo4CompressorIntakePress 1;
BA_ "SPN" SG_ 2566822144 EngTurbo4CompressorIntakePress 1179;
BA_ "SigType" SG_ 2566822144 EngTurbo3CompressorIntakePress 1;
BA_ "SPN" SG_ 2566822144 EngTurbo3CompressorIntakePress 1178;
BA_ "SigType" SG_ 2566822144 EngTurbo2CompressorIntakePress 1;
BA_ "SPN" SG_ 2566822144 EngTurbo2CompressorIntakePress 1177;
BA_ "SigType" SG_ 2566822144 EngTurbo1CompressorIntakePress 1;
BA_ "SPN" SG_ 2566822144 EngTurbo1CompressorIntakePress 1176;
BA_ "SigType" SG_ 2566822400 EngTurbo4CompressorIntakeTemp 1;
BA_ "SPN" SG_ 2566822400 EngTurbo4CompressorIntakeTemp 1175;
BA_ "SigType" SG_ 2566822400 EngTurbo3CompressorIntakeTemp 1;
BA_ "SPN" SG_ 2566822400 EngTurbo3CompressorIntakeTemp 1174;
BA_ "SigType" SG_ 2566822400 EngTurbo2CompressorIntakeTemp 1;
BA_ "SPN" SG_ 2566822400 EngTurbo2CompressorIntakeTemp 1173;
BA_ "SigType" SG_ 2566822400 EngTurbo1CompressorIntakeTemp 1;
BA_ "SPN" SG_ 2566822400 EngTurbo1CompressorIntakeTemp 1172;
BA_ "SigType" SG_ 2633931520 EngTurbo4Speed 1;
BA_ "SPN" SG_ 2633931520 EngTurbo4Speed 1171;
BA_ "SigType" SG_ 2633931520 EngTurbo3Speed 1;
BA_ "SPN" SG_ 2633931520 EngTurbo3Speed 1170;
BA_ "SigType" SG_ 2633931520 EngTurbo2Speed 1;
BA_ "SPN" SG_ 2633931520 EngTurbo2Speed 1169;
BA_ "SigType" SG_ 2633931520 EngTurboLubeOilPress2 1;
BA_ "SPN" SG_ 2633931520 EngTurboLubeOilPress2 1168;
BA_ "SigType" SG_ 2566802430 TransTorqueLimit 1;
BA_ "SPN" SG_ 2566802430 TransTorqueLimit 1845;
BA_ "SigType" SG_ 2566841086 TransGearRatio 1;
BA_ "SPN" SG_ 2566841086 TransGearRatio 581;
BA_ "SigType" SG_ 2566841086 NumberOfForwardGearRatios 1;
BA_ "SPN" SG_ 2566841086 NumberOfForwardGearRatios 957;
BA_ "SigType" SG_ 2566841086 NumberOfReverseGearRatios 1;
BA_ "SPN" SG_ 2566841086 NumberOfReverseGearRatios 958;
BA_ "SigType" SG_ 2348876549 TrnsShftSlctorDisplayModeSwitch 4;
BA_ "SPN" SG_ 2348876549 TrnsShftSlctorDisplayModeSwitch 2985;
BA_ "SigType" SG_ 2348876549 TransMode4 4;
BA_ "SPN" SG_ 2348876549 TransMode4 1855;
BA_ "SigType" SG_ 2348876549 TransMode3 4;
BA_ "SPN" SG_ 2348876549 TransMode3 1854;
BA_ "SigType" SG_ 2348876549 TransMode2 4;
BA_ "SPN" SG_ 2348876549 TransMode2 1853;
BA_ "SigType" SG_ 2348876549 TransMode1 4;
BA_ "SPN" SG_ 2348876549 TransMode1 1852;
BA_ "SigType" SG_ 2348876549 DisengageDiffLockRqCentralRear 4;
BA_ "SPN" SG_ 2348876549 DisengageDiffLockRqCentralRear 691;
BA_ "SigType" SG_ 2348876549 DisengageDiffLockRqCentralFront 4;
BA_ "SPN" SG_ 2348876549 DisengageDiffLockRqCentralFront 690;
BA_ "SigType" SG_ 2348876549 DisengageDiffLockRqCentral 4;
BA_ "SPN" SG_ 2348876549 DisengageDiffLockRqCentral 689;
BA_ "SigType" SG_ 2348876549 DisengageDiffLockRqRearAxle2 4;
BA_ "SPN" SG_ 2348876549 DisengageDiffLockRqRearAxle2 688;
BA_ "SigType" SG_ 2348876549 DisengageDiffLockRqRearAxle1 4;
BA_ "SPN" SG_ 2348876549 DisengageDiffLockRqRearAxle1 687;
BA_ "SigType" SG_ 2348876549 DisengageDiffLockRqFrontAxle2 4;
BA_ "SPN" SG_ 2348876549 DisengageDiffLockRqFrontAxle2 686;
BA_ "SigType" SG_ 2348876549 DisengageDiffLockRqFrontAxle1 4;
BA_ "SPN" SG_ 2348876549 DisengageDiffLockRqFrontAxle1 685;
BA_ "SigType" SG_ 2348876549 TransRqedGear 1;
BA_ "SPN" SG_ 2348876549 TransRqedGear 525;
BA_ "SigType" SG_ 2348876549 RqedPercentClutchSlip 1;
BA_ "SPN" SG_ 2348876549 RqedPercentClutchSlip 684;
BA_ "SigType" SG_ 2348876549 DisengageDrivelineRq 4;
BA_ "SPN" SG_ 2348876549 DisengageDrivelineRq 683;
BA_ "SigType" SG_ 2348876549 TransGearShiftInhibitRq 4;
BA_ "SPN" SG_ 2348876549 TransGearShiftInhibitRq 681;
BA_ "SigType" SG_ 2348876549 TrnsTrqConverterLockupDisableRq 4;
BA_ "SPN" SG_ 2348876549 TrnsTrqConverterLockupDisableRq 682;
BA_ "SigType" SG_ 2348876549 TransRqedLaunchGear 4;
BA_ "SPN" SG_ 2348876549 TransRqedLaunchGear 4255;
BA_ "SigType" SG_ 2348876549 TransReverseGearShiftInhibitRq 4;
BA_ "SPN" SG_ 2348876549 TransReverseGearShiftInhibitRq 4242;
BA_ "SigType" SG_ 2348876549 TransMode8 4;
BA_ "SPN" SG_ 2348876549 TransMode8 4249;
BA_ "SigType" SG_ 2348876549 TransMode7 4;
BA_ "SPN" SG_ 2348876549 TransMode7 4248;
BA_ "SigType" SG_ 2348876549 TransMode6 4;
BA_ "SPN" SG_ 2348876549 TransMode6 4247;
BA_ "SigType" SG_ 2348876549 TransMode5 4;
BA_ "SPN" SG_ 2348876549 TransMode5 4246;
BA_ "SigType" SG_ 2566839552 EngTurboOilLevelSwitch 4;
BA_ "SPN" SG_ 2566839552 EngTurboOilLevelSwitch 1665;
BA_ "SigType" SG_ 2566839552 EngTurbo1Speed 1;
BA_ "SPN" SG_ 2566839552 EngTurbo1Speed 103;
BA_ "SigType" SG_ 2566839552 EngTurboLubeOilPress1 1;
BA_ "SPN" SG_ 2566839552 EngTurboLubeOilPress1 104;
BA_ "SigType" SG_ 2633911806 EngTotalAverageFuelEconomy 1;
BA_ "SPN" SG_ 2633911806 EngTotalAverageFuelEconomy 1835;
BA_ "SigType" SG_ 2633911806 EngTotalAverageFuelRate 1;
BA_ "SPN" SG_ 2633911806 EngTotalAverageFuelRate 1834;
BA_ "SigType" SG_ 2566775550 AirSuspensionSupplyPressRq 1;
BA_ "SPN" SG_ 2566775550 AirSuspensionSupplyPressRq 2608;
BA_ "SigType" SG_ 2566775550 AuxEquipmentSupplyPressRq 1;
BA_ "SPN" SG_ 2566775550 AuxEquipmentSupplyPressRq 2607;
BA_ "SigType" SG_ 2566775550 ServiceBrakeAirPressRqCircuit2 1;
BA_ "SPN" SG_ 2566775550 ServiceBrakeAirPressRqCircuit2 2606;
BA_ "SigType" SG_ 2566775550 ServiceBrakeAirPressRqCircuit1 1;
BA_ "SPN" SG_ 2566775550 ServiceBrakeAirPressRqCircuit1 2605;
BA_ "SigType" SG_ 2566775550 ParkingAnd_OrTrailerAirPressRq 1;
BA_ "SPN" SG_ 2566775550 ParkingAnd_OrTrailerAirPressRq 2604;
BA_ "SigType" SG_ 2566775550 PneumaticSupplyPressRq 1;
BA_ "SPN" SG_ 2566775550 PneumaticSupplyPressRq 2603;
BA_ "SigType" SG_ 2566819838 EngExtlShutdownAirSupplyPress 1;
BA_ "SPN" SG_ 2566819838 EngExtlShutdownAirSupplyPress 1320;
BA_ "SigType" SG_ 2566839038 NmbrOfSftwrIdentificationFields 1;
BA_ "SPN" SG_ 2566839038 NmbrOfSftwrIdentificationFields 965;
BA_ "SigType" SG_ 2566839038 SoftwareID3 8;
BA_ "SPN" SG_ 2566839038 SoftwareID3 234;
BA_ "SigType" SG_ 2566839038 SoftwareID2 8;
BA_ "SPN" SG_ 2566839038 SoftwareID2 234;
BA_ "SigType" SG_ 2566839038 SoftwareID1 8;
BA_ "SPN" SG_ 2566839038 SoftwareID1 234;
BA_ "SigType" SG_ 2566841344 EngOverspeedTest 4;
BA_ "SPN" SG_ 2566841344 EngOverspeedTest 2812;
BA_ "SigType" SG_ 2566841344 EngAirShutoffCmdStatus 4;
BA_ "SPN" SG_ 2566841344 EngAirShutoffCmdStatus 2813;
BA_ "SigType" SG_ 2566841344 EngAlarmOutputCmdStatus 4;
BA_ "SPN" SG_ 2566841344 EngAlarmOutputCmdStatus 2814;
BA_ "SigType" SG_ 2566841344 EngAlarmAcknowledge 4;
BA_ "SPN" SG_ 2566841344 EngAlarmAcknowledge 2815;
BA_ "SigType" SG_ 2566841344 EngProtectionSystemConfig 4;
BA_ "SPN" SG_ 2566841344 EngProtectionSystemConfig 1111;
BA_ "SigType" SG_ 2566841344 EngProtectionSystemTimerState 4;
BA_ "SPN" SG_ 2566841344 EngProtectionSystemTimerState 1107;
BA_ "SigType" SG_ 2566841344 EngPrtectionSystemTimerOverride 4;
BA_ "SPN" SG_ 2566841344 EngPrtectionSystemTimerOverride 1108;
BA_ "SigType" SG_ 2566841344 EngPrtctnSystmApprchingShutdown 4;
BA_ "SPN" SG_ 2566841344 EngPrtctnSystmApprchingShutdown 1109;
BA_ "SigType" SG_ 2566841344 EngWaitToStartLamp 4;
BA_ "SPN" SG_ 2566841344 EngWaitToStartLamp 1081;
BA_ "SigType" SG_ 2566841344 RefrigerantHighPressSwitch 4;
BA_ "SPN" SG_ 2566841344 RefrigerantHighPressSwitch 605;
BA_ "SigType" SG_ 2566841344 RefrigerantLowPressSwitch 4;
BA_ "SPN" SG_ 2566841344 RefrigerantLowPressSwitch 875;
BA_ "SigType" SG_ 2566841344 A_CHighPressFanSwitch 4;
BA_ "SPN" SG_ 2566841344 A_CHighPressFanSwitch 985;
BA_ "SigType" SG_ 2566841344 EngIdleShutdownTimerFunction 4;
BA_ "SPN" SG_ 2566841344 EngIdleShutdownTimerFunction 591;
BA_ "SigType" SG_ 2566841344 EngIdleShutdownTimerState 4;
BA_ "SPN" SG_ 2566841344 EngIdleShutdownTimerState 590;
BA_ "SigType" SG_ 2566841344 EngIdleShutdownTimerOverride 4;
BA_ "SPN" SG_ 2566841344 EngIdleShutdownTimerOverride 592;
BA_ "SigType" SG_ 2566841344 EngIdleShutdownDriverAlertMode 4;
BA_ "SPN" SG_ 2566841344 EngIdleShutdownDriverAlertMode 594;
BA_ "SigType" SG_ 2566841344 PTOShutdownHasShutdownEng 4;
BA_ "SPN" SG_ 2566841344 PTOShutdownHasShutdownEng 5404;
BA_ "SigType" SG_ 2566841344 EngPrtctnSystmHasShutdownEngine 4;
BA_ "SPN" SG_ 2566841344 EngPrtctnSystmHasShutdownEngine 1110;
BA_ "SigType" SG_ 2566841344 EngIdlShutdownHasShutdownEngine 4;
BA_ "SPN" SG_ 2566841344 EngIdlShutdownHasShutdownEngine 593;
BA_ "SigType" SG_ 2566841344 EngAirShutoffStatus 4;
BA_ "SPN" SG_ 2566841344 EngAirShutoffStatus 3667;
BA_ "SigType" SG_ 2566832382 ServiceComponentIdentificationB 1;
BA_ "SPN" SG_ 2566832382 ServiceComponentIdentificationB 912;
BA_ "SigType" SG_ 2566832382 ServiceComponentIdentificationA 1;
BA_ "SPN" SG_ 2566832382 ServiceComponentIdentificationA 911;
BA_ "SigType" SG_ 2566832382 SrvceDelay_OperationalTimeBased 1;
BA_ "SPN" SG_ 2566832382 SrvceDelay_OperationalTimeBased 916;
BA_ "SigType" SG_ 2566832382 ServiceDelay_CalendarTimeBased 1;
BA_ "SPN" SG_ 2566832382 ServiceDelay_CalendarTimeBased 915;
BA_ "SigType" SG_ 2566832382 ServiceDistance 1;
BA_ "SPN" SG_ 2566832382 ServiceDistance 914;
BA_ "SigType" SG_ 2566832382 ServiceComponentIdentification 1;
BA_ "SPN" SG_ 2566832382 ServiceComponentIdentification 1584;
BA_ "SigType" SG_ 2633928446 TimeSinceLastService 1;
BA_ "SPN" SG_ 2633928446 TimeSinceLastService 1350;
BA_ "SigType" SG_ 2633928446 ServiceComponentIdentification 1;
BA_ "SPN" SG_ 2633928446 ServiceComponentIdentification 1584;
BA_ "SigType" SG_ 2566804478 MaxContinuousRetarderTorque 1;
BA_ "SPN" SG_ 2566804478 MaxContinuousRetarderTorque 1782;
BA_ "SigType" SG_ 2566804478 MinContinuousRetarderSpeed 1;
BA_ "SPN" SG_ 2566804478 MinContinuousRetarderSpeed 1781;
BA_ "SigType" SG_ 2566804478 MaxContinuousRetarderSpeed 1;
BA_ "SPN" SG_ 2566804478 MaxContinuousRetarderSpeed 1780;
BA_ "SigType" SG_ 2566804478 MinContinuousRetarderTorque 1;
BA_ "SPN" SG_ 2566804478 MinContinuousRetarderTorque 1783;
BA_ "SigType" SG_ 2566804478 LwLmtThrshldFrMxTrqFromRetarder 1;
BA_ "SPN" SG_ 2566804478 LwLmtThrshldFrMxTrqFromRetarder 1778;
BA_ "SigType" SG_ 2566804478 LwLmtThrshldFrMxRPMFromRetarder 1;
BA_ "SPN" SG_ 2566804478 LwLmtThrshldFrMxRPMFromRetarder 1776;
BA_ "SigType" SG_ 2566804478 HghLmtThrshldFrMnCntnsTrqFrmRtrd 1;
BA_ "SPN" SG_ 2566804478 HghLmtThrshldFrMnCntnsTrqFrmRtrd 1779;
BA_ "SystemSignalLongSymbol" SG_ 2566804478 HghLmtThrshldFrMnCntnsTrqFrmRtrd "HghLmtThrshldFrMnCntnsTrqFrmRtrdr";
BA_ "SigType" SG_ 2566804478 HghLmtThrshldFrMnCntnsRPMFrmRtrd 1;
BA_ "SPN" SG_ 2566804478 HghLmtThrshldFrMnCntnsRPMFrmRtrd 1777;
BA_ "SystemSignalLongSymbol" SG_ 2566804478 HghLmtThrshldFrMnCntnsRPMFrmRtrd "HghLmtThrshldFrMnCntnsRPMFrmRtrdr";
BA_ "SigType" SG_ 2566847486 DrvlneRetarderOverheatIndicator 4;
BA_ "SPN" SG_ 2566847486 DrvlneRetarderOverheatIndicator 5346;
BA_ "SigType" SG_ 2566847486 HydRetarderOilTemp 1;
BA_ "SPN" SG_ 2566847486 HydRetarderOilTemp 120;
BA_ "SigType" SG_ 2566847486 HydRetarderPress 1;
BA_ "SPN" SG_ 2566847486 HydRetarderPress 119;
BA_ "SigType" SG_ 2631859966 EngBuildHoursReset 4;
BA_ "SPN" SG_ 2631859966 EngBuildHoursReset 1211;
BA_ "SigType" SG_ 2631859966 TripGroup2Proprietary 4;
BA_ "SPN" SG_ 2631859966 TripGroup2Proprietary 989;
BA_ "SigType" SG_ 2631859966 TripGroup1 4;
BA_ "SPN" SG_ 2631859966 TripGroup1 988;
BA_ "SigType" SG_ 2631859966 SteerStraightAheadPosReset 4;
BA_ "SPN" SG_ 2631859966 SteerStraightAheadPosReset 3600;
BA_ "SigType" SG_ 2631859966 ServiceComponentIdentification 1;
BA_ "SPN" SG_ 2631859966 ServiceComponentIdentification 1584;
BA_ "SigType" SG_ 2631859966 ServiceComponentIdentificationC 1;
BA_ "SPN" SG_ 2631859966 ServiceComponentIdentificationC 1584;
BA_ "SigType" SG_ 2566840591 PercentTorqueAtPeakTorquePoint5 1;
BA_ "SPN" SG_ 2566840591 PercentTorqueAtPeakTorquePoint5 555;
BA_ "SigType" SG_ 2566840591 ReferenceRetarderTorque 1;
BA_ "SPN" SG_ 2566840591 ReferenceRetarderTorque 556;
BA_ "SigType" SG_ 2566840591 RetarderSpeedAtPeakTorquePoint5 1;
BA_ "SPN" SG_ 2566840591 RetarderSpeedAtPeakTorquePoint5 547;
BA_ "SigType" SG_ 2566840591 PercentTorqueAtPoint4 1;
BA_ "SPN" SG_ 2566840591 PercentTorqueAtPoint4 554;
BA_ "SigType" SG_ 2566840591 RetarderSpeedAtPoint4 1;
BA_ "SPN" SG_ 2566840591 RetarderSpeedAtPoint4 550;
BA_ "SigType" SG_ 2566840591 PercentTorqueAtPoint3 1;
BA_ "SPN" SG_ 2566840591 PercentTorqueAtPoint3 553;
BA_ "SigType" SG_ 2566840591 RetarderSpeedAtPoint3 1;
BA_ "SPN" SG_ 2566840591 RetarderSpeedAtPoint3 549;
BA_ "SigType" SG_ 2566840591 PercentTorqueAtMaxSpeedPoint2 1;
BA_ "SPN" SG_ 2566840591 PercentTorqueAtMaxSpeedPoint2 552;
BA_ "SigType" SG_ 2566840591 MaxRetarderSpeedPoint2 1;
BA_ "SPN" SG_ 2566840591 MaxRetarderSpeedPoint2 548;
BA_ "SigType" SG_ 2566840591 PercentTorqueAtIdlePoint1 1;
BA_ "SPN" SG_ 2566840591 PercentTorqueAtIdlePoint1 551;
BA_ "SigType" SG_ 2566840591 RetarderSpeedAtIdlePoint1 1;
BA_ "SPN" SG_ 2566840591 RetarderSpeedAtIdlePoint1 546;
BA_ "SigType" SG_ 2566840591 RetarderCtrlMethod 1;
BA_ "SPN" SG_ 2566840591 RetarderCtrlMethod 557;
BA_ "SigType" SG_ 2566840591 RetarderLocation 4;
BA_ "SPN" SG_ 2566840591 RetarderLocation 902;
BA_ "SigType" SG_ 2566840591 RetarderType 4;
BA_ "SPN" SG_ 2566840591 RetarderType 901;
BA_ "SigType" SG_ 2633930238 EngOperationTimeSinceRebuild 1;
BA_ "SPN" SG_ 2633930238 EngOperationTimeSinceRebuild 1193;
BA_ "SigType" SG_ 2566844416 PowerTakeoffSetSpeed 1;
BA_ "SPN" SG_ 2566844416 PowerTakeoffSetSpeed 187;
BA_ "SigType" SG_ 2566844416 PowerTakeoffSpeed 1;
BA_ "SPN" SG_ 2566844416 PowerTakeoffSpeed 186;
BA_ "SigType" SG_ 2566844416 PowerTakeoffOilTemp 1;
BA_ "SPN" SG_ 2566844416 PowerTakeoffOilTemp 90;
BA_ "SigType" SG_ 2566844416 OprtrEngPTOGvrnrMmrySlectSwitch 4;
BA_ "SPN" SG_ 2566844416 OprtrEngPTOGvrnrMmrySlectSwitch 2897;
BA_ "SigType" SG_ 2566844416 EngRmtPTOGvrnrVrblSpdCtrlSwitch 4;
BA_ "SPN" SG_ 2566844416 EngRmtPTOGvrnrVrblSpdCtrlSwitch 978;
BA_ "SigType" SG_ 2566844416 EngRmtPTOGvrnrPrprgrmmdSpdCtrlSw 4;
BA_ "SPN" SG_ 2566844416 EngRmtPTOGvrnrPrprgrmmdSpdCtrlSw 979;
BA_ "SystemSignalLongSymbol" SG_ 2566844416 EngRmtPTOGvrnrPrprgrmmdSpdCtrlSw "EngRmtPTOGvrnrPrprgrmmdSpdCtrlSwtch";
BA_ "SigType" SG_ 2566844416 EngPTOGvrnrCst_DecelerateSwitch 4;
BA_ "SPN" SG_ 2566844416 EngPTOGvrnrCst_DecelerateSwitch 983;
BA_ "SigType" SG_ 2566844416 EngPTOGovernorSetSwitch 4;
BA_ "SPN" SG_ 2566844416 EngPTOGovernorSetSwitch 984;
BA_ "SigType" SG_ 2566844416 EngPTOGovernorResumeSwitch 4;
BA_ "SPN" SG_ 2566844416 EngPTOGovernorResumeSwitch 982;
BA_ "SigType" SG_ 2566844416 EngPTOGovernorEnableSwitch 4;
BA_ "SPN" SG_ 2566844416 EngPTOGovernorEnableSwitch 980;
BA_ "SigType" SG_ 2566844416 EngPTOGovernorAccelerateSwitch 4;
BA_ "SPN" SG_ 2566844416 EngPTOGovernorAccelerateSwitch 981;
BA_ "SigType" SG_ 2566844416 RmtPTOPrprgrmmdSpeedCtrlSwitch2 4;
BA_ "SPN" SG_ 2566844416 RmtPTOPrprgrmmdSpeedCtrlSwitch2 3447;
BA_ "SigType" SG_ 2566844416 AuxInputIgnoreSwitch 4;
BA_ "SPN" SG_ 2566844416 AuxInputIgnoreSwitch 3448;
BA_ "SPN" SG_ 2566770174 RearWasherFunction 2868;
BA_ "SPN" SG_ 2566770174 FrontOperatorWasherSwitch 2866;
BA_ "SPN" SG_ 2566770174 FrontNonoperatorWasherSwitch 2867;
BA_ "SigType" SG_ 2566770174 RearWiperDelayCtrl 1;
BA_ "SPN" SG_ 2566770174 RearWiperDelayCtrl 2871;
BA_ "SigType" SG_ 2566770174 FrontNonoperatorWiperDelayCtrl 1;
BA_ "SPN" SG_ 2566770174 FrontNonoperatorWiperDelayCtrl 2870;
BA_ "SigType" SG_ 2566770174 FrontOperatorWiperDelayCtrl 1;
BA_ "SPN" SG_ 2566770174 FrontOperatorWiperDelayCtrl 2869;
BA_ "SigType" SG_ 2566770174 RearWiperSwitch 4;
BA_ "SPN" SG_ 2566770174 RearWiperSwitch 2865;
BA_ "SigType" SG_ 2566770174 FrontOperatorWiperSwitch 4;
BA_ "SPN" SG_ 2566770174 FrontOperatorWiperSwitch 2863;
BA_ "SigType" SG_ 2566770174 FrontNonoperatorWiperSwitch 4;
BA_ "SPN" SG_ 2566770174 FrontNonoperatorWiperSwitch 2864;
BA_ "SigType" SG_ 2566769662 EngAltDroopAuxInputSelect 4;
BA_ "SPN" SG_ 2566769662 EngAltDroopAuxInputSelect 2885;
BA_ "SigType" SG_ 2566769662 EngAltDroopRemoteAccelSelect 4;
BA_ "SPN" SG_ 2566769662 EngAltDroopRemoteAccelSelect 2886;
BA_ "SigType" SG_ 2566769662 EngAltDroopAccel2Select 4;
BA_ "SPN" SG_ 2566769662 EngAltDroopAccel2Select 2879;
BA_ "SigType" SG_ 2566769662 EngAltDroopAccel1Select 4;
BA_ "SPN" SG_ 2566769662 EngAltDroopAccel1Select 2881;
BA_ "SigType" SG_ 2566769662 EngAltRatingSelect 1;
BA_ "SPN" SG_ 2566769662 EngAltRatingSelect 2882;
BA_ "SigType" SG_ 2566769662 EngAltLowIdleSwitch 4;
BA_ "SPN" SG_ 2566769662 EngAltLowIdleSwitch 2883;
BA_ "SigType" SG_ 2566769662 EngSynchronizationSwitch 4;
BA_ "SPN" SG_ 2566769662 EngSynchronizationSwitch 1377;
BA_ "SigType" SG_ 2566769662 EngAuxGovernorSwitch 4;
BA_ "SPN" SG_ 2566769662 EngAuxGovernorSwitch 2884;
BA_ "SigType" SG_ 2566768638 EngAltDroopAuxInputSelectState 4;
BA_ "SPN" SG_ 2566768638 EngAltDroopAuxInputSelectState 2895;
BA_ "SigType" SG_ 2566768638 EngAltDrpRemoteAccelSelectState 4;
BA_ "SPN" SG_ 2566768638 EngAltDrpRemoteAccelSelectState 2894;
BA_ "SigType" SG_ 2566768638 EngAltDroopAccel2SelectState 4;
BA_ "SPN" SG_ 2566768638 EngAltDroopAccel2SelectState 2893;
BA_ "SigType" SG_ 2566768638 EngAltDroopAccel1SelectState 4;
BA_ "SPN" SG_ 2566768638 EngAltDroopAccel1SelectState 2889;
BA_ "SigType" SG_ 2566768638 EngAltRatingSelectState 1;
BA_ "SPN" SG_ 2566768638 EngAltRatingSelectState 2888;
BA_ "SigType" SG_ 2566768638 EngAltLowIdleSelectState 4;
BA_ "SPN" SG_ 2566768638 EngAltLowIdleSelectState 2891;
BA_ "SigType" SG_ 2566768638 EngMultiUnitSyncState 4;
BA_ "SPN" SG_ 2566768638 EngMultiUnitSyncState 2890;
BA_ "SigType" SG_ 2566768638 EngAuxGovernorState 4;
BA_ "SPN" SG_ 2566768638 EngAuxGovernorState 2896;
BA_ "SigType" SG_ 2365443326 OprtrsDesiredDelayedLampOffTime 1;
BA_ "SPN" SG_ 2365443326 OprtrsDesiredDelayedLampOffTime 2877;
BA_ "SigType" SG_ 2365443326 OperatorsDesiredBacklight 1;
BA_ "SPN" SG_ 2365443326 OperatorsDesiredBacklight 2878;
BA_ "SigType" SG_ 2365443326 HighLowBeamSwitch 4;
BA_ "SPN" SG_ 2365443326 HighLowBeamSwitch 2874;
BA_ "SigType" SG_ 2365443326 HazardLightSwitch 4;
BA_ "SPN" SG_ 2365443326 HazardLightSwitch 2875;
BA_ "SigType" SG_ 2365443326 TurnSignalSwitch 4;
BA_ "SPN" SG_ 2365443326 TurnSignalSwitch 2876;
BA_ "SigType" SG_ 2365443326 MainLightSwitch 4;
BA_ "SPN" SG_ 2365443326 MainLightSwitch 2872;
BA_ "SigType" SG_ 2365443326 WorkLightSwitch 4;
BA_ "SPN" SG_ 2365443326 WorkLightSwitch 2873;
BA_ "SigType" SG_ 2566776318 AppliedVehicleSpeedLimit 1;
BA_ "SPN" SG_ 2566776318 AppliedVehicleSpeedLimit 2595;
BA_ "SigType" SG_ 2566776318 MaxVehicleSpeedLimit7 1;
BA_ "SPN" SG_ 2566776318 MaxVehicleSpeedLimit7 2594;
BA_ "SigType" SG_ 2566776318 MaxVehicleSpeedLimit6 1;
BA_ "SPN" SG_ 2566776318 MaxVehicleSpeedLimit6 2593;
BA_ "SigType" SG_ 2566776318 MaxVehicleSpeedLimit5 1;
BA_ "SPN" SG_ 2566776318 MaxVehicleSpeedLimit5 2592;
BA_ "SigType" SG_ 2566776318 MaxVehicleSpeedLimit4 1;
BA_ "SPN" SG_ 2566776318 MaxVehicleSpeedLimit4 2591;
BA_ "SigType" SG_ 2566776318 MaxVehicleSpeedLimit3 1;
BA_ "SPN" SG_ 2566776318 MaxVehicleSpeedLimit3 2590;
BA_ "SigType" SG_ 2566776318 MaxVehicleSpeedLimit2 1;
BA_ "SPN" SG_ 2566776318 MaxVehicleSpeedLimit2 2589;
BA_ "SigType" SG_ 2566776318 MaxVehicleSpeedLimit1 1;
BA_ "SPN" SG_ 2566776318 MaxVehicleSpeedLimit1 2588;
BA_ "SigType" SG_ 2566802686 OprtrsBlckOutIntensitySelection 1;
BA_ "SPN" SG_ 2566802686 OprtrsBlckOutIntensitySelection 1844;
BA_ "SigType" SG_ 2566802686 BlackOutWorkLampSelect 4;
BA_ "SPN" SG_ 2566802686 BlackOutWorkLampSelect 1842;
BA_ "SigType" SG_ 2566802686 NightVisionIlluminatorSelect 4;
BA_ "SPN" SG_ 2566802686 NightVisionIlluminatorSelect 1843;
BA_ "SigType" SG_ 2566802686 BlackOutBrake_StopLampSelect 4;
BA_ "SPN" SG_ 2566802686 BlackOutBrake_StopLampSelect 1841;
BA_ "SigType" SG_ 2566802686 ConvoyDrivingLampSelect 4;
BA_ "SPN" SG_ 2566802686 ConvoyDrivingLampSelect 1837;
BA_ "SigType" SG_ 2566802686 ConvoyLampSelect 4;
BA_ "SPN" SG_ 2566802686 ConvoyLampSelect 1838;
BA_ "SigType" SG_ 2566802686 FrontBlackOutMarkerLampSelect 4;
BA_ "SPN" SG_ 2566802686 FrontBlackOutMarkerLampSelect 1839;
BA_ "SigType" SG_ 2566802686 RearBlackOutMarkerSelect 4;
BA_ "SPN" SG_ 2566802686 RearBlackOutMarkerSelect 1840;
BA_ "SigType" SG_ 2566774014 SlowVesselModeStatus 4;
BA_ "SPN" SG_ 2566774014 SlowVesselModeStatus 2617;
BA_ "SigType" SG_ 2566774014 TrollingModeStatus 4;
BA_ "SPN" SG_ 2566774014 TrollingModeStatus 2616;
BA_ "SigType" SG_ 2566774014 EngThrttlSynchrnztionModeStatus 4;
BA_ "SPN" SG_ 2566774014 EngThrttlSynchrnztionModeStatus 2615;
BA_ "SigType" SG_ 2566823166 EngMainBearing11Temp 1;
BA_ "SPN" SG_ 2566823166 EngMainBearing11Temp 1167;
BA_ "SigType" SG_ 2566823166 EngMainBearing10Temp 1;
BA_ "SPN" SG_ 2566823166 EngMainBearing10Temp 1166;
BA_ "SigType" SG_ 2566823166 EngMainBearing9Temp 1;
BA_ "SPN" SG_ 2566823166 EngMainBearing9Temp 1165;
BA_ "SigType" SG_ 2566823422 EngMainBearing8Temp 1;
BA_ "SPN" SG_ 2566823422 EngMainBearing8Temp 1164;
BA_ "SigType" SG_ 2566823422 EngMainBearing7Temp 1;
BA_ "SPN" SG_ 2566823422 EngMainBearing7Temp 1163;
BA_ "SigType" SG_ 2566823422 EngMainBearing6Temp 1;
BA_ "SPN" SG_ 2566823422 EngMainBearing6Temp 1162;
BA_ "SigType" SG_ 2566823422 EngMainBearing5Temp 1;
BA_ "SPN" SG_ 2566823422 EngMainBearing5Temp 1161;
BA_ "SigType" SG_ 2566823678 EngMainBearing4Temp 1;
BA_ "SPN" SG_ 2566823678 EngMainBearing4Temp 1160;
BA_ "SigType" SG_ 2566823678 EngMainBearing3Temp 1;
BA_ "SPN" SG_ 2566823678 EngMainBearing3Temp 1159;
BA_ "SigType" SG_ 2566823678 EngMainBearing2Temp 1;
BA_ "SPN" SG_ 2566823678 EngMainBearing2Temp 1158;
BA_ "SigType" SG_ 2566823678 EngMainBearing1Temp 1;
BA_ "SPN" SG_ 2566823678 EngMainBearing1Temp 1157;
BA_ "SigType" SG_ 2432595710 DisplayDeadbands 4;
BA_ "SPN" SG_ 2432595710 DisplayDeadbands 2577;
BA_ "SigType" SG_ 2432595710 LEDPatternCtrl 4;
BA_ "SPN" SG_ 2432595710 LEDPatternCtrl 2578;
BA_ "SigType" SG_ 2432595710 LEDDisplayDeadbandCtrl 4;
BA_ "SPN" SG_ 2432595710 LEDDisplayDeadbandCtrl 1806;
BA_ "SigType" SG_ 2432595710 LEDDisplayModeCtrl 4;
BA_ "SPN" SG_ 2432595710 LEDDisplayModeCtrl 1805;
BA_ "SigType" SG_ 2432595710 LEDDisplayData1 1;
BA_ "SPN" SG_ 2432595710 LEDDisplayData1 1573;
BA_ "SigType" SG_ 2365486590 LaserStrikeDataLatency 1;
BA_ "SPN" SG_ 2365486590 LaserStrikeDataLatency 2793;
BA_ "SigType" SG_ 2365486590 LaserReceiverType 1;
BA_ "SPN" SG_ 2365486590 LaserReceiverType 2576;
BA_ "SigType" SG_ 2365486590 LaserStrikeVerticalDeviation 1;
BA_ "SPN" SG_ 2365486590 LaserStrikeVerticalDeviation 1574;
BA_ "SigType" SG_ 2365486590 AbsLaserStrikePos 1;
BA_ "SPN" SG_ 2365486590 AbsLaserStrikePos 2794;
BA_ "SigType" SG_ 2365485566 LaserTracerInformation 1;
BA_ "SPN" SG_ 2365485566 LaserTracerInformation 1583;
BA_ "SigType" SG_ 2365485566 LEDDisplayData2 1;
BA_ "SPN" SG_ 2365485566 LEDDisplayData2 1582;
BA_ "SigType" SG_ 2365485566 LaserTracerHorizontalDeviation 1;
BA_ "SPN" SG_ 2365485566 LaserTracerHorizontalDeviation 1581;
BA_ "SigType" SG_ 2365485566 LaserTracerVerticalDistance 1;
BA_ "SPN" SG_ 2365485566 LaserTracerVerticalDistance 1580;
BA_ "SigType" SG_ 2365485566 LaserTracerTargetDeviation 1;
BA_ "SPN" SG_ 2365485566 LaserTracerTargetDeviation 1579;
BA_ "SigType" SG_ 2633939454 TripCruiseFuelUsed 1;
BA_ "SPN" SG_ 2633939454 TripCruiseFuelUsed 1005;
BA_ "SigType" SG_ 2633939454 TripVehicleIdleFuelUsed 1;
BA_ "SPN" SG_ 2633939454 TripVehicleIdleFuelUsed 1004;
BA_ "SigType" SG_ 2633939454 TripDriveFuelUsed 1;
BA_ "SPN" SG_ 2633939454 TripDriveFuelUsed 1001;
BA_ "SigType" SG_ 2633939454 TrpPTOGovernorNonmovingFuelUsed 1;
BA_ "SPN" SG_ 2633939454 TrpPTOGovernorNonmovingFuelUsed 1003;
BA_ "SigType" SG_ 2633939454 TripPTOGovernorMovingFuelUsed 1;
BA_ "SPN" SG_ 2633939454 TripPTOGovernorMovingFuelUsed 1002;
BA_ "SigType" SG_ 2633939454 TripDriveFuelEconomy 1;
BA_ "SPN" SG_ 2633939454 TripDriveFuelEconomy 1006;
BA_ "SigType" SG_ 2365486334 BldHeightSetPointHighResolution 1;
BA_ "SPN" SG_ 2365486334 BldHeightSetPointHighResolution 1759;
BA_ "SigType" SG_ 2365486334 ModifyLevelingSystemSetPoint 1;
BA_ "SPN" SG_ 2365486334 ModifyLevelingSystemSetPoint 1575;
BA_ "SigType" SG_ 2364542462 SdshftDsrdBldOffsetOperatorCtrl 4;
BA_ "SPN" SG_ 2364542462 SdshftDsrdBldOffsetOperatorCtrl 3339;
BA_ "SigType" SG_ 2364542462 SdshftBldCtrlMdeOperatorControl 4;
BA_ "SPN" SG_ 2364542462 SdshftBldCtrlMdeOperatorControl 3338;
BA_ "SigType" SG_ 2364542462 RghtDsrdBladeOffsetOperatorCtrl 4;
BA_ "SPN" SG_ 2364542462 RghtDsrdBladeOffsetOperatorCtrl 3337;
BA_ "SigType" SG_ 2364542462 RghtBldeCtrlModeOperatorControl 4;
BA_ "SPN" SG_ 2364542462 RghtBldeCtrlModeOperatorControl 3335;
BA_ "SigType" SG_ 2364542462 LftDsredBladeOffsetOperatorCtrl 4;
BA_ "SPN" SG_ 2364542462 LftDsredBladeOffsetOperatorCtrl 3336;
BA_ "SigType" SG_ 2364542462 LftBladeCtrlModeOperatorControl 4;
BA_ "SPN" SG_ 2364542462 LftBladeCtrlModeOperatorControl 3334;
BA_ "SigType" SG_ 2364542462 BladeAutoModeCmd 4;
BA_ "SPN" SG_ 2364542462 BladeAutoModeCmd 3158;
BA_ "SigType" SG_ 2364542462 DesiredGradeOffsetSwitch 4;
BA_ "SPN" SG_ 2364542462 DesiredGradeOffsetSwitch 3157;
BA_ "SigType" SG_ 2364542462 BladeCtrlModeSwitch 4;
BA_ "SPN" SG_ 2364542462 BladeCtrlModeSwitch 3156;
BA_ "SigType" SG_ 2364542462 StElvtnSnsor2ReferenceElevation 4;
BA_ "SPN" SG_ 2364542462 StElvtnSnsor2ReferenceElevation 5406;
BA_ "SigType" SG_ 2364542462 StElvtnSnsor1ReferenceElevation 4;
BA_ "SPN" SG_ 2364542462 StElvtnSnsor1ReferenceElevation 5405;
BA_ "SigType" SG_ 2365486078 MastPos 1;
BA_ "SPN" SG_ 2365486078 MastPos 1576;
BA_ "SigType" SG_ 2633937918 TotalEngPTOGovernorFuelUsed 1;
BA_ "SPN" SG_ 2633937918 TotalEngPTOGovernorFuelUsed 1028;
BA_ "SigType" SG_ 2633937918 TripAverageFuelRate 1;
BA_ "SPN" SG_ 2633937918 TripAverageFuelRate 1029;
BA_ "SigType" SG_ 2633937918 FlexibleFuelPercentage 1;
BA_ "SPN" SG_ 2633937918 FlexibleFuelPercentage 5458;
BA_ "SigType" SG_ 2566844928 EngAverageFuelEconomy 1;
BA_ "SPN" SG_ 2566844928 EngAverageFuelEconomy 185;
BA_ "SigType" SG_ 2566844928 EngInstantaneousFuelEconomy 1;
BA_ "SPN" SG_ 2566844928 EngInstantaneousFuelEconomy 184;
BA_ "SigType" SG_ 2566844928 EngFuelRate 1;
BA_ "SPN" SG_ 2566844928 EngFuelRate 183;
BA_ "SigType" SG_ 2566844928 EngThrottleValve2Pos 1;
BA_ "SPN" SG_ 2566844928 EngThrottleValve2Pos 3673;
BA_ "SigType" SG_ 2566844928 EngThrottleValve1Pos 1;
BA_ "SPN" SG_ 2566844928 EngThrottleValve1Pos 51;
BA_ "SigType" SG_ 2566842878 EngTotalFuelUsed 1;
BA_ "SPN" SG_ 2566842878 EngTotalFuelUsed 250;
BA_ "SigType" SG_ 2566842878 EngTripFuel 1;
BA_ "SPN" SG_ 2566842878 EngTripFuel 182;
BA_ "SigType" SG_ 2633883646 FrontWheelDriveActuatorStatus 4;
BA_ "SPN" SG_ 2633883646 FrontWheelDriveActuatorStatus 2612;
BA_ "SigType" SG_ 2633880062 FMSstandardSWversionSupported 1;
BA_ "SPN" SG_ 2633880062 FMSstandardSWversionSupported 2806;
BA_ "SigType" SG_ 2633880062 FMSstandardRqsSupported 4;
BA_ "SPN" SG_ 2633880062 FMSstandardRqsSupported 2805;
BA_ "SigType" SG_ 2633880062 FMSstandardDiagnosticsSupported 4;
BA_ "SPN" SG_ 2633880062 FMSstandardDiagnosticsSupported 2804;
BA_ "SigType" SG_ 2566806526 LnDprtureIndicationEnableStatus 4;
BA_ "SPN" SG_ 2566806526 LnDprtureIndicationEnableStatus 1702;
BA_ "SigType" SG_ 2566806526 LaneTrackingStatusLeftSide 4;
BA_ "SPN" SG_ 2566806526 LaneTrackingStatusLeftSide 1710;
BA_ "SigType" SG_ 2566806526 LaneTrackingStatusRightSide 4;
BA_ "SPN" SG_ 2566806526 LaneTrackingStatusRightSide 1711;
BA_ "SigType" SG_ 2431649790 LaneDepartureImminentLeftSide 4;
BA_ "SPN" SG_ 2431649790 LaneDepartureImminentLeftSide 1700;
BA_ "SigType" SG_ 2431649790 LaneDepartureImminentRightSide 4;
BA_ "SPN" SG_ 2431649790 LaneDepartureImminentRightSide 1701;
BA_ "SigType" SG_ 2431649790 LaneDepartureRight 4;
BA_ "SPN" SG_ 2431649790 LaneDepartureRight 3566;
BA_ "SigType" SG_ 2431649790 LaneDepartureLeft 4;
BA_ "SPN" SG_ 2431649790 LaneDepartureLeft 3565;
BA_ "SigType" SG_ 2633929214 EngFuelLeakage2 4;
BA_ "SPN" SG_ 2633929214 EngFuelLeakage2 1240;
BA_ "SigType" SG_ 2633929214 EngFuelLeakage1 4;
BA_ "SPN" SG_ 2633929214 EngFuelLeakage1 1239;
BA_ "SigType" SG_ 2566831360 FanSpeed 1;
BA_ "SPN" SG_ 2566831360 FanSpeed 1639;
BA_ "SigType" SG_ 2566831360 FanDriveState 4;
BA_ "SPN" SG_ 2566831360 FanDriveState 977;
BA_ "SigType" SG_ 2566831360 EstPercentFanSpeed 1;
BA_ "SPN" SG_ 2566831360 EstPercentFanSpeed 975;
BA_ "SigType" SG_ 2566831360 HydFanMotorPress 1;
BA_ "SPN" SG_ 2566831360 HydFanMotorPress 4211;
BA_ "SigType" SG_ 2566831360 FanDriveBypassCmdStatus 1;
BA_ "SPN" SG_ 2566831360 FanDriveBypassCmdStatus 4212;
BA_ "SigType" SG_ 2566820094 EngTorqueLimit6AxleInput 1;
BA_ "SPN" SG_ 2566820094 EngTorqueLimit6AxleInput 1263;
BA_ "SigType" SG_ 2566820094 EngTorqueLimit5Switch 1;
BA_ "SPN" SG_ 2566820094 EngTorqueLimit5Switch 1262;
BA_ "SigType" SG_ 2566820094 EngTorqueLimit4Trans 1;
BA_ "SPN" SG_ 2566820094 EngTorqueLimit4Trans 1261;
BA_ "SigType" SG_ 2566820094 EngTorqueLimit3Trans 1;
BA_ "SPN" SG_ 2566820094 EngTorqueLimit3Trans 1260;
BA_ "SigType" SG_ 2566820094 TransGearRatio3 1;
BA_ "SPN" SG_ 2566820094 TransGearRatio3 1259;
BA_ "SigType" SG_ 2566820094 EngTorqueLimit2Trans 1;
BA_ "SPN" SG_ 2566820094 EngTorqueLimit2Trans 1258;
BA_ "SigType" SG_ 2566820094 TransGearRatio2 1;
BA_ "SPN" SG_ 2566820094 TransGearRatio2 1257;
BA_ "SigType" SG_ 2566820094 EngTorqueLimit1Trans 1;
BA_ "SPN" SG_ 2566820094 EngTorqueLimit1Trans 1256;
BA_ "SigType" SG_ 2566820094 TransGearRatio1 1;
BA_ "SPN" SG_ 2566820094 TransGearRatio1 1255;
BA_ "SPN" SG_ 2566820094 EngTorqueLimitFeature 1632;
BA_ "SigType" SG_ 2566820094 TorqueLimitingFeatureStatus 4;
BA_ "SPN" SG_ 2566820094 TorqueLimitingFeatureStatus 1254;
BA_ "SigType" SG_ 2566820094 CalibRecordDurationTime 1;
BA_ "SPN" SG_ 2566820094 CalibRecordDurationTime 1253;
BA_ "SigType" SG_ 2566820094 CalibRecordStartYear 1;
BA_ "SPN" SG_ 2566820094 CalibRecordStartYear 1252;
BA_ "SigType" SG_ 2566820094 CalibRecordStartDay 1;
BA_ "SPN" SG_ 2566820094 CalibRecordStartDay 1251;
BA_ "SigType" SG_ 2566820094 CalibRecordStartMonth 1;
BA_ "SPN" SG_ 2566820094 CalibRecordStartMonth 1250;
BA_ "SigType" SG_ 2566820094 EngPeakTorque2 1;
BA_ "SPN" SG_ 2566820094 EngPeakTorque2 1249;
BA_ "SigType" SG_ 2566820094 EngPeakTorque1 1;
BA_ "SPN" SG_ 2566820094 EngPeakTorque1 1248;
BA_ "SigType" SG_ 2566820094 EngPower 1;
BA_ "SPN" SG_ 2566820094 EngPower 1247;
BA_ "SigType" SG_ 2566820094 NumberOfEngTorqueHistoryRecords 1;
BA_ "SPN" SG_ 2566820094 NumberOfEngTorqueHistoryRecords 1246;
BA_ "SigType" SG_ 2364541955 TransClutch_ConverterInputSpeed 1;
BA_ "SPN" SG_ 2364541955 TransClutch_ConverterInputSpeed 5052;
BA_ "SigType" SG_ 2364541955 TransTorqueConverterRatio 1;
BA_ "SPN" SG_ 2364541955 TransTorqueConverterRatio 3030;
BA_ "SigType" SG_ 2566801923 TrnsRvrseGearShiftInhibitStatus 4;
BA_ "SPN" SG_ 2566801923 TrnsRvrseGearShiftInhibitStatus 4261;
BA_ "SigType" SG_ 2566801923 TrnsCrrntRangeDisplayBlankState 4;
BA_ "SPN" SG_ 2566801923 TrnsCrrntRangeDisplayBlankState 4176;
BA_ "SigType" SG_ 2566801923 TransWarningIndicator 4;
BA_ "SPN" SG_ 2566801923 TransWarningIndicator 5344;
BA_ "SigType" SG_ 2566801923 TransMode8Indicator 4;
BA_ "SPN" SG_ 2566801923 TransMode8Indicator 4253;
BA_ "SigType" SG_ 2566801923 TransMode7Indicator 4;
BA_ "SPN" SG_ 2566801923 TransMode7Indicator 4252;
BA_ "SigType" SG_ 2566801923 TransMode6Indicator 4;
BA_ "SPN" SG_ 2566801923 TransMode6Indicator 4251;
BA_ "SigType" SG_ 2566801923 TransMode5Indicator 4;
BA_ "SPN" SG_ 2566801923 TransMode5Indicator 4250;
BA_ "SigType" SG_ 2566801923 TransRqedGearFeedback 1;
BA_ "SPN" SG_ 2566801923 TransRqedGearFeedback 3289;
BA_ "SigType" SG_ 2566801923 TransMode1Indicator 4;
BA_ "SPN" SG_ 2566801923 TransMode1Indicator 2536;
BA_ "SigType" SG_ 2566801923 TransMode2Indicator 4;
BA_ "SPN" SG_ 2566801923 TransMode2Indicator 2537;
BA_ "SigType" SG_ 2566801923 TransMode3Indicator 4;
BA_ "SPN" SG_ 2566801923 TransMode3Indicator 2538;
BA_ "SigType" SG_ 2566801923 TransMode4Indicator 4;
BA_ "SPN" SG_ 2566801923 TransMode4Indicator 2539;
BA_ "SigType" SG_ 2566801923 TransShiftInhibitIndicator 4;
BA_ "SPN" SG_ 2566801923 TransShiftInhibitIndicator 1851;
BA_ "SigType" SG_ 2566801923 TransEngCrankEnable 4;
BA_ "SPN" SG_ 2566801923 TransEngCrankEnable 2900;
BA_ "SigType" SG_ 2566801923 ActiveShiftConsoleIndicator 4;
BA_ "SPN" SG_ 2566801923 ActiveShiftConsoleIndicator 2945;
BA_ "SigType" SG_ 2566801923 TransReadyForBrakeRelease 4;
BA_ "SPN" SG_ 2566801923 TransReadyForBrakeRelease 3086;
BA_ "SigType" SG_ 2566801923 TransRqedRangeDisplayFlashState 4;
BA_ "SPN" SG_ 2566801923 TransRqedRangeDisplayFlashState 1849;
BA_ "SigType" SG_ 2566801923 TransRqedRangeDisplayBlankState 4;
BA_ "SPN" SG_ 2566801923 TransRqedRangeDisplayBlankState 1850;
BA_ "SigType" SG_ 2566801923 TransServiceIndicator 4;
BA_ "SPN" SG_ 2566801923 TransServiceIndicator 4178;
BA_ "SigType" SG_ 2633935619 ClutchLifeRemaining 1;
BA_ "SPN" SG_ 2633935619 ClutchLifeRemaining 2983;
BA_ "SigType" SG_ 2633935619 LowestPossibleGear 1;
BA_ "SPN" SG_ 2633935619 LowestPossibleGear 1114;
BA_ "SigType" SG_ 2633935619 HighestPossibleGear 1;
BA_ "SPN" SG_ 2633935619 HighestPossibleGear 1115;
BA_ "SigType" SG_ 2633935619 RecommendedGear 1;
BA_ "SPN" SG_ 2633935619 RecommendedGear 1113;
VAL_ 2566845694 TirePressThresholdDetection_13 7 "NotAvailable" 6 "ErrorIndicator" 5 "NotDefined" 4 "ExtrmUndrPrssTrPrssrIsAtALvlWhr" 3 "UndrPrssTrPrssrIsLwrThnThPrssrD" 2 "NWrnngPrssTrPrssrIsWthnThThrshl" 1 "OvrPrssTrPrssrIsHghrThnThPrssrD" 0 "ExtrmOvrPrssTrPrssrIsAtALvlWhrT" ;
VAL_ 2566845694 TirePressThresholdDetection_12 7 "NotAvailable" 6 "ErrorIndicator" 5 "NotDefined" 4 "ExtrmUndrPrssTrPrssrIsAtALvlWhr" 3 "UndrPrssTrPrssrIsLwrThnThPrssrD" 2 "NWrnngPrssTrPrssrIsWthnThThrshl" 1 "OvrPrssTrPrssrIsHghrThnThPrssrD" 0 "ExtrmOvrPrssTrPrssrIsAtALvlWhrT" ;
VAL_ 2566845694 TirePressThresholdDetection_11 7 "NotAvailable" 6 "ErrorIndicator" 5 "NotDefined" 4 "ExtrmUndrPrssTrPrssrIsAtALvlWhr" 3 "UndrPrssTrPrssrIsLwrThnThPrssrD" 2 "NWrnngPrssTrPrssrIsWthnThThrshl" 1 "OvrPrssTrPrssrIsHghrThnThPrssrD" 0 "ExtrmOvrPrssTrPrssrIsAtALvlWhrT" ;
VAL_ 2566845694 TirePressThresholdDetection_10 7 "NotAvailable" 6 "ErrorIndicator" 5 "NotDefined" 4 "ExtrmUndrPrssTrPrssrIsAtALvlWhr" 3 "UndrPrssTrPrssrIsLwrThnThPrssrD" 2 "NWrnngPrssTrPrssrIsWthnThThrshl" 1 "OvrPrssTrPrssrIsHghrThnThPrssrD" 0 "ExtrmOvrPrssTrPrssrIsAtALvlWhrT" ;
VAL_ 2566845694 TirePressThresholdDetection_01 7 "NotAvailable" 6 "ErrorIndicator" 5 "NotDefined" 4 "ExtrmUndrPrssTrPrssrIsAtALvlWhr" 3 "UndrPrssTrPrssrIsLwrThnThPrssrD" 2 "NWrnngPrssTrPrssrIsWthnThThrshl" 1 "OvrPrssTrPrssrIsHghrThnThPrssrD" 0 "ExtrmOvrPrssTrPrssrIsAtALvlWhrT" ;
VAL_ 2566845694 CTIWheelSensorStatus_33 3 "NotSupported" 2 "NotDefined" 1 "On" 0 "Off_IsolatedFromCTIPressCtrl" ;
VAL_ 2566845694 CTIWheelSensorStatus_32 3 "NotSupported" 2 "NotDefined" 1 "On" 0 "Off_IsolatedFromCTIPressCtrl" ;
VAL_ 2566845694 CTIWheelSensorStatus_31 3 "NotSupported" 2 "NotDefined" 1 "On" 0 "Off_IsolatedFromCTIPressCtrl" ;
VAL_ 2566845694 CTIWheelSensorStatus_30 3 "NotSupported" 2 "NotDefined" 1 "On" 0 "Off_IsolatedFromCTIPressCtrl" ;
VAL_ 2566845694 CTIWheelSensorStatus_23 3 "NotSupported" 2 "NotDefined" 1 "On" 0 "Off_IsolatedFromCTIPressCtrl" ;
VAL_ 2566845694 CTIWheelSensorStatus_22 3 "NotSupported" 2 "NotDefined" 1 "On" 0 "Off_IsolatedFromCTIPressCtrl" ;
VAL_ 2566845694 CTIWheelSensorStatus_21 3 "NotSupported" 2 "NotDefined" 1 "On" 0 "Off_IsolatedFromCTIPressCtrl" ;
VAL_ 2566845694 CTIWheelSensorStatus_20 3 "NotSupported" 2 "NotDefined" 1 "On" 0 "Off_IsolatedFromCTIPressCtrl" ;
VAL_ 2566845694 CTIWheelSensorStatus_13 3 "NotSupported" 2 "NotDefined" 1 "On" 0 "Off_IsolatedFromCTIPressCtrl" ;
VAL_ 2566845694 CTIWheelSensorStatus_12 3 "NotSupported" 2 "NotDefined" 1 "On" 0 "Off_IsolatedFromCTIPressCtrl" ;
VAL_ 2566845694 CTIWheelSensorStatus_11 3 "NotSupported" 2 "NotDefined" 1 "On" 0 "Off_IsolatedFromCTIPressCtrl" ;
VAL_ 2566845694 CTIWheelSensorStatus_10 3 "NotSupported" 2 "NotDefined" 1 "On" 0 "Off_IsolatedFromCTIPressCtrl" ;
VAL_ 2566845694 CTIWheelSensorStatus_01 3 "NotSupported" 2 "NotDefined" 1 "On" 0 "Off_IsolatedFromCTIPressCtrl" ;
VAL_ 2566845694 CTIWheelEndElectricalFault_33 3 "NotSupported" 2 "Error" 1 "NotDefined" 0 "Ok" ;
VAL_ 2566845694 CTIWheelEndElectricalFault_32 3 "NotSupported" 2 "Error" 1 "NotDefined" 0 "Ok" ;
VAL_ 2566845694 CTIWheelEndElectricalFault_31 3 "NotSupported" 2 "Error" 1 "NotDefined" 0 "Ok" ;
VAL_ 2566845694 CTIWheelEndElectricalFault_30 3 "NotSupported" 2 "Error" 1 "NotDefined" 0 "Ok" ;
VAL_ 2566845694 CTIWheelEndElectricalFault_23 3 "NotSupported" 2 "Error" 1 "NotDefined" 0 "Ok" ;
VAL_ 2566845694 CTIWheelEndElectricalFault_22 3 "NotSupported" 2 "Error" 1 "NotDefined" 0 "Ok" ;
VAL_ 2566845694 CTIWheelEndElectricalFault_21 3 "NotSupported" 2 "Error" 1 "NotDefined" 0 "Ok" ;
VAL_ 2566845694 CTIWheelEndElectricalFault_20 3 "NotSupported" 2 "Error" 1 "NotDefined" 0 "Ok" ;
VAL_ 2566845694 CTIWheelEndElectricalFault_13 3 "NotSupported" 2 "Error" 1 "NotDefined" 0 "Ok" ;
VAL_ 2566845694 CTIWheelEndElectricalFault_12 3 "NotSupported" 2 "Error" 1 "NotDefined" 0 "Ok" ;
VAL_ 2566845694 CTIWheelEndElectricalFault_11 3 "NotSupported" 2 "Error" 1 "NotDefined" 0 "Ok" ;
VAL_ 2566845694 CTIWheelEndElectricalFault_10 3 "NotSupported" 2 "Error" 1 "NotDefined" 0 "Ok" ;
VAL_ 2566845694 CTIWheelEndElectricalFault_01 3 "NotSupported" 2 "Error" 1 "NotDefined" 0 "Ok" ;
VAL_ 2566845694 CTITireStatus_33 3 "NotSupported" 2 "Error" 1 "TireLeakDetected" 0 "Ok" ;
VAL_ 2566845694 CTITireStatus_32 3 "NotSupported" 2 "Error" 1 "TireLeakDetected" 0 "Ok" ;
VAL_ 2566845694 CTITireStatus_31 3 "NotSupported" 2 "Error" 1 "TireLeakDetected" 0 "Ok" ;
VAL_ 2566845694 CTITireStatus_30 3 "NotSupported" 2 "Error" 1 "TireLeakDetected" 0 "Ok" ;
VAL_ 2566845694 CTITireStatus_23 3 "NotSupported" 2 "Error" 1 "TireLeakDetected" 0 "Ok" ;
VAL_ 2566845694 CTITireStatus_22 3 "NotSupported" 2 "Error" 1 "TireLeakDetected" 0 "Ok" ;
VAL_ 2566845694 CTITireStatus_21 3 "NotSupported" 2 "Error" 1 "TireLeakDetected" 0 "Ok" ;
VAL_ 2566845694 CTITireStatus_20 3 "NotSupported" 2 "Error" 1 "TireLeakDetected" 0 "Ok" ;
VAL_ 2566845694 CTITireStatus_13 3 "NotSupported" 2 "Error" 1 "TireLeakDetected" 0 "Ok" ;
VAL_ 2566845694 CTITireStatus_12 3 "NotSupported" 2 "Error" 1 "TireLeakDetected" 0 "Ok" ;
VAL_ 2566845694 CTITireStatus_11 3 "NotSupported" 2 "Error" 1 "TireLeakDetected" 0 "Ok" ;
VAL_ 2566845694 CTITireStatus_10 3 "NotSupported" 2 "Error" 1 "TireLeakDetected" 0 "Ok" ;
VAL_ 2566845694 CTITireStatus_01 3 "NotSupported" 2 "Error" 1 "TireLeakDetected" 0 "Ok" ;
VAL_ 2566845694 TirePressThresholdDetection_33 7 "NotAvailable" 6 "ErrorIndicator" 5 "NotDefined" 4 "ExtrmUndrPrssTrPrssrIsAtALvlWhr" 3 "UndrPrssTrPrssrIsLwrThnThPrssrD" 2 "NWrnngPrssTrPrssrIsWthnThThrshl" 1 "OvrPrssTrPrssrIsHghrThnThPrssrD" 0 "ExtrmOvrPrssTrPrssrIsAtALvlWhrT" ;
VAL_ 2566845694 TirePressThresholdDetection_32 7 "NotAvailable" 6 "ErrorIndicator" 5 "NotDefined" 4 "ExtrmUndrPrssTrPrssrIsAtALvlWhr" 3 "UndrPrssTrPrssrIsLwrThnThPrssrD" 2 "NWrnngPrssTrPrssrIsWthnThThrshl" 1 "OvrPrssTrPrssrIsHghrThnThPrssrD" 0 "ExtrmOvrPrssTrPrssrIsAtALvlWhrT" ;
VAL_ 2566845694 TirePressThresholdDetection_31 7 "NotAvailable" 6 "ErrorIndicator" 5 "NotDefined" 4 "ExtrmUndrPrssTrPrssrIsAtALvlWhr" 3 "UndrPrssTrPrssrIsLwrThnThPrssrD" 2 "NWrnngPrssTrPrssrIsWthnThThrshl" 1 "OvrPrssTrPrssrIsHghrThnThPrssrD" 0 "ExtrmOvrPrssTrPrssrIsAtALvlWhrT" ;
VAL_ 2566845694 TirePressThresholdDetection_30 7 "NotAvailable" 6 "ErrorIndicator" 5 "NotDefined" 4 "ExtrmUndrPrssTrPrssrIsAtALvlWhr" 3 "UndrPrssTrPrssrIsLwrThnThPrssrD" 2 "NWrnngPrssTrPrssrIsWthnThThrshl" 1 "OvrPrssTrPrssrIsHghrThnThPrssrD" 0 "ExtrmOvrPrssTrPrssrIsAtALvlWhrT" ;
VAL_ 2566845694 TirePressThresholdDetection_23 7 "NotAvailable" 6 "ErrorIndicator" 5 "NotDefined" 4 "ExtrmUndrPrssTrPrssrIsAtALvlWhr" 3 "UndrPrssTrPrssrIsLwrThnThPrssrD" 2 "NWrnngPrssTrPrssrIsWthnThThrshl" 1 "OvrPrssTrPrssrIsHghrThnThPrssrD" 0 "ExtrmOvrPrssTrPrssrIsAtALvlWhrT" ;
VAL_ 2566845694 TirePressThresholdDetection_22 7 "NotAvailable" 6 "ErrorIndicator" 5 "NotDefined" 4 "ExtrmUndrPrssTrPrssrIsAtALvlWhr" 3 "UndrPrssTrPrssrIsLwrThnThPrssrD" 2 "NWrnngPrssTrPrssrIsWthnThThrshl" 1 "OvrPrssTrPrssrIsHghrThnThPrssrD" 0 "ExtrmOvrPrssTrPrssrIsAtALvlWhrT" ;
VAL_ 2566845694 TirePressThresholdDetection_21 7 "NotAvailable" 6 "ErrorIndicator" 5 "NotDefined" 4 "ExtrmUndrPrssTrPrssrIsAtALvlWhr" 3 "UndrPrssTrPrssrIsLwrThnThPrssrD" 2 "NWrnngPrssTrPrssrIsWthnThThrshl" 1 "OvrPrssTrPrssrIsHghrThnThPrssrD" 0 "ExtrmOvrPrssTrPrssrIsAtALvlWhrT" ;
VAL_ 2566845694 TirePressThresholdDetection_20 7 "NotAvailable" 6 "ErrorIndicator" 5 "NotDefined" 4 "ExtrmUndrPrssTrPrssrIsAtALvlWhr" 3 "UndrPrssTrPrssrIsLwrThnThPrssrD" 2 "NWrnngPrssTrPrssrIsWthnThThrshl" 1 "OvrPrssTrPrssrIsHghrThnThPrssrD" 0 "ExtrmOvrPrssTrPrssrIsAtALvlWhrT" ;
VAL_ 2566845694 TirePressThresholdDetection_00 7 "NotAvailable" 6 "ErrorIndicator" 5 "NotDefined" 4 "ExtrmUndrPrssTrPrssrIsAtALvlWhr" 3 "UndrPrssTrPrssrIsLwrThnThPrssrD" 2 "NWrnngPrssTrPrssrIsWthnThThrshl" 1 "OvrPrssTrPrssrIsHghrThnThPrssrD" 0 "ExtrmOvrPrssTrPrssrIsAtALvlWhrT" ;
VAL_ 2566845694 CTIWheelSensorStatus_00 3 "NotSupported" 2 "NotDefined" 1 "On" 0 "Off_IsolatedFromCTIPressCtrl" ;
VAL_ 2566845694 CTIWheelEndElectricalFault_00 3 "NotSupported" 2 "Error" 1 "NotDefined" 0 "Ok" ;
VAL_ 2566845694 CTITireStatus_00 3 "NotSupported" 2 "Error" 1 "TireLeakDetected" 0 "Ok" ;
VAL_ 2566821630 EngTrbWstgteActuator1TempStatus 7 "NotAvailable" 6 "Error" 5 "NotDefined" 4 "LowMostSevere" 3 "LowLeastSevere" 2 "InRange" 1 "HighLeastSevere" 0 "HighMostSevere" ;
VAL_ 2365484286 VehicleOverspeed 3 "NotAvailable" 2 "Error" 1 "Overspeed" 0 "NoOverspeed" ;
VAL_ 2365484286 VehicleMotion 3 "NotAvailable" 2 "Error" 1 "VehicleMotionDetected" 0 "VehicleMotionNotDetected" ;
VAL_ 2365484286 DirectionIndicator 3 "NotAvailable" 2 "Error" 1 "Reverse" 0 "Forward" ;
VAL_ 2365484286 TachographPerformance 3 "NotAvailable" 2 "Error" 1 "PerformanceAnalysis" 0 "NormalPerformance" ;
VAL_ 2365484286 HandlingInformation 3 "NotAvailable" 2 "Error" 1 "HandlingInformation" 0 "NoHandlingInformation" ;
VAL_ 2365484286 SystemEvent 3 "NotAvailable" 2 "Error" 1 "TachographEvent" 0 "NoTachographEvent" ;
VAL_ 2365484286 DriverCardDriver2 3 "NotAvailable" 2 "Error" 1 "DriverCardPresent" 0 "DriverCardNotPresent" ;
VAL_ 2365484286 Driver2TimeRelatedStates 15 "NotAvailable" 14 "Error" 13 "Other" 7 "1100Reserved" 6 "Limit616HReached" 5 "Limit515MinBefore16H" 4 "Limit49HReached" 3 "Limit315MinBefore9H" 2 "Limit24HReached" 1 "Limit115MinBefore4H" 0 "Normal_NoLimitsReached" ;
VAL_ 2365484286 DriverCardDriver1 3 "NotAvailable" 2 "Error" 1 "DriverCardPresent" 0 "DriverCardNotPresent" ;
VAL_ 2365484286 Driver1TimeRelatedStates 15 "NotAvailable" 14 "Error" 13 "Other" 7 "1100Reserved" 6 "Limit616HReached" 5 "Limit515MinBefore16H" 4 "Limit49HReached" 3 "Limit315MinBefore9H" 2 "Limit24HReached" 1 "Limit115MinBefore4H" 0 "Normal_NoLimitsReached" ;
VAL_ 2365484286 Driver2WorkingState 7 "NotAvailable" 6 "Error" 4 "101Reserved" 3 "DriveBehindWheel" 2 "WrkLdngUnldingWorkingInAnOffice" 1 "DriverAvailableShortBreak" 0 "RestSleeping" ;
VAL_ 2365484286 Driver1WorkingState 7 "NotAvailable" 6 "Error" 4 "101Reserved" 3 "DriveBehindWheel" 2 "WrkLdngUnldingWorkingInAnOffice" 1 "DriverAvailableShortBreak" 0 "RestSleeping" ;
VAL_ 2348876549 TrnsShftSlctorDisplayModeSwitch 3 "NotAvailable" 2 "Error" 1 "On" 0 "Off" ;
VAL_ 2348876549 TransMode4 3 "TakeNoAction" 2 "Reserved" 1 "Enable" 0 "Disable" ;
VAL_ 2348876549 TransMode3 3 "TakeNoAction" 2 "Reserved" 1 "Enable" 0 "Disable" ;
VAL_ 2348876549 TransMode2 3 "TakeNoAction" 2 "Reserved" 1 "Enable" 0 "Disable" ;
VAL_ 2348876549 TransMode1 3 "TakeNoAction" 2 "Reserved" 1 "Enable" 0 "Disable" ;
VAL_ 2348876549 DisengageDiffLockRqCentralRear 3 "TakeNoAction" 2 "Reserved" 1 "DisengageDiffLock" 0 "EngageDiffLock" ;
VAL_ 2348876549 DisengageDiffLockRqCentralFront 3 "TakeNoAction" 2 "Reserved" 1 "DisengageDiffLock" 0 "EngageDiffLock" ;
VAL_ 2348876549 DisengageDiffLockRqCentral 3 "TakeNoAction" 2 "Reserved" 1 "DisengageDiffLock" 0 "EngageDiffLock" ;
VAL_ 2348876549 DisengageDiffLockRqRearAxle2 3 "TakeNoAction" 2 "Reserved" 1 "DisengageDiffLock" 0 "EngageDiffLock" ;
VAL_ 2348876549 DisengageDiffLockRqRearAxle1 3 "TakeNoAction" 2 "Reserved" 1 "DisengageDiffLock" 0 "EngageDiffLock" ;
VAL_ 2348876549 DisengageDiffLockRqFrontAxle2 3 "TakeNoAction" 2 "Reserved" 1 "DisengageDiffLock" 0 "EngageDiffLock" ;
VAL_ 2348876549 DisengageDiffLockRqFrontAxle1 3 "TakeNoAction" 2 "Reserved" 1 "DisengageDiffLock" 0 "EngageDiffLock" ;
VAL_ 2348876549 TransRqedGear 60 "Reserved" 61 "Reserved" 222 "NeutralSelectorPos" 223 "ReverseSelectorPos" 224 "PsUnknownAnd_OrNoButtonsPressed" 225 "PrssOfMmntryBttnTRslctCrrentPos" 226 "BtwnRvrsAndPrkShiftSelectorPoss" 227 "BtwnNtrlAndRvrsShftSelectorPoss" 228 "BtwnDrvAndNtrlShiftSelectorPoss" 229 "BtwnD1AndDriveShiftSelectorPoss" 230 "BetweenD2AndD1ShiftSelectorPoss" 231 "BetweenD3AndD2ShiftSelectorPoss" 232 "BetweenD4AndD3ShiftSelectorPoss" 233 "BetweenD5AndD4ShiftSelectorPoss" 234 "BetweenD6AndD5ShiftSelectorPoss" 235 "BetweenD7AndD6ShiftSelectorPoss" 236 "BtwnTwoForwardShiftSelectorPoss" 237 "BtwnTwoReverseShiftSelectorPoss" 238 "BetweenTwoShiftSelectorPoss" 239 "D77thFrwrdSlctrPsRfrncdFrmDrive" 240 "D66thFrwrdSlctrPsRfrncdFrmDrive" 241 "D55thFrwrdSlctrPsRfrncdFrmDrive" 242 "D44thFrwrdSlctrPsRfrncdFrmDrive" 243 "D33rdFrwrdSlctrPsRfrncdFrmDrive" 244 "D22ndFrwrdSlctrPsRfrncdFrmDrive" 245 "D11stFrwrdSlctrPsRfrncdFrmDrive" 246 "Downshift2GearsFromCurrentPos" 247 "Downshift1GearFromCurrentPos" 248 "Upshift2GearsFromCurrentPos" 249 "Upshift1GearFromCurrentPos" 250 "ForwardLowPos" 251 "ParkPos" 252 "ForwardDrivePos" 253 "HoldCurrentGear" ;
VAL_ 2348876549 DisengageDrivelineRq 2 "Reserved" 3 "TakeNoAction" 1 "DisengageDriveline" 0 "AllowDrivelineEngagement" ;
VAL_ 2348876549 TransGearShiftInhibitRq 2 "Reserved" 3 "TakeNoAction" 1 "GearShiftsAreInhibited" 0 "GearShiftsAreAllowed" ;
VAL_ 2348876549 TrnsTrqConverterLockupDisableRq 3 "TakeNoAction" 2 "Reserved" 1 "DisableTorqueConverterLockup" 0 "AllowTorqueConverterLockup" ;
VAL_ 2348876549 TransRqedLaunchGear 15 "NotAvailable" 14 "Error" 13 "Reserved" 12 "LaunchVehicleInReverse4" 11 "LaunchVehicleInReverse3" 10 "LaunchVehicleInReverse2" 9 "LaunchVehicleInReverse1" 8 "LaunchVehicleIn8thGear" 7 "LaunchVehicleIn7thGear" 6 "LaunchVehicleIn6thGear" 5 "LaunchVehicleIn5thGear" 4 "LaunchVehicleIn4thGear" 3 "LaunchVehicleIn3rdGear" 2 "LaunchVehicleIn2ndGear" 1 "LaunchVehicleIn1stGear" 0 "NSpcfcLnchGrRqdUsDfltLaunchGear" ;
VAL_ 2348876549 TransReverseGearShiftInhibitRq 3 "TakeNoAction" 2 "Reserved" 1 "InhbtShftsIntRvrsGrAndShftTrnsT" 0 "AllowShiftsIntoReverseGear" ;
VAL_ 2348876549 TransMode8 3 "TakeNoAction" 2 "Reserved" 1 "Enable" 0 "Disable" ;
VAL_ 2348876549 TransMode7 3 "TakeNoAction" 2 "Reserved" 1 "Enable" 0 "Disable" ;
VAL_ 2348876549 TransMode6 3 "TakeNoAction" 2 "Reserved" 1 "Enable" 0 "Disable" ;
VAL_ 2348876549 TransMode5 3 "TakeNoAction" 2 "Reserved" 1 "Enable" 0 "Disable" ;
VAL_ 2566839552 EngTurboOilLevelSwitch 3 "NotAvailable" 2 "Error" 1 "OilPresentAtTurbo" 0 "NoOilPresentAtTurbo" ;
VAL_ 2566841344 EngOverspeedTest 3 "NotAvailable" 2 "Reserved" 1 "EngOverspeedTestActive" 0 "EngOverspeedTestNotActive" ;
VAL_ 2566841344 EngAirShutoffCmdStatus 0 "ArShtffDsbldNtAttmptngTShtffEng" 3 "NotAvailable" 2 "Reserved" 1 "ArShtffEnbldAttmptngTShtffEngAr" ;
VAL_ 2566841344 EngAlarmOutputCmdStatus 3 "NotAvailable" 2 "Reserved" 1 "EngAlarmOutputCmdActive" 0 "EngAlarmOutputCmdNotActive" ;
VAL_ 2566841344 EngAlarmAcknowledge 3 "NotAvailable" 2 "Error" 1 "EngAlarmAcknowledgeActive" 0 "EngAlarmAcknowledgeNotActive" ;
VAL_ 2566841344 EngProtectionSystemConfig 3 "NotAvailable" 2 "Error" 1 "EnabledInCalib" 0 "DisabledInCalib" ;
VAL_ 2566841344 EngProtectionSystemTimerState 3 "NotAvailable" 2 "Error" 1 "Active" 0 "Inactive" ;
VAL_ 2566841344 EngPrtectionSystemTimerOverride 3 "NotAvailable" 2 "Error" 1 "Active" 0 "Inactive" ;
VAL_ 2566841344 EngPrtctnSystmApprchingShutdown 3 "NotAvailable" 2 "Error" 1 "Approaching" 0 "NotApproaching" ;
VAL_ 2566841344 EngWaitToStartLamp 3 "NotAvailable" 2 "Error" 1 "On" 0 "Off" ;
VAL_ 2566841344 RefrigerantHighPressSwitch 3 "NotAvailable" 2 "Error" 1 "PrssTHghCmprssrCltchMyBDsngaged" 0 "PressNormal" ;
VAL_ 2566841344 RefrigerantLowPressSwitch 3 "NotAvailable" 2 "Error" 1 "PrssTLwCmprssrCltchMyBDsengaged" 0 "PressNormal" ;
VAL_ 2566841344 A_CHighPressFanSwitch 3 "NotAvailable" 2 "Error" 1 "PressHighFanMayBeEngaged" 0 "PressNormal" ;
VAL_ 2566841344 EngIdleShutdownTimerFunction 3 "NotAvailable" 2 "Error" 1 "EnabledInCalib" 0 "DisabledInCalib" ;
VAL_ 2566841344 EngIdleShutdownTimerState 3 "NotAvailable" 2 "Error" 1 "Active" 0 "Inactive" ;
VAL_ 2566841344 EngIdleShutdownTimerOverride 3 "NotAvailable" 2 "Error" 1 "Active" 0 "Inactive" ;
VAL_ 2566841344 EngIdleShutdownDriverAlertMode 3 "NotAvailable" 2 "Error" 1 "Active" 0 "Inactive" ;
VAL_ 2566841344 PTOShutdownHasShutdownEng 3 "NotAvailable" 2 "Error" 1 "Yes" 0 "No" ;
VAL_ 2566841344 EngPrtctnSystmHasShutdownEngine 3 "NotAvailable" 2 "Error" 1 "Yes" 0 "No" ;
VAL_ 2566841344 EngIdlShutdownHasShutdownEngine 3 "NotAvailable" 2 "Error" 1 "Yes" 0 "No" ;
VAL_ 2566841344 EngAirShutoffStatus 3 "NotAvailable" 2 "Error" 1 "AirFlowRestricted" 0 "AirFlowAllowedToEng" ;
VAL_ 2566847486 DrvlneRetarderOverheatIndicator 3 "NotAvailable" 2 "DrvlnRtrdrOvrhtIndctrIsFlashing" 1 "DrvlnRtrdrOvrhtIndctrIsOnCntnsl" 0 "DrvlnRtrdrOvrheatIndicatorIsOff" ;
VAL_ 2631859966 EngBuildHoursReset 2 "Reserved" 3 "TakeNoAction" 1 "Reset" 0 "DoNotReset" ;
VAL_ 2631859966 TripGroup2Proprietary 2 "Reserved" 3 "NotApplicable" 1 "Reset" 0 "TakeNoAction" ;
VAL_ 2631859966 TripGroup1 2 "Reserved" 3 "NotApplicable" 1 "Reset" 0 "TakeNoAction" ;
VAL_ 2631859966 SteerStraightAheadPosReset 3 "NotApplicable" 2 "ReservedTakeNoAction" 1 "Reset" 0 "TakeNoActionDoNotReset" ;
VAL_ 2566840591 RetarderLocation 15 "NotAvailable" 14 "Other" 6 "1101NotDefined" 5 "Trailer" 4 "Driveline" 3 "TransOutput" 2 "TransInput" 1 "EngExhaustBrake" 0 "EngCompressionReleaseBrake" ;
VAL_ 2566840591 RetarderType 15 "NotAvailable" 14 "Other" 5 "1101NotDefined" 4 "Exhaust" 3 "CompressionRelease" 2 "CooledFriction" 1 "Hyd" 0 "Electric_Magnetic" ;
VAL_ 2566844416 OprtrEngPTOGvrnrMmrySlectSwitch 3 "notAvailable" 2 "error" 1 "PTOSetSpeedMemory2Selected" 0 "PTOSetSpeedMemory1Selected" ;
VAL_ 2566844416 EngRmtPTOGvrnrVrblSpdCtrlSwitch 3 "NotAvailable" 2 "Error" 1 "On" 0 "Off" ;
VAL_ 2566844416 EngRmtPTOGvrnrPrprgrmmdSpdCtrlSw 3 "NotAvailable" 2 "Error" 1 "On" 0 "Off" ;
VAL_ 2566844416 EngPTOGvrnrCst_DecelerateSwitch 3 "NotAvailable" 2 "Error" 1 "On" 0 "Off" ;
VAL_ 2566844416 EngPTOGovernorSetSwitch 3 "NotAvailable" 2 "Error" 1 "On" 0 "Off" ;
VAL_ 2566844416 EngPTOGovernorResumeSwitch 3 "NotAvailable" 2 "Error" 1 "On" 0 "Off" ;
VAL_ 2566844416 EngPTOGovernorEnableSwitch 3 "NotAvailable" 2 "Error" 1 "On" 0 "Off" ;
VAL_ 2566844416 EngPTOGovernorAccelerateSwitch 3 "NotAvailable" 2 "Error" 1 "On" 0 "Off" ;
VAL_ 2566844416 RmtPTOPrprgrmmdSpeedCtrlSwitch2 3 "NotAvailable" 2 "Error" 1 "On" 0 "Off" ;
VAL_ 2566844416 AuxInputIgnoreSwitch 3 "NotAvailable" 2 "Error" 1 "On" 0 "Off" ;
VAL_ 2566770174 RearWasherFunction 7 "NotAvailable" 4 "110Reserved" 3 "High" 2 "Medium" 1 "Low" 0 "Off" ;
VAL_ 2566770174 FrontOperatorWasherSwitch 7 "NotAvailable" 4 "110Reserved" 3 "High" 2 "Medium" 1 "Low" 0 "Off" ;
VAL_ 2566770174 FrontNonoperatorWasherSwitch 7 "NotAvailable" 4 "110Reserved" 3 "High" 2 "Medium" 1 "Low" 0 "Off" ;
VAL_ 2566770174 RearWiperSwitch 7 "1110Reserved" 6 "Mist" 5 "Delayed2" 4 "Delayed1" 2 "Medium" 15 "NotAvailable" 3 "High" 1 "Low" 0 "Off" ;
VAL_ 2566770174 FrontOperatorWiperSwitch 7 "1110Reserved" 6 "Mist" 5 "Delayed2" 4 "Delayed1" 2 "Medium" 15 "NotAvailable" 3 "High" 1 "Low" 0 "Off" ;
VAL_ 2566770174 FrontNonoperatorWiperSwitch 15 "NotAvailable" 7 "1110Reserved" 6 "Mist" 5 "Delayed2" 4 "Delayed1" 3 "High" 2 "Medium" 1 "Low" 0 "Off" ;
VAL_ 2566769662 EngAltDroopAuxInputSelect 15 "NotAvailable" 14 "ErrorCondition" 1 "thr1101OnOfAltDrpSttng1Thrgh13I" 0 "NormalDroopSettingIsSelected" ;
VAL_ 2566769662 EngAltDroopRemoteAccelSelect 15 "NotAvailable" 14 "ErrorCondition" 1 "thr1101OnOfAltDrpSttng1Thrgh13I" 0 "NormalDroopSettingIsSelected" ;
VAL_ 2566769662 EngAltDroopAccel2Select 15 "NotAvailable" 14 "ErrorCondition" 1 "thr1101OnOfAltDrpSttng1Thrgh13I" 0 "NormalDroopSettingIsSelected" ;
VAL_ 2566769662 EngAltDroopAccel1Select 15 "NotAvailable" 14 "ErrorCondition" 1 "thr1101OnOfAltDrpSttng1Thrgh13I" 0 "NormalDroopSettingIsSelected" ;
VAL_ 2566769662 EngAltRatingSelect 1 "IndctsThtAltPwrFling1IsSelected" 0 "IndctsThtMxPwrFuelingIsSelected" ;
VAL_ 2566769662 EngAltLowIdleSwitch 3 "NotAvailableUnused" 2 "Error" 1 "AltLowIdlePointIsSelected" 0 "DefaultLowIdlePointIsSelected" ;
VAL_ 2566769662 EngSynchronizationSwitch 3 "NotAvailableUnused" 2 "Error" 1 "FunctionalityIsEnabled" 0 "FunctionalityIsDisabled" ;
VAL_ 2566769662 EngAuxGovernorSwitch 2 "ErrorCondition" 1 "AuxGovernorIsEnabled" 0 "AuxGovernorIsDisabled" 3 "NotAvailable" ;
VAL_ 2566768638 EngAltDroopAuxInputSelectState 15 "NotAvailable" 14 "SAEReserved" 1 "thr1101CtrlSttIsOnOfAltDrpSttng" 0 "CtrlStateIsNormalDroopSetting" ;
VAL_ 2566768638 EngAltDrpRemoteAccelSelectState 15 "NotAvailable" 14 "SAEReserved" 1 "thr1101CtrlSttIsOnOfAltDrpSttng" 0 "CtrlStateIsNormalDroopSetting" ;
VAL_ 2566768638 EngAltDroopAccel2SelectState 15 "NotAvailable" 14 "SAEReserved" 1 "thr1101CtrlsSttIsOnOfAltDrpSttn" 0 "CtrlsStateIsNormalDroopSetting" ;
VAL_ 2566768638 EngAltDroopAccel1SelectState 15 "NotAvailable" 14 "SAEReserved" 1 "thr1101CtrlSttIsOnOfAltDrpSttng" 0 "CtrlStateIsNormalDroopSetting" ;
VAL_ 2566768638 EngAltRatingSelectState 1 "CtrlStateIsAltPowerFueling1" 0 "CtrlStateIsMaxPowerFueling" ;
VAL_ 2566768638 EngAltLowIdleSelectState 3 "NotAvailable" 2 "SAEReserved" 1 "AltIdleState" 0 "NormalIdleState" ;
VAL_ 2566768638 EngMultiUnitSyncState 3 "NotAvailable" 2 "SAEReserved" 1 "CtrlStateIsFunctionalityEnabled" 0 "CtrlStteIsFunctionalityDisabled" ;
VAL_ 2566768638 EngAuxGovernorState 3 "NotAvailable" 2 "SAEReserved" 1 "CtrlStateIsAuxGovernorEnabled" 0 "CtrlStateIsAuxGovernorDisabled" ;
VAL_ 2365443326 HighLowBeamSwitch 3 "NotAvailable" 2 "Error" 1 "HighBeamSelected" 0 "LowBeamSelected" ;
VAL_ 2365443326 HazardLightSwitch 3 "NotAvailable" 2 "Error" 1 "HazardLampsToBeFlashing" 0 "HazardLampsToBeOff" ;
VAL_ 2365443326 TurnSignalSwitch 2 "RightTurnToBeFlashing" 15 "NotAvailable" 14 "Error" 3 "1101Reserved" 1 "LeftTurnToBeFlashing" 0 "NoTurnBeingSignaled" ;
VAL_ 2365443326 MainLightSwitch 9 "1101Reserved" 8 "DlydOffPsByWhchThOprtrSlctsThtA" 4 "0111Reserved" 2 "HdlghtOnPsByWhchThOprtrSlctsTht" 15 "NotAvailable" 14 "Error" 3 "HdlghtAndPrkOnPsByWhchThOprtrSl" 1 "PrkOnPsByWhchThOprtrSlctsThtThP" 0 "OffPsByWhchThOprtrSlctsThtNnOfT" ;
VAL_ 2365443326 WorkLightSwitch 5 "1101Reserved" 4 "WrkLghtCmbntn4OnPsByWhchThOprtr" 2 "WrkLghtCmbntn2OnPsByWhchThOprtr" 15 "NotAvailable" 14 "Error" 3 "WrkLghtCmbntn3OnPsByWhchThOprtr" 1 "WrkLghtCmbntn1OnPsByWhchThOprtr" 0 "OffPsByWhchThOprtrSlctsThtNnOfT" ;
VAL_ 2566802686 BlackOutWorkLampSelect 3 "NotSupported" 2 "Reserved" 1 "On" 0 "Off" ;
VAL_ 2566802686 NightVisionIlluminatorSelect 3 "NotSupported" 2 "Reserved" 1 "On" 0 "Off" ;
VAL_ 2566802686 BlackOutBrake_StopLampSelect 3 "NotSupported" 2 "Reserved" 1 "On" 0 "Off" ;
VAL_ 2566802686 ConvoyDrivingLampSelect 3 "NotSupported" 2 "Reserved" 1 "On" 0 "Off" ;
VAL_ 2566802686 ConvoyLampSelect 3 "NotSupported" 2 "Reserved" 1 "On" 0 "Off" ;
VAL_ 2566802686 FrontBlackOutMarkerLampSelect 3 "NotSupported" 2 "Reserved" 1 "On" 0 "Off" ;
VAL_ 2566802686 RearBlackOutMarkerSelect 3 "NotSupported" 2 "Reserved" 1 "On" 0 "Off" ;
VAL_ 2566774014 SlowVesselModeStatus 3 "TakeNoAction" 2 "Reserved" 1 "SlowVesselModeIsACTIVE" 0 "SlowVesselModeIsOFF" ;
VAL_ 2566774014 TrollingModeStatus 3 "TakeNoAction" 2 "Reserved" 1 "TrollingModeIsACTIVE" 0 "TrollingModeIsOFF" ;
VAL_ 2566774014 EngThrttlSynchrnztionModeStatus 15 "TakeNoAction" 5 "1110Reserved" 4 "SynchronizedMaster" 3 "SynchronizedStarboard" 2 "SynchronizedPort" 1 "SynchronizedCenter" 0 "NotSynchronized" ;
VAL_ 2432595710 DisplayDeadbands 15 "NotAvailable" 3 "1110Reserved" 2 "Wide_24mm" 1 "Standard_12mm" 0 "Narrow_45mm" ;
VAL_ 2432595710 LEDPatternCtrl 15 "NotAvailable" 3 "1110Reserved" 2 "7Channel" 1 "Offset" 0 "5Channel" ;
VAL_ 2432595710 LEDDisplayDeadbandCtrl 15 "NotAvailableNotApplicable" 5 "1110Reserved" 4 "_1Mm" 3 "_5Mm" 2 "_24Mm" 1 "_12Mm" 0 "_45Mm" ;
VAL_ 2432595710 LEDDisplayModeCtrl 15 "NotAvailableNotApplicable" 3 "1110Reserved" 2 "CenterOnGradeDisplayMode2" 1 "OffsetOnGradeDisplayMode" 0 "CenterOnGradeDisplayMode1" ;
VAL_ 2432595710 LEDDisplayData1 511 "NotAvailable" 254 "Error" 159 "NoData" 149 "HighCoarse" 148 "HighMedium_Coarse" 147 "HighMedium" 146 "HighMedium_Fine" 145 "HighFine" 144 "OnGrade" 132 "LowFine" 131 "LowMedium_Fine" 130 "LowMedium" 129 "LowMedium_Coarse" 128 "LowCoarse" 32 "LowCoarseLEDOn" 16 "LowFineLEDOn" 8 "OngradeLEDOn" 4 "HighFineLEDOn" 2 "HighCoarseLEDOn" ;
VAL_ 2365486590 LaserReceiverType 1 "LinearLaserReceiver" 0 "Reserved" ;
VAL_ 2365485566 LaserTracerInformation 32 "Curb" 16 "Stringline" 8 "PreviousPass" 4 "ValidTarget" 2 "LaserIsReady" 1 "LaserPowerIsOn" ;
VAL_ 2365485566 LEDDisplayData2 511 "NotAvailable" 254 "Error" 159 "NoData" 149 "HighCoarse" 148 "HighMedium_Coarse" 147 "HighMedium" 146 "HighMedium_Fine" 145 "HighFine" 144 "OnGrade" 132 "LowFine" 131 "LowMedium_Fine" 130 "LowMedium" 129 "LowMedium_Coarse" 128 "LowCoarse" 64 "RightLEDOn" 32 "LeftLEDOn" 16 "DownLEDOn" 8 "UpLEDOn" 4 "OngradeCLEDOn" 2 "OngradeBLEDOn" 1 "OngradeALEDOn" ;
VAL_ 2364542462 SdshftDsrdBldOffsetOperatorCtrl 15 "NotInstalled" 14 "ErrorIndicator" 4 "1101Reserved" 3 "AutomaticOperatorCtrlRq" 2 "ManualOperatorCtrlRq" 0 "NoOperatorCtrlRq" 1 "MomentaryOperatorCtrlRq" ;
VAL_ 2364542462 SdshftBldCtrlMdeOperatorControl 15 "NotInstalled" 14 "ErrorIndicator" 3 "1101Reserved" 2 "DecrementOperatorCtrlRq" 0 "NoOperatorCtrlRq" 1 "IncrementOperatorCtrlRq" ;
VAL_ 2364542462 RghtDsrdBladeOffsetOperatorCtrl 15 "NotInstalled" 14 "ErrorIndicator" 3 "1101Reserved" 2 "DecrementOperatorCtrlRq" 0 "NoOperatorCtrlRq" 1 "OprtrCtrlSttCnBRdInTwWysOnMthdU" ;
VAL_ 2364542462 RghtBldeCtrlModeOperatorControl 15 "NotInstalled" 14 "ErrorIndicator" 3 "AutomaticOperatorCtrlRq" 2 "ManualOperatorCtrlRq" 0 "NoChange" 1 "MomentaryOperatorCtrlRq" ;
VAL_ 2364542462 LftDsredBladeOffsetOperatorCtrl 15 "NotInstalled" 14 "ErrorIndicator" 3 "1101Reserved" 2 "DecrementOperatorCtrlRq" 0 "NoOperatorCtrlRq" 1 "OprtrCtrlSttCnBRdInTwWysOnMthdU" ;
VAL_ 2364542462 LftBladeCtrlModeOperatorControl 15 "NotInstalled" 14 "ErrorIndicator" 12 "1101Reserved" 3 "AutomaticOperatorCtrlRq" 2 "ManualOperatorCtrlRq" 0 "NoChange" 1 "OprtrCtrlSttCnBRdInTwWysOnMthdU" ;
VAL_ 2364542462 BladeAutoModeCmd 15 "NotSupported" 14 "ErrorIndicator" 4 "AutoNotAllowed" 3 "SrvcMdAtAllwdOnlyDrngSrvceModes" 2 "SspndAtTmprarilySuspendAutoMode" 1 "ActvtyAllwsAtMstDtctOprtrBfrAtA" 0 "AutoAllowed" ;
VAL_ 2364542462 DesiredGradeOffsetSwitch 15 "NotInstalled" 14 "ErrorIndicator" 2 "DecrementButtonPressed" 0 "NoButtonPressed" 1 "SwtchSttCnBRdInTwWysOnMthdUssTh" ;
VAL_ 2364542462 BladeCtrlModeSwitch 15 "NotInstalled" 14 "ErrorIndicator" 3 "AutomaticButtonPressed" 2 "ManualButtonPressed" 0 "NoButtonPressed" 1 "SwtchSttCnBRdInTwWysOnMthdUssTh" ;
VAL_ 2364542462 StElvtnSnsor2ReferenceElevation 3 "DontCare_TakeNoAction" 2 "Reserved" 1 "SetReferenceElevation" 0 "DoNotSetReferenceElevation" ;
VAL_ 2364542462 StElvtnSnsor1ReferenceElevation 3 "DontCare_TakeNoAction" 2 "Reserved" 1 "SetReferenceElevation" 0 "DoNotSetReferenceElevation" ;
VAL_ 2633937918 FlexibleFuelPercentage 4 "MansAlcoholAsFuelAndNothingElse" ;
VAL_ 2633883646 FrontWheelDriveActuatorStatus 3 "NotAvailable" 2 "Error" 1 "FrontWheelDriveActuatorEngaged" 0 "FrntWhelDriveActuatorNotEngaged" ;
VAL_ 2633880062 FMSstandardRqsSupported 3 "DontCare" 2 "Reserved" 1 "OnRqModeIsSupported" 0 "OnRqModeIsNotSupported" ;
VAL_ 2633880062 FMSstandardDiagnosticsSupported 3 "DontCare" 2 "Reserved" 1 "DiagnosticsIsSupported" 0 "DiagnosticsIsNotSupported" ;
VAL_ 2566806526 LnDprtureIndicationEnableStatus 3 "NotUsed" 2 "Reserved" 1 "LaneDepartureIndicationEnabled" 0 "LaneDepartureIndicationDisabled" ;
VAL_ 2566806526 LaneTrackingStatusLeftSide 3 "DontCare_TakeNoAction" 2 "Reserved" 1 "TrackingLeftSide" 0 "NotTrackingLeftSide" ;
VAL_ 2566806526 LaneTrackingStatusRightSide 3 "DontCare_TakeNoAction" 2 "Reserved" 1 "TrackingRightSide" 0 "NotTrackingRightSide" ;
VAL_ 2431649790 LaneDepartureImminentLeftSide 3 "NotUsed" 2 "Reserved" 1 "Imminent" 0 "NotImminent" ;
VAL_ 2431649790 LaneDepartureImminentRightSide 3 "NotUsed" 2 "Reserved" 1 "Imminent" 0 "NotImminent" ;
VAL_ 2431649790 LaneDepartureRight 3 "TakeNoAction" 2 "Reserved" 1 "MddlOfVhclDprtsThLnTThRightSide" 0 "MddlOfVhclDsNtDprtThLnTThRghtSd" ;
VAL_ 2431649790 LaneDepartureLeft 3 "TakeNoAction" 2 "Reserved" 1 "MddlOfVhclDprtsThLnTTheLeftSide" 0 "MddlOfVhclDsNtDprtThLnTThLftSde" ;
VAL_ 2633929214 EngFuelLeakage2 3 "NotAvailable" 2 "Error" 1 "LeakageDetected" 0 "NoLeakageDetected" ;
VAL_ 2633929214 EngFuelLeakage1 3 "NotAvailable" 2 "Error" 1 "LeakageDetected" 0 "NoLeakageDetected" ;
VAL_ 2566831360 FanDriveState 15 "NotAvailable" 14 "Other" 13 "EngBrake" 12 "Timer" 11 "A_CSystem" 10 "TransRetarder" 9 "ManualCtrl" 8 "ReverseOperation" 7 "DefaultOperation" 6 "ExcessiveHydOilTemp" 5 "ExcessiveTransOilTemp" 4 "ExcessiveEngCoolantTemp" 3 "ExcessiveEngOilTemp" 2 "ExcessiveEngAirTemp" 1 "EngSystemGeneral" 0 "FanOff" ;
VAL_ 2566820094 EngTorqueLimitFeature 7 "NotAvailable" 5 "110Reserved" 4 "CurrentTorqueRating" 3 "PreviousTorqueRating" 2 "FirstTorqueRating" 1 "HighestTorqueRating" 0 "Reserved" ;
VAL_ 2566820094 TorqueLimitingFeatureStatus 3 "NotAvailable" 2 "Error" 1 "Enabled" 0 "Disabled" ;
VAL_ 2364541955 TransTorqueConverterRatio 64256 "RatioCannotBeProperlyDetermined" ;
VAL_ 2566801923 TrnsRvrseGearShiftInhibitStatus 3 "NotAvailable" 2 "Error" 1 "RvrsGrShftsArCurrentlyInhibited" 0 "RvrsGrShiftsAreCurrentlyAllowed" ;
VAL_ 2566801923 TrnsCrrntRangeDisplayBlankState 3 "NotSupported" 2 "Error" 1 "Blanked" 0 "NotBlanked" ;
VAL_ 2566801923 TransWarningIndicator 3 "NotAvailable" 2 "TransWarningIndicatorIsFlashing" 1 "TrnsWrnngIndctrIsOnContinuously" 0 "TransWarningIndicatorIsOff" ;
VAL_ 2566801923 TransMode8Indicator 3 "TakeNoAction" 2 "Reserved" 1 "Enable" 0 "Disable" ;
VAL_ 2566801923 TransMode7Indicator 3 "TakeNoAction" 2 "Reserved" 1 "Enable" 0 "Disable" ;
VAL_ 2566801923 TransMode6Indicator 3 "TakeNoAction" 2 "Reserved" 1 "Enable" 0 "Disable" ;
VAL_ 2566801923 TransMode5Indicator 3 "TakeNoAction" 2 "Reserved" 1 "Enable" 0 "Disable" ;
VAL_ 2566801923 TransMode1Indicator 3 "NotAvailable" 2 "Error" 1 "TransMode1Active" 0 "TransMode1NotActive" ;
VAL_ 2566801923 TransMode2Indicator 3 "NotAvailable" 2 "Error" 1 "TransMode2Active" 0 "TransMode2NotActive" ;
VAL_ 2566801923 TransMode3Indicator 3 "NotAvailable" 2 "Error" 1 "TransMode3Active" 0 "TransMode3NotActive" ;
VAL_ 2566801923 TransMode4Indicator 3 "NotAvailable" 2 "Error" 1 "TransMode4Active" 0 "TransMode4NotActive" ;
VAL_ 2566801923 TransShiftInhibitIndicator 3 "TakeNoAction" 2 "Reserved" 1 "ActiveShiftIsInhibited" 0 "InactiveShiftIsNotInhibited" ;
VAL_ 2566801923 TransEngCrankEnable 3 "NotAvailable" 2 "Error" 1 "CrnkngEnbldEngCrnkngIsAllwdByTr" 0 "CrnkngDsbldEngCrnkngIsPrhbtdByT" ;
VAL_ 2566801923 ActiveShiftConsoleIndicator 3 "NotAvailable" 2 "Reserved" 1 "SecondShiftConsoleIsActive" 0 "PrimaryShiftConsoleIsActive" ;
VAL_ 2566801923 TransReadyForBrakeRelease 3 "NotAvailable" 2 "Error" 1 "TransReadyForBrakeRelease" 0 "TransNotReadyForBrakeRelease" ;
VAL_ 2566801923 TransRqedRangeDisplayFlashState 3 "TakeNoAction" 2 "Reserved" 1 "ActvTrnsRqdRngDsplyShldBFlshing" 0 "InctvTrnsRqdRngDsplyShldNtBFlsh" ;
VAL_ 2566801923 TransRqedRangeDisplayBlankState 3 "TakeNoAction" 2 "Reserved" 1 "ActvTrnsRqdRngDsplyShldBBlanked" 0 "InctvTrnsRqdRngDsplyShldNtBBlnk" ;
VAL_ 2566801923 TransServiceIndicator 3 "NotAvailable" 2 "ServiceIndicatorFlashing" 1 "ServiceIndicatorOn" 0 "SeviceIndicatorOff" ;
VAL_ 2633935619 LowestPossibleGear 251 "Park" ;
VAL_ 2633935619 HighestPossibleGear 251 "Park" ;
VAL_ 2633935619 RecommendedGear 251 "Park" ;
